VERSION "12.2.7"

NS_ :

BS_:

BU_: AMP CPD EASC HUD MHU XGW_Info PAS_Info PAS_LITE FCAM_Info

BO_ 676 SVC_EHC_EHC_2: 8 XGW_Info
  SG_ ID2 M : 0|8@1+ (1,0) [0|0] "" Vector__XXX,MHU
  SG_ ECU_ID_WUPREG m39 : 8|8@1+ (1,0) [0|127] "" Vector__XXX
  SG_ ID_FN_INQY m1 : 8|16@1+ (1,0) [0|0] "" Vector__XXX
  SG_ ID_FN_RQ_BUS m12 : 8|16@1+ (1,0) [0|0] "" Vector__XXX
  SG_ NO_CC_MESS_EXT m65 : 8|16@1+ (1,0) [0|65534] "" Vector__XXX
  SG_ NO_CC_MESS_STD m64 : 8|16@1+ (1,0) [0|65534] "" MHU,Vector__XXX
  SG_ WACA m39 : 16|8@1+ (1,0) [0|0] "" Vector__XXX
  SG_ ID_RQ_BUS m12 : 24|8@1+ (1,0) [0|0] "" Vector__XXX
  SG_ ST_CC_MESS_EXT m65 : 24|2@1+ (1,0) [0|0] "" Vector__XXX
  SG_ ST_CC_MESS_STD m64 : 24|2@1+ (1,0) [0|0] "" MHU
  SG_ TRANF_CC_MESS_EXT m65 : 26|4@1+ (1,0) [0|14] "" Vector__XXX
  SG_ TRANF_CC_MESS_STD m64 : 26|4@1+ (1,0) [0|14] "" MHU
  SG_ ST_IDC_CCLK_CC_MESS_EXT m65 : 30|2@1+ (1,0) [0|0] "" Vector__XXX
  SG_ ST_IDC_CCLK_CC_MESS_STD m64 : 30|2@1+ (1,0) [0|0] "" MHU
  SG_ NO_FRM_CC_MESS_EXT m65 : 32|4@1+ (1,0) [0|14] "" Vector__XXX
  SG_ ST_RQ_BUS m12 : 32|4@1+ (1,0) [0|0] "" Vector__XXX
  SG_ QUAN_FRM_CC_MESS_EXT m65 : 36|4@1+ (1,0) [0|14] "" Vector__XXX
  SG_ ST_LAW_RQ m12 : 36|4@1+ (1,0) [0|0] "" Vector__XXX
  SG_ DUR_FLLUPT m12 : 40|8@1+ (1,0) [0|254] "min" Vector__XXX
  SG_ UTDT_CC_MESS m65 : 40|24@1+ (1,0) [0|0] "" Vector__XXX

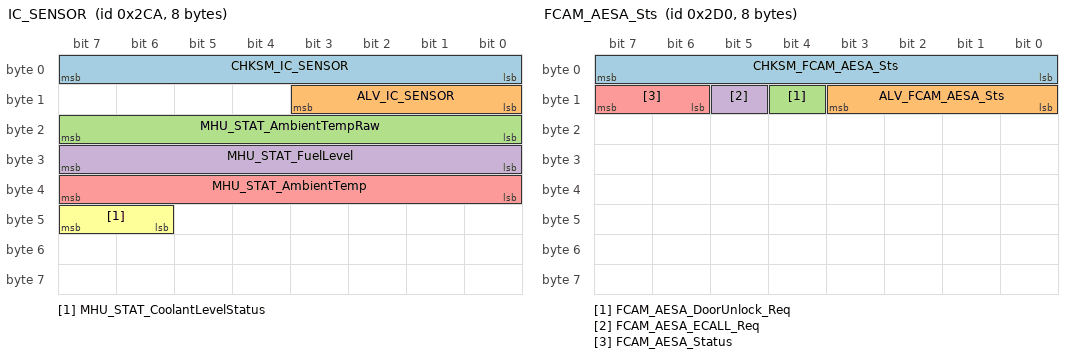
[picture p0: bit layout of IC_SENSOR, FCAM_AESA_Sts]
BO_ 714 IC_SENSOR: 8 MHU
  SG_ CHKSM_IC_SENSOR : 7|8@0+ (1,0) [0|255] "" AMP,CPD,EASC,HUD,XGW_Info,PAS_Info,FCAM_Info,PAS_LITE
  SG_ ALV_IC_SENSOR : 11|4@0+ (1,0) [0|14] "" AMP,CPD,EASC,HUD,XGW_Info,PAS_Info,FCAM_Info,PAS_LITE
  SG_ MHU_STAT_AmbientTempRaw : 23|8@0+ (0.5,-40) [-40|85] "°C" AMP,CPD,EASC,HUD,XGW_Info,PAS_Info,FCAM_Info
  SG_ MHU_STAT_FuelLevel : 31|8@0+ (1,0) [0|100] "l" AMP,CPD,EASC,HUD,XGW_Info,PAS_Info,FCAM_Info
  SG_ MHU_STAT_AmbientTemp : 39|8@0+ (0.5,-40) [-40|85] "Degree C" AMP,CPD,EASC,HUD,XGW_Info,PAS_Info,FCAM_Info,PAS_LITE
  SG_ MHU_STAT_CoolantLevelStatus : 47|2@0+ (1,0) [0|3] "-" AMP,CPD,EASC,HUD,XGW_Info,PAS_Info,FCAM_Info

BO_ 715 IC_TEMP: 8 XGW_Info
 SG_ TEMP_EX : 7|8@0+ (0.5,-40) [-40|85] "°C"  PAS_Info
 SG_ TEMP_EX_UNFILT : 15|8@0+ (0.5,-40) [-40|85] "°C"  PAS_Info

BO_ 717 MHU_ADASISv2_Message_Container: 8 MHU
 SG_ MHU_ADASISv2_Container : 7|64@0+ (1,0) [0|1.84467440737096E+019] ""  FCAM_Info

BO_ 720 FCAM_AESA_Sts: 8 FCAM_Info
 SG_ CHKSM_FCAM_AESA_Sts : 7|8@0+ (1,0) [0|255] ""  MHU,XGW_Info
 SG_ ALV_FCAM_AESA_Sts : 11|4@0+ (1,0) [0|14] ""  MHU,XGW_Info
 SG_ FCAM_AESA_DoorUnlock_Req : 12|1@0+ (1,0) [0|1] ""  XGW_Info
 SG_ FCAM_AESA_ECALL_Req : 13|1@0+ (1,0) [0|1] ""  MHU,XGW_Info
 SG_ FCAM_AESA_Status : 15|2@0+ (1,0) [0|3] ""  MHU,XGW_Info

BO_ 753 IC_STAT_AIRBAG: 1 MHU
  SG_ MHU_STAT_AirbagWarnLamp : 1|2@0+ (1,0) [0|3] "" XGW_Info

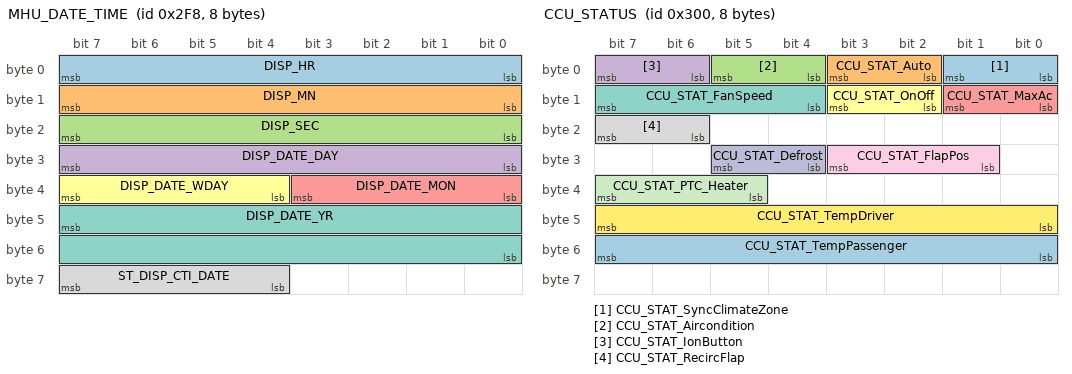
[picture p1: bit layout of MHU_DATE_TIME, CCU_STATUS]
BO_ 760 MHU_DATE_TIME: 8 MHU
  SG_ DISP_HR : 7|8@0+ (1,0) [0|23] "h" AMP,CPD,EASC,HUD,XGW_Info,PAS_Info,FCAM_Info,PAS_LITE
  SG_ DISP_MN : 15|8@0+ (1,0) [0|59] "min" AMP,CPD,EASC,HUD,XGW_Info,PAS_Info,FCAM_Info,PAS_LITE
  SG_ DISP_SEC : 23|8@0+ (1,0) [0|59] "s" AMP,CPD,EASC,HUD,XGW_Info,PAS_Info,FCAM_Info,PAS_LITE
  SG_ DISP_DATE_DAY : 31|8@0+ (1,0) [1|31] "Day" AMP,CPD,EASC,HUD,XGW_Info,PAS_Info,FCAM_Info,PAS_LITE
  SG_ DISP_DATE_MON : 35|4@0+ (1,0) [1|12] "Month" AMP,CPD,EASC,HUD,XGW_Info,PAS_Info,FCAM_Info,PAS_LITE
  SG_ DISP_DATE_WDAY : 39|4@0+ (1,0) [0|15] "" AMP,CPD,EASC,HUD,XGW_Info,PAS_Info,FCAM_Info
  SG_ DISP_DATE_YR : 47|16@0+ (1,0) [1|65534] "Year" AMP,CPD,EASC,HUD,XGW_Info,PAS_Info,FCAM_Info,PAS_LITE
  SG_ ST_DISP_CTI_DATE : 63|4@0+ (1,0) [0|15] "" AMP,CPD,FCAM_Info,EASC,HUD,PAS_Info,XGW_Info,PAS_LITE

BO_ 761 MHU_DATE_TIME_UTC: 8 MHU
  SG_ DISP_HR_UTC : 7|8@0+ (1,0) [0|23] "h" XGW_Info
  SG_ DISP_MN_UTC : 15|8@0+ (1,0) [0|59] "min" XGW_Info
  SG_ DISP_SEC_UTC : 23|8@0+ (1,0) [0|59] "s" XGW_Info
  SG_ DISP_DATE_DAY_UTC : 31|8@0+ (1,0) [1|31] "Day" XGW_Info
  SG_ DISP_DATE_MON_UTC : 35|4@0+ (1,0) [1|12] "Month" XGW_Info
  SG_ DISP_DATE_YR_UTC : 47|16@0+ (1,0) [1|65534] "Year" XGW_Info

BO_ 768 CCU_STATUS: 8 XGW_Info
  SG_ CCU_STAT_SyncClimateZone : 1|2@0+ (1,0) [0|3] "" MHU
  SG_ CCU_STAT_Auto : 3|2@0+ (1,0) [0|3] "-" MHU
  SG_ CCU_STAT_Aircondition : 5|2@0+ (1,0) [0|3] "" MHU
  SG_ CCU_STAT_IonButton : 7|2@0+ (1,0) [0|3] "" MHU
  SG_ CCU_STAT_MaxAc : 9|2@0+ (1,0) [0|3] "" MHU
  SG_ CCU_STAT_OnOff : 11|2@0+ (1,0) [0|3] "Bit" MHU
  SG_ CCU_STAT_FanSpeed : 15|4@0+ (1,0) [0|15] "" MHU
  SG_ CCU_STAT_RecircFlap : 23|2@0+ (1,0) [0|3] "" MHU
  SG_ CCU_STAT_FlapPos : 27|3@0+ (1,0) [0|7] "" MHU
  SG_ CCU_STAT_Defrost : 29|2@0+ (1,0) [0|3] "-" MHU
  SG_ CCU_STAT_PTC_Heater : 39|3@0+ (1,0) [0|7] "-" MHU
  SG_ CCU_STAT_TempDriver : 47|8@0+ (0.5,0) [16|32] "Degree C" MHU
  SG_ CCU_STAT_TempPassenger : 55|8@0+ (0.5,0) [16|32] "Degree C" MHU

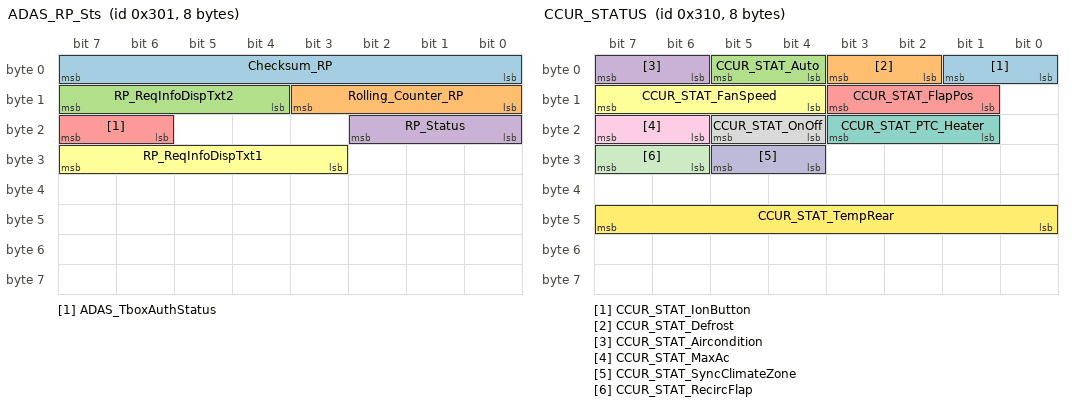
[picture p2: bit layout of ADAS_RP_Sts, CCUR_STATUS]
BO_ 769 ADAS_RP_Sts: 8 PAS_Info
  SG_ Checksum_RP : 7|8@0+ (1,0) [0|255] "" FCAM_Info,MHU
  SG_ Rolling_Counter_RP : 11|4@0+ (1,0) [0|14] "" FCAM_Info,MHU
  SG_ RP_ReqInfoDispTxt2 : 15|4@0+ (1,0) [0|15] "-" MHU
  SG_ RP_Status : 18|3@0+ (1,0) [0|7] "-" MHU,FCAM_Info,XGW_Info
  SG_ ADAS_TboxAuthStatus : 23|2@0+ (1,0) [0|3] "-" MHU
  SG_ RP_ReqInfoDispTxt1 : 31|5@0+ (1,0) [0|31] "-" MHU

BO_ 770 CCU_TEMP_PRESSURE: 6 XGW_Info
  SG_ CHKSM_CCU_TEMP_PRESSURE : 7|8@0+ (1,0) [0|255] "" Vector__XXX,AMP,CPD,EASC,HUD,MHU,PAS_Info,FCAM_Info
  SG_ ALV_CCU_TEMP_PRESSURE : 11|4@0+ (1,0) [0|14] "" Vector__XXX,AMP,CPD,EASC,HUD,MHU,PAS_Info,FCAM_Info
  SG_ CCU_Pressure_AC : 23|6@0+ (1,0) [0|62] "bar" Vector__XXX,AMP,CPD,EASC,HUD,MHU,PAS_Info,FCAM_Info
  SG_ CCU_InteriorTemp : 31|8@0+ (0.5,-40) [-40|85] "Degree C" Vector__XXX,AMP,CPD,EASC,HUD,MHU,PAS_Info,FCAM_Info
  SG_ CCU_TempEx_AC : 39|8@0+ (0.5,-40) [-40|85] "Degree C" Vector__XXX,AMP,CPD,EASC,HUD,MHU,PAS_Info,FCAM_Info
  SG_ CCU_EvaporatorTemp : 47|8@0+ (0.5,-40) [-40|85] "Degree C" Vector__XXX,AMP,CPD,EASC,HUD,MHU,PAS_Info,FCAM_Info

BO_ 773 BMS_Insulation: 8 XGW_Info
  SG_ CHSKM_BMS_Insulation : 7|8@0+ (1,0) [0|255] "" MHU
  SG_ ALV_BMS_Insulation : 11|4@0+ (1,0) [0|14] "" MHU
  SG_ BMS_VCU_Insulation_Mon_Sts : 15|1@0+ (1,0) [0|1] "" Vector__XXX
  SG_ BMS_PackInsuRes : 23|16@0+ (1,0) [0|60000] "kOhm" MHU

BO_ 775 CPD_OUTPUT: 3 CPD
  SG_ CHKSM_CPD_Output_1 : 7|8@0+ (1,0) [0|255] "" MHU,XGW_Info
  SG_ ALV_CPD_Output_1 : 11|4@0+ (1,0) [0|14] "" MHU,XGW_Info
  SG_ OUT_Alert_TO_BCM : 14|3@0+ (1,0) [0|7] "-" XGW_Info,MHU
  SG_ CPD_State_information : 20|3@0+ (1,0) [0|7] "-" MHU,XGW_Info
  SG_ OUT_Alert_TO_MHU : 23|3@0+ (1,0) [0|7] "-" MHU,XGW_Info

BO_ 776 MHU_CPD_Confirm: 8 MHU
  SG_ MHU_CPD_Setting : 4|3@0+ (1,0) [0|7] "-" CPD
  SG_ MHU_CPD_Confirmation_On_HMI : 7|3@0+ (1,0) [0|7] "-" CPD

BO_ 784 CCUR_STATUS: 8 XGW_Info
  SG_ CCUR_STAT_IonButton : 1|2@0+ (1,0) [0|3] "-" MHU
  SG_ CCUR_STAT_Defrost : 3|2@0+ (1,0) [0|3] "" MHU
  SG_ CCUR_STAT_Auto : 5|2@0+ (1,0) [0|3] "" MHU
  SG_ CCUR_STAT_Aircondition : 7|2@0+ (1,0) [0|3] "-" MHU
  SG_ CCUR_STAT_FlapPos : 11|3@0+ (1,0) [0|7] "-" MHU
  SG_ CCUR_STAT_FanSpeed : 15|4@0+ (1,0) [0|15] "-" MHU
  SG_ CCUR_STAT_PTC_Heater : 19|3@0+ (1,0) [0|7] "" MHU
  SG_ CCUR_STAT_OnOff : 21|2@0+ (1,0) [0|3] "Bit" MHU
  SG_ CCUR_STAT_MaxAc : 23|2@0+ (1,0) [0|3] "" MHU
  SG_ CCUR_STAT_SyncClimateZone : 29|2@0+ (1,0) [0|3] "-" MHU
  SG_ CCUR_STAT_RecircFlap : 31|2@0+ (1,0) [0|3] "-" MHU
  SG_ CCUR_STAT_TempRear : 47|8@0+ (0.5,0) [16|32] "Degree C" MHU

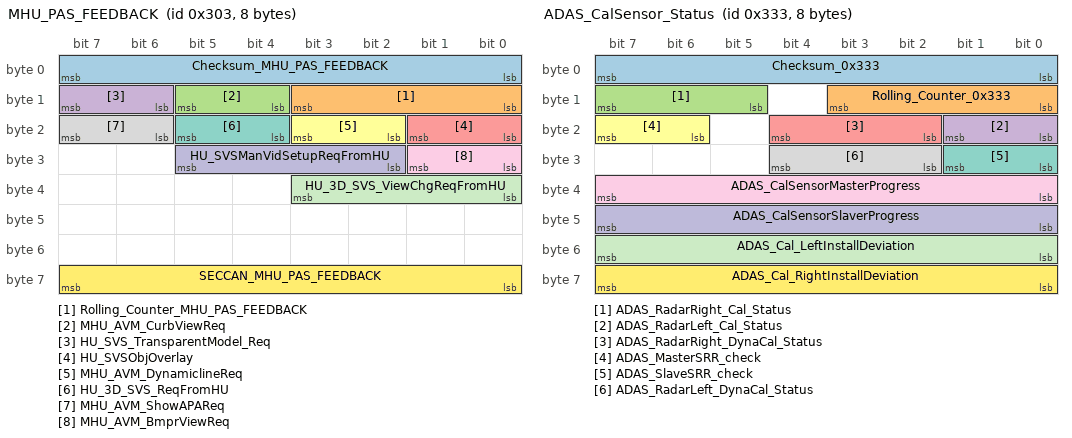
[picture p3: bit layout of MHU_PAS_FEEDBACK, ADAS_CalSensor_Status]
BO_ 771 MHU_PAS_FEEDBACK: 8 MHU
  SG_ Checksum_MHU_PAS_FEEDBACK : 7|8@0+ (1,0) [0|255] ""  PAS_Info
  SG_ Rolling_Counter_MHU_PAS_FEEDBACK : 11|4@0+ (1,0) [0|14] ""  PAS_Info
  SG_ MHU_AVM_CurbViewReq : 13|2@0+ (1,0) [0|3] ""  PAS_Info
  SG_ HU_SVS_TransparentModel_Req : 15|2@0+ (1,0) [0|3] ""  PAS_Info
  SG_ HU_SVSObjOverlay : 17|2@0+ (1,0) [0|3] ""  PAS_Info
  SG_ MHU_AVM_DynamiclineReq : 19|2@0+ (1,0) [0|3] ""  PAS_Info
  SG_ HU_3D_SVS_ReqFromHU : 21|2@0+ (1,0) [0|3] ""  PAS_Info
  SG_ MHU_AVM_ShowAPAReq : 23|2@0+ (1,0) [0|3] ""  PAS_Info
  SG_ MHU_AVM_BmprViewReq : 25|2@0+ (1,0) [0|3] ""  PAS_Info
  SG_ HU_SVSManVidSetupReqFromHU : 29|4@0+ (1,0) [0|15] ""  PAS_Info
  SG_ HU_3D_SVS_ViewChgReqFromHU : 35|4@0+ (1,0) [0|15] ""  PAS_Info
  SG_ SECCAN_MHU_PAS_FEEDBACK : 63|8@0+ (1,0) [0|255] ""  PAS_Info

BO_ 787 POD_StatusCharger1: 8 XGW_Info
  SG_ CHSKM_POD_StatusCharger1 : 7|8@0+ (1,0) [0|255] "" MHU
  SG_ ALV_POD_StatusCharger1 : 11|4@0+ (1,0) [0|14] "" MHU
  SG_ POD_statusOBC : 15|3@0+ (1,0) [0|7] "" MHU
  SG_ POD_OBC_Max_Current_Out : 23|8@0+ (1,0) [0|64] "A" MHU
  SG_ POD_iDCOut : 31|8@0+ (1,0) [0|64] "A" MHU
  SG_ POD_vDCOut : 39|16@0+ (0.0625,0) [0|512] "V" MHU

BO_ 803 POD_StatusCharger2: 8 XGW_Info
  SG_ CHSKM_POD_StatusCharger2 : 7|8@0+ (1,0) [0|255] "" MHU
  SG_ ALV_POD_StatusCharger2 : 11|4@0+ (1,0) [0|14] "" MHU
  SG_ POD_phaseACInput : 15|2@0+ (1,0) [0|3] "" MHU
  SG_ POD_iACInput : 23|16@0+ (0.0625,0) [0|60] "A" MHU
  SG_ POD_vACInput : 39|16@0+ (0.0625,0) [0|512] "V" MHU

BO_ 804 HOD_Heating: 2 MHU
  SG_ Steering_HeatingControl : 7|2@0+ (1,0) [0|3] "" XGW_Info

BO_ 805 STWH_Feedback: 2 XGW_Info
  SG_ Steering_HeatingControlFdbk : 7|2@0+ (1,0) [0|3] "-" MHU

BO_ 806 POD_StatusDCDC1: 8 XGW_Info
  SG_ CHSKM_POD_StatusDCDC1 : 7|8@0+ (1,0) [0|255] "" MHU
  SG_ ALV_POD_StatusDCDC1 : 11|4@0+ (1,0) [0|14] "" MHU
  SG_ POD_statusDCDC : 14|3@0+ (1,0) [0|7] "" MHU
  SG_ POD_DCDC_Max_Current_Out : 23|8@0+ (1,0) [0|250] "A" MHU

BO_ 807 POD_StatusFC: 8 XGW_Info
  SG_ CHKSM_POD_StatusFC : 7|8@0+ (1,0) [0|255] "" MHU
  SG_ ALV_POD_StatusFC : 11|4@0+ (1,0) [0|14] "" MHU
  SG_ POD_vFC : 23|16@0+ (0.0625,0) [0|512] "V" MHU
  SG_ POD_statusFCContactors : 47|3@0+ (1,0) [0|7] "" MHU

BO_ 808 IC_RELATIVIME: 6 MHU
  SG_ T_SEC_COU_REL : 7|32@0+ (1,0) [0|4294967294] "s" XGW_Info
  SG_ T_DAY_COU_ABSL : 39|16@0+ (1,0) [0|65534] "Day" XGW_Info

BO_ 809 BCM_ODO: 8 XGW_Info
  SG_ CRC_BCM_ODO : 7|8@0+ (1,0) [0|255] "" MHU
  SG_ ALIV_BCM_ODO : 11|4@0+ (1,0) [0|14] "" MHU
  SG_ Odometer_BCM : 23|20@0+ (1,0) [0|999999] "km" MHU
  SG_ SECCAN_BCM_ODO : 63|8@0+ (1,0) [0|255] "" MHU

BO_ 816 IC_MILEAGE: 8 XGW_Info
  SG_ MILE_KM : 7|24@0+ (1,0) [0|999999] "km" Vector__XXX,AMP,CPD,EASC,HUD,MHU,PAS_Info,FCAM_Info
  SG_ FLLV_FUTA : 31|8@0+ (1,0) [0|254] "l" Vector__XXX,AMP,CPD,EASC,HUD,MHU,PAS_Info,FCAM_Info
  SG_ RNG : 51|12@0+ (1,0) [0|4094] "km" Vector__XXX,AMP,CPD,EASC,HUD,MHU,PAS_Info,FCAM_Info
  SG_ ST_FLLV_FUTA_SPAR : 55|2@0+ (1,0) [0|3] "" Vector__XXX,AMP,CPD,EASC,HUD,MHU,PAS_Info,FCAM_Info

BO_ 818 BMS_PackInfo: 8 XGW_Info
 SG_ Checksum_0x332 : 7|8@0+ (1,0) [0|255] "" MHU
 SG_ Rolling_Counter_0x332 : 11|4@0+ (1,0) [0|14] "" MHU
 SG_ BMS_PackCNom : 23|16@0+ (0.1,0) [0|6553.5] "kWh" MHU
 SG_ BMS_PackTemp_0x332 : 39|8@0+ (1,-40) [-40|215] "Degree C" MHU

BO_ 819 ADAS_CalSensor_Status: 8 XGW_Info
 SG_ Checksum_0x333 : 7|8@0+ (1,0) [0|255] "" MHU
 SG_ Rolling_Counter_0x333 : 11|4@0+ (1,0) [0|15] "" MHU
 SG_ ADAS_RadarRight_Cal_Status : 15|3@0+ (1,0) [0|7] "" MHU
 SG_ ADAS_RadarLeft_Cal_Status : 17|2@0+ (1,0) [0|3] "" MHU
 SG_ ADAS_RadarRight_DynaCal_Status : 20|3@0+ (1,0) [0|7] "" MHU
 SG_ ADAS_MasterSRR_check : 23|2@0+ (1,0) [0|3] "" MHU
 SG_ ADAS_SlaveSRR_check : 25|2@0+ (1,0) [0|3] "" MHU
 SG_ ADAS_RadarLeft_DynaCal_Status : 28|3@0+ (1,0) [0|7] "" MHU
 SG_ ADAS_CalSensorMasterProgress : 39|8@0+ (0.4,0) [0|100] "%" MHU
 SG_ ADAS_CalSensorSlaverProgress : 47|8@0+ (0.4,0) [0|100] "%" MHU
 SG_ ADAS_Cal_LeftInstallDeviation : 55|8@0+ (0.1,-12.8) [-12.8|12.7] "deg" MHU
 SG_ ADAS_Cal_RightInstallDeviation : 63|8@0+ (0.1,-12.8) [-12.8|12.7] "deg" MHU

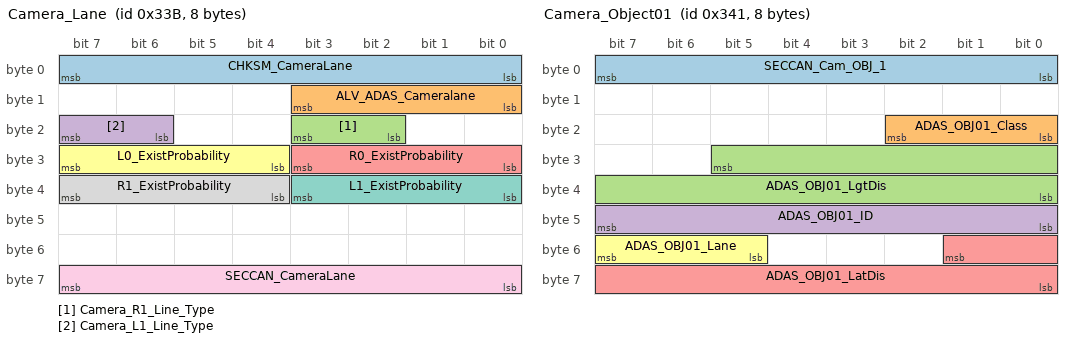
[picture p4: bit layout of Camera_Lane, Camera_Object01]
BO_ 827 Camera_Lane: 8 FCAM_Info
  SG_ CHKSM_CameraLane : 7|8@0+ (1,0) [0|255] "" MHU
  SG_ ALV_ADAS_Cameralane : 11|4@0+ (1,0) [0|14] "" MHU
  SG_ Camera_R1_Line_Type : 19|2@0+ (1,0) [0|3] "-" MHU
  SG_ Camera_L1_Line_Type : 23|2@0+ (1,0) [0|3] "-" MHU
  SG_ R0_ExistProbability : 27|4@0+ (0.1,0) [0|1] "-" MHU
  SG_ L0_ExistProbability : 31|4@0+ (0.1,0) [0|1] "-" MHU
  SG_ L1_ExistProbability : 35|4@0+ (0.1,0) [0|1] "-" MHU
  SG_ R1_ExistProbability : 39|4@0+ (0.1,0) [0|1] "-" MHU
  SG_ SECCAN_CameraLane : 63|8@0+ (1,0) [0|255] "" MHU

BO_ 833 Camera_Object01: 8 FCAM_Info
  SG_ SECCAN_Cam_OBJ_1 : 7|8@0+ (1,0) [0|255] "" MHU
  SG_ ADAS_OBJ01_Class : 18|3@0+ (1,0) [0|7] "-" MHU
  SG_ ADAS_OBJ01_LgtDis : 29|14@0+ (0.025,-10) [-10|399.575] "-" MHU
  SG_ ADAS_OBJ01_ID : 47|8@0+ (1,0) [0|255] "-" MHU
  SG_ ADAS_OBJ01_LatDis : 49|10@0+ (0.0293,-15.0146) [-15.0146|14.9593] "-" MHU
  SG_ ADAS_OBJ01_Lane : 55|3@0+ (1,0) [0|7] "-" MHU

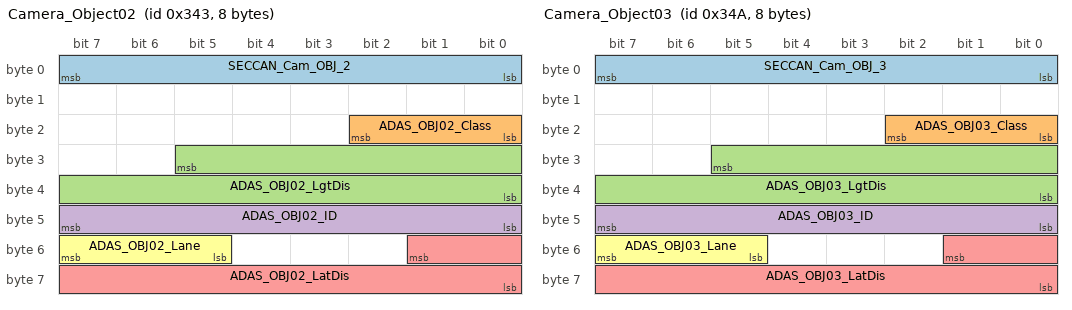
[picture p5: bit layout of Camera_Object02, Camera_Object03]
BO_ 835 Camera_Object02: 8 FCAM_Info
  SG_ SECCAN_Cam_OBJ_2 : 7|8@0+ (1,0) [0|255] "" MHU
  SG_ ADAS_OBJ02_Class : 18|3@0+ (1,0) [0|7] "-" MHU
  SG_ ADAS_OBJ02_LgtDis : 29|14@0+ (0.025,-10) [-10|399.575] "-" MHU
  SG_ ADAS_OBJ02_ID : 47|8@0+ (1,0) [0|255] "-" MHU
  SG_ ADAS_OBJ02_LatDis : 49|10@0+ (0.0293,-15.0146) [-15.0146|14.985] "-" MHU
  SG_ ADAS_OBJ02_Lane : 55|3@0+ (1,0) [0|7] "-" MHU

BO_ 838 POD_StatusDCDC2: 8 XGW_Info
  SG_ CHSKM_POD_StatusDCDC2 : 7|8@0+ (1,0) [0|255] "" MHU
  SG_ ALV_POD_StatusDCDC2 : 11|4@0+ (1,0) [0|14] "" MHU
  SG_ POD_vDCInput : 23|16@0+ (0.0625,0) [0|512] "V" MHU
  SG_ POD_iDCDCOutput : 39|16@0+ (0.0625,0) [0|300] "A" MHU
  SG_ POD_vDCDCOutput : 55|16@0+ (0.0625,0) [0|18] "V" MHU

BO_ 840 EDS_Sts_FR: 8 XGW_Info
  SG_ EDS_HVIL_STS_FWD : 25|2@0+ (1,0) [0|3] ""  MHU

BO_ 841 EDS_R_Sts_RR: 8 XGW_Info
  SG_ EDS_HVIL_STS_RWD : 25|2@0+ (1,0) [0|3] ""  MHU

BO_ 842 Camera_Object03: 8 FCAM_Info
  SG_ SECCAN_Cam_OBJ_3 : 7|8@0+ (1,0) [0|255] "" MHU
  SG_ ADAS_OBJ03_Class : 18|3@0+ (1,0) [0|7] "-" MHU
  SG_ ADAS_OBJ03_LgtDis : 29|14@0+ (0.025,-10) [-10|399.575] "-" MHU
  SG_ ADAS_OBJ03_ID : 47|8@0+ (1,0) [0|255] "-" MHU
  SG_ ADAS_OBJ03_LatDis : 49|10@0+ (0.0293,-15.0146) [-15.0146|14.985] "-" MHU
  SG_ ADAS_OBJ03_Lane : 55|3@0+ (1,0) [0|7] "-" MHU

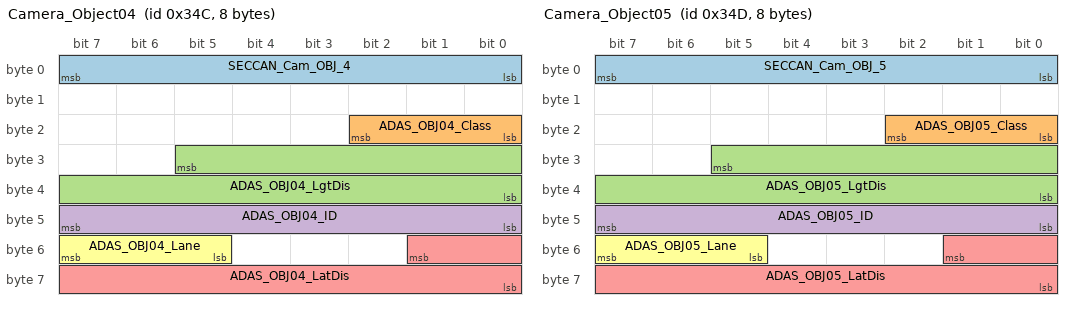
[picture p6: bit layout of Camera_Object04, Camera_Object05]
BO_ 844 Camera_Object04: 8 FCAM_Info
  SG_ SECCAN_Cam_OBJ_4 : 7|8@0+ (1,0) [0|255] "" MHU
  SG_ ADAS_OBJ04_Class : 18|3@0+ (1,0) [0|7] "-" MHU
  SG_ ADAS_OBJ04_LgtDis : 29|14@0+ (0.025,-10) [-10|399.575] "-" MHU
  SG_ ADAS_OBJ04_ID : 47|8@0+ (1,0) [0|255] "-" MHU
  SG_ ADAS_OBJ04_LatDis : 49|10@0+ (0.0293,-15.0146) [-15.0146|14.985] "-" MHU
  SG_ ADAS_OBJ04_Lane : 55|3@0+ (1,0) [0|7] "-" MHU

BO_ 845 Camera_Object05: 8 FCAM_Info
  SG_ SECCAN_Cam_OBJ_5 : 7|8@0+ (1,0) [0|255] "" MHU
  SG_ ADAS_OBJ05_Class : 18|3@0+ (1,0) [0|7] "-" MHU
  SG_ ADAS_OBJ05_LgtDis : 29|14@0+ (0.025,-10) [-10|399.575] "-" MHU
  SG_ ADAS_OBJ05_ID : 47|8@0+ (1,0) [0|255] "-" MHU
  SG_ ADAS_OBJ05_LatDis : 49|10@0+ (0.0293,-15.0146) [-15.0146|14.985] "-" MHU
  SG_ ADAS_OBJ05_Lane : 55|3@0+ (1,0) [0|7] "-" MHU

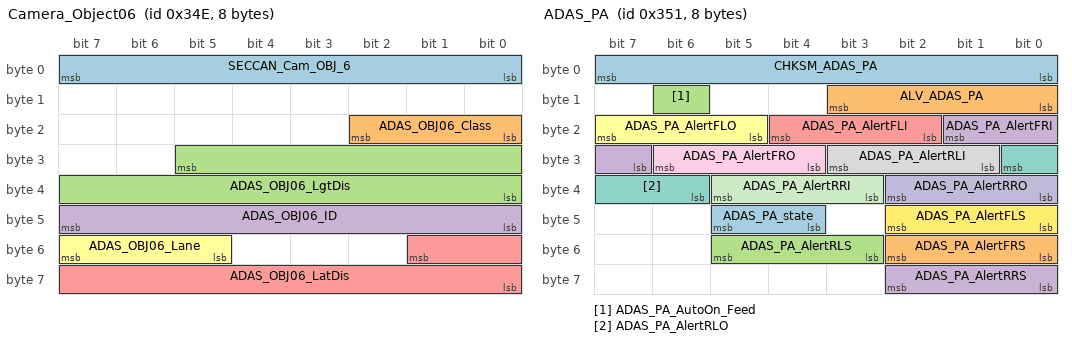
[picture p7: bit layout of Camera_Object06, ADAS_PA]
BO_ 846 Camera_Object06: 8 FCAM_Info
  SG_ SECCAN_Cam_OBJ_6 : 7|8@0+ (1,0) [0|255] "" MHU
  SG_ ADAS_OBJ06_Class : 18|3@0+ (1,0) [0|7] "-" MHU
  SG_ ADAS_OBJ06_LgtDis : 29|14@0+ (0.025,-10) [-10|399.575] "-" MHU
  SG_ ADAS_OBJ06_ID : 47|8@0+ (1,0) [0|255] "-" MHU
  SG_ ADAS_OBJ06_LatDis : 49|10@0+ (0.0293,-15.0146) [-15.0146|14.985] "-" MHU
  SG_ ADAS_OBJ06_Lane : 55|3@0+ (1,0) [0|7] "-" MHU

BO_ 849 ADAS_PA: 8 PAS_Info
  SG_ CHKSM_ADAS_PA : 7|8@0+ (1,0) [0|255] "" HUD,MHU
  SG_ ALV_ADAS_PA : 11|4@0+ (1,0) [0|14] "" HUD,MHU
  SG_ ADAS_PA_AutoOn_Feed : 14|1@0+ (1,0) [0|1] "-" HUD,MHU
  SG_ ADAS_PA_AlertFRI : 17|3@0+ (1,0) [0|7] "-" HUD,MHU
  SG_ ADAS_PA_AlertFLI : 20|3@0+ (1,0) [0|7] "-" HUD,MHU
  SG_ ADAS_PA_AlertFLO : 23|3@0+ (1,0) [0|7] "-" HUD,MHU
  SG_ ADAS_PA_AlertRLO : 24|3@0+ (1,0) [0|7] "-" HUD,MHU
  SG_ ADAS_PA_AlertRLI : 27|3@0+ (1,0) [0|7] "-" HUD,MHU
  SG_ ADAS_PA_AlertFRO : 30|3@0+ (1,0) [0|7] "-" HUD,MHU
  SG_ ADAS_PA_AlertRRO : 34|3@0+ (1,0) [0|7] "-" HUD,MHU
  SG_ ADAS_PA_AlertRRI : 37|3@0+ (1,0) [0|7] "-" HUD,MHU
  SG_ ADAS_PA_AlertFLS : 42|3@0+ (1,0) [0|7] ""  HUD,MHU
  SG_ ADAS_PA_state : 45|2@0+ (1,0) [0|3] "-" HUD,MHU
  SG_ ADAS_PA_AlertFRS : 50|3@0+ (1,0) [0|7] ""  HUD,MHU
  SG_ ADAS_PA_AlertRLS : 53|3@0+ (1,0) [0|7] ""  HUD,MHU
  SG_ ADAS_PA_AlertRRS : 58|3@0+ (1,0) [0|7] ""  HUD,MHU

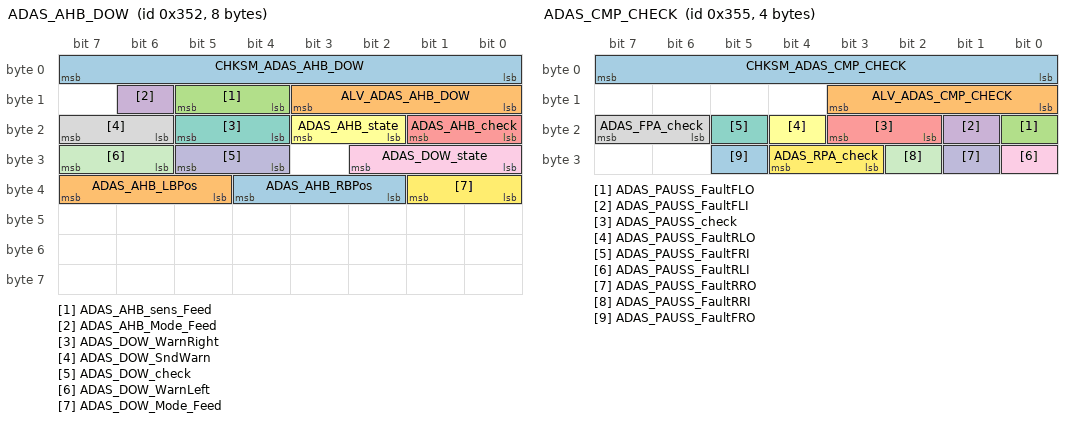
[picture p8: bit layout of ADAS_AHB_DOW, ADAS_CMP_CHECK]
BO_ 850 ADAS_AHB_DOW: 8 FCAM_Info
  SG_ CHKSM_ADAS_AHB_DOW : 7|8@0+ (1,0) [0|255] "" HUD,MHU,XGW_Info
  SG_ ALV_ADAS_AHB_DOW : 11|4@0+ (1,0) [0|14] "" HUD,MHU,XGW_Info
  SG_ ADAS_AHB_sens_Feed : 13|2@0+ (1,0) [0|3] "-" MHU
  SG_ ADAS_AHB_Mode_Feed : 14|1@0+ (1,0) [0|1] "-" MHU
  SG_ ADAS_AHB_check : 17|2@0+ (1,0) [0|3] "-" MHU,XGW_Info
  SG_ ADAS_AHB_state : 19|2@0+ (1,0) [0|3] "-" XGW_Info
  SG_ ADAS_DOW_WarnRight : 21|2@0+ (1,0) [0|3] "-" MHU,XGW_Info
  SG_ ADAS_DOW_SndWarn : 23|2@0+ (1,0) [0|3] "-" MHU
  SG_ ADAS_DOW_state : 26|3@0+ (1,0) [0|7] "-" MHU
  SG_ ADAS_DOW_check : 29|2@0+ (1,0) [0|3] "-" MHU
  SG_ ADAS_DOW_WarnLeft : 31|2@0+ (1,0) [0|3] "-" MHU,XGW_Info
  SG_ ADAS_DOW_Mode_Feed : 33|2@0+ (1,0) [0|3] "-" MHU
  SG_ ADAS_AHB_RBPos : 36|3@0+ (1,0) [0|7] "" MHU,XGW_Info
  SG_ ADAS_AHB_LBPos : 39|3@0+ (1,0) [0|7] "-" MHU,XGW_Info

BO_ 851 ADAS_CMP_ACC: 8 FCAM_Info
  SG_ CHKSM_ADAS_ACC : 7|8@0+ (1,0) [0|255] "" HUD,MHU,PAS_Info
  SG_ ALV_ADAS_ACC : 11|4@0+ (1,0) [0|14] "" HUD,MHU,PAS_Info
  SG_ ADAS_ACC_ObjDetec : 12|1@0+ (1,0) [0|1] "-" HUD,MHU
  SG_ ADAS_ISA_check : 14|2@0+ (1,0) [0|3] "-" HUD,MHU
  SG_ ADAS_ISA_Mode_SW_Feed : 15|1@0+ (1,0) [0|1] "-" HUD,MHU
  SG_ ADAS_TagSpeed_ICON_Feed : 18|3@0+ (1,0) [0|7] "-" HUD,MHU
  SG_ ADAS_ISA_PopUp_Feed : 23|4@0+ (1,0) [0|15] "-" HUD,MHU
  SG_ ADAS_ISA_Btn_Feed : 24|1@0+ (1,0) [0|1] "-" HUD,MHU
  SG_ ADAS_ACC_DistSet_upper_Feed : 25|1@0+ (1,0) [0|1] "-" HUD,MHU
  SG_ ADAS_ACC_TimeGapSet : 28|3@0+ (1,0) [0|7] "-" HUD,MHU
  SG_ ADAS_ACC_State : 31|3@0+ (1,0) [0|7] "-" HUD,MHU,PAS_Info,XGW_Info
  SG_ ADAS_ACC_TagSpeed : 39|8@0+ (1,0) [0|255] "km/h" HUD,MHU
  SG_ ADAS_ACC_PopUp_Feed : 43|4@0+ (1,0) [0|15] "-" HUD,MHU
  SG_ ADAS_ACC_check : 47|2@0+ (1,0) [0|3] "-" HUD,MHU,XGW_Info
  SG_ ADAS_ISA_ICON_Feed : 50|3@0+ (1,0) [0|7] "-" HUD,MHU
  SG_ ADAS_ACC_DistSet_lower_Feed : 51|1@0+ (1,0) [0|1] "-" HUD,MHU
  SG_ ADAS_ACC_SpdSet_upper_Feed : 52|1@0+ (1,0) [0|1] "-" HUD,MHU
  SG_ ADAS_ACC_SpdSet_lower_Feed : 53|1@0+ (1,0) [0|1] "-" HUD,MHU
  SG_ ADAS_ACC_On_Feed : 54|1@0+ (1,0) [0|1] "-" HUD,MHU
  SG_ ADAS_ACC_Set_Feed : 55|1@0+ (1,0) [0|1] "-" HUD,MHU
  SG_ ADAS_ACC_CnlBtn_Feed : 56|1@0+ (1,0) [0|1] "-" HUD,MHU
  SG_ ADAS_ACC_Res_Feed : 57|1@0+ (1,0) [0|1] "-" HUD,MHU
  SG_ ADAS_ACC_ICON_Feed : 60|3@0+ (1,0) [0|7] "-" HUD,MHU
  SG_ ADAS_ISA_Status : 63|3@0+ (1,0) [0|7] "-" HUD,MHU

BO_ 852 MHU_ADAS_req: 8 MHU
  SG_ CHKSM_MHU_ADAS_req : 7|8@0+ (1,0) [0|255] "" XGW_Info,FCAM_Info,PAS_Info,PAS_LITE
  SG_ ALV_MHU_ADAS_req : 11|4@0+ (1,0) [0|14] "" XGW_Info,FCAM_Info,PAS_Info,PAS_LITE
  SG_ MHU_RAEB_Mode : 13|2@0+ (1,0) [0|3] "-" XGW_Info,PAS_Info,FCAM_Info
  SG_ MHU_LA_AudWarning : 15|2@0+ (1,0) [0|3] "-" XGW_Info,FCAM_Info
  SG_ MHU_BSD_On : 17|2@0+ (1,0) [0|3] "-" XGW_Info,FCAM_Info
  SG_ MHU_BSD_sens : 19|2@0+ (1,0) [0|3] "" XGW_Info,FCAM_Info
  SG_ MHU_BSD_AudWarning : 21|2@0+ (1,0) [0|3] "-" XGW_Info,FCAM_Info
  SG_ MHU_RCTA_On : 23|2@0+ (1,0) [0|3] "-" XGW_Info,FCAM_Info
  SG_ MHU_RCTA_sens : 25|2@0+ (1,0) [0|3] "-" XGW_Info,FCAM_Info
  SG_ MHU_PA_On : 27|2@0+ (1,0) [0|3] "-" XGW_Info,FCAM_Info,PAS_Info,PAS_LITE
  SG_ MHU_AHB_On : 29|2@0+ (1,0) [0|3] "-" XGW_Info,FCAM_Info
  SG_ MHU_IA_Mode : 31|2@0+ (1,0) [0|3] "-" XGW_Info,FCAM_Info
  SG_ MHU_TSR_Mode : 33|2@0+ (1,0) [0|3] "-" XGW_Info,FCAM_Info
  SG_ MHU_DOW_Mode : 35|2@0+ (1,0) [0|3] "-" XGW_Info,FCAM_Info
  SG_ MHU_AHB_sens : 37|2@0+ (1,0) [0|3] "-" XGW_Info,FCAM_Info
  SG_ MHU_FCW_sens : 39|2@0+ (1,0) [0|3] "-" XGW_Info,FCAM_Info
  SG_ MHU_LA_Mode : 41|3@0+ (1,0) [0|7] "-" XGW_Info,FCAM_Info
  SG_ MHU_FCW_Mode : 43|2@0+ (1,0) [0|3] "-" XGW_Info,FCAM_Info
  SG_ MHU_SET_TSR_AudWarn : 45|2@0+ (1,0) [0|3] "-" XGW_Info,FCAM_Info
  SG_ MHU_SET_TSR_SLAert : 47|2@0+ (1,0) [0|3] "-" XGW_Info,FCAM_Info
  SG_ MHU_LA_sens : 49|2@0+ (1,0) [0|3] "-" XGW_Info,FCAM_Info
  SG_ MHU_AEB_Mode : 51|2@0+ (1,0) [0|3] "-" XGW_Info,FCAM_Info
  SG_ MHU_ESA_ON : 54|1@0+ (1,0) [0|1] ""  XGW_Info,FCAM_Info
  SG_ MHU_ELKA_ON : 56|1@0+ (1,0) [0|1] ""  XGW_Info,FCAM_Info
  SG_ MHU_ALC_ON : 58|2@0+ (1,0) [0|3] ""  FCAM_Info

BO_ 853 ADAS_CMP_CHECK: 4 PAS_Info
  SG_ CHKSM_ADAS_CMP_CHECK : 7|8@0+ (1,0) [0|255] "" MHU
  SG_ ALV_ADAS_CMP_CHECK : 11|4@0+ (1,0) [0|14] "" MHU
  SG_ ADAS_PAUSS_FaultFLO : 16|1@0+ (1,0) [0|1] "-" MHU
  SG_ ADAS_PAUSS_FaultFLI : 17|1@0+ (1,0) [0|1] "-" MHU
  SG_ ADAS_PAUSS_check : 19|2@0+ (1,0) [0|3] "-" MHU
  SG_ ADAS_PAUSS_FaultRLO : 20|1@0+ (1,0) [0|1] "-" MHU
  SG_ ADAS_PAUSS_FaultFRI : 21|1@0+ (1,0) [0|1] "-" MHU
  SG_ ADAS_FPA_check : 23|2@0+ (1,0) [0|3] "-" MHU
  SG_ ADAS_PAUSS_FaultRLI : 24|1@0+ (1,0) [0|1] "-" MHU
  SG_ ADAS_PAUSS_FaultRRO : 25|1@0+ (1,0) [0|1] "-" MHU
  SG_ ADAS_PAUSS_FaultRRI : 26|1@0+ (1,0) [0|1] "-" MHU
  SG_ ADAS_RPA_check : 28|2@0+ (1,0) [0|3] "-" MHU
  SG_ ADAS_PAUSS_FaultFRO : 29|1@0+ (1,0) [0|1] "-" MHU

BO_ 880 MHU_SBR_Status: 8 MHU
  SG_ CRC_MHU_SBR_Status : 7|8@0+ (1,0) [0|255] "" XGW_Info
  SG_ ALV_MHU_SBR_Status : 11|4@0+ (1,0) [0|14] "" XGW_Info
  SG_ SBR_STAT_Chime : 13|2@0+ (1,0) [0|3] "" XGW_Info
  SG_ SBR_STAT_Telltale : 15|2@0+ (1,0) [0|3] "" XGW_Info
  SG_ SBR_STAT_Active : 16|1@0+ (1,0) [0|1] "" XGW_Info

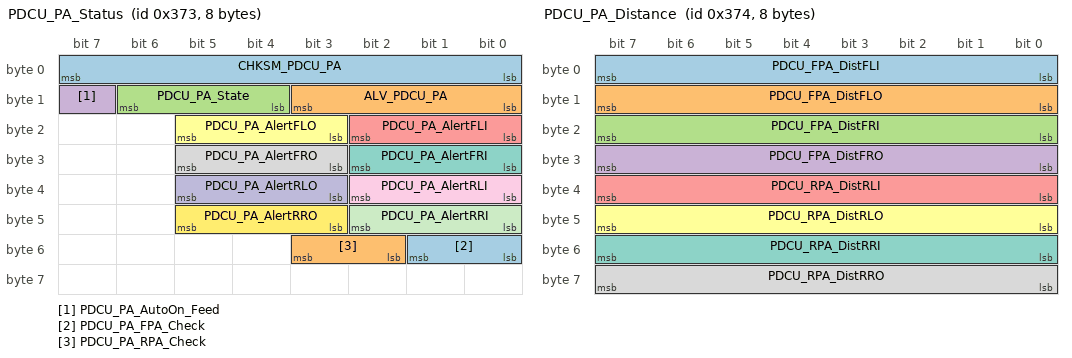
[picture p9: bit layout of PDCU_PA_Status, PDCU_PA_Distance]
BO_ 883 PDCU_PA_Status: 8 PAS_LITE
 SG_ CHKSM_PDCU_PA : 7|8@0+ (1,0) [0|255] ""  MHU
 SG_ ALV_PDCU_PA : 11|4@0+ (1,0) [0|14] ""  MHU
 SG_ PDCU_PA_State : 14|3@0+ (1,0) [0|7] ""  MHU
 SG_ PDCU_PA_AutoOn_Feed : 15|1@0+ (1,0) [0|1] ""  MHU
 SG_ PDCU_PA_AlertFLI : 18|3@0+ (1,0) [0|7] ""  MHU
 SG_ PDCU_PA_AlertFLO : 21|3@0+ (1,0) [0|7] ""  MHU
 SG_ PDCU_PA_AlertFRI : 26|3@0+ (1,0) [0|7] ""  MHU
 SG_ PDCU_PA_AlertFRO : 29|3@0+ (1,0) [0|7] ""  MHU
 SG_ PDCU_PA_AlertRLI : 34|3@0+ (1,0) [0|7] ""  MHU
 SG_ PDCU_PA_AlertRLO : 37|3@0+ (1,0) [0|7] ""  MHU
 SG_ PDCU_PA_AlertRRI : 42|3@0+ (1,0) [0|7] ""  MHU
 SG_ PDCU_PA_AlertRRO : 45|3@0+ (1,0) [0|7] ""  MHU
 SG_ PDCU_PA_FPA_Check : 49|2@0+ (1,0) [0|3] ""  MHU
 SG_ PDCU_PA_RPA_Check : 51|2@0+ (1,0) [0|3] ""  MHU

BO_ 884 PDCU_PA_Distance: 8 PAS_LITE
 SG_ PDCU_FPA_DistFLI : 7|8@0+ (1,0) [0|255] "cm"  MHU
 SG_ PDCU_FPA_DistFLO : 15|8@0+ (1,0) [0|255] "cm"  MHU
 SG_ PDCU_FPA_DistFRI : 23|8@0+ (1,0) [0|255] "cm"  MHU
 SG_ PDCU_FPA_DistFRO : 31|8@0+ (1,0) [0|255] "cm"  MHU
 SG_ PDCU_RPA_DistRLI : 39|8@0+ (1,0) [0|255] "cm"  MHU
 SG_ PDCU_RPA_DistRLO : 47|8@0+ (1,0) [0|255] "cm"  MHU
 SG_ PDCU_RPA_DistRRI : 55|8@0+ (1,0) [0|255] "cm"  MHU
 SG_ PDCU_RPA_DistRRO : 63|8@0+ (1,0) [0|255] "cm"  MHU

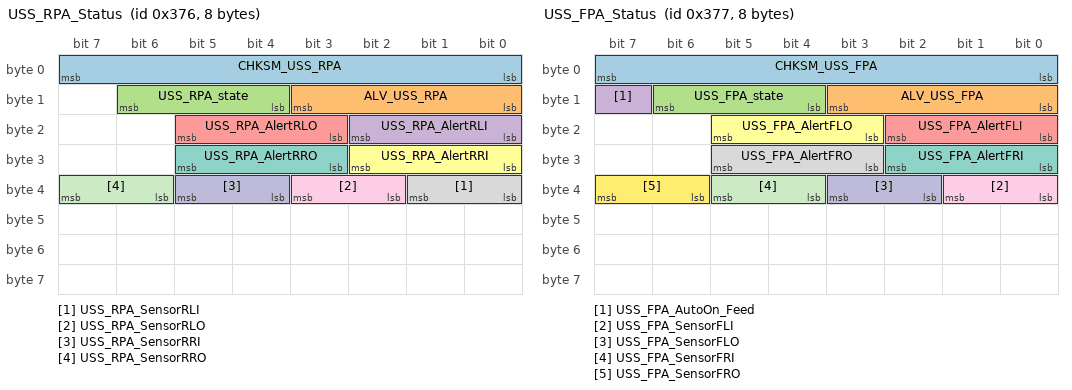
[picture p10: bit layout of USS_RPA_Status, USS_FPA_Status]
BO_ 886 USS_RPA_Status: 8 XGW_Info
 SG_ CHKSM_USS_RPA : 7|8@0+ (1,0) [0|255] ""  MHU
 SG_ ALV_USS_RPA : 11|4@0+ (1,0) [0|14] ""  MHU
 SG_ USS_RPA_state : 14|3@0+ (1,0) [1|7] ""  MHU
 SG_ USS_RPA_AlertRLI : 18|3@0+ (1,0) [0|7] ""  MHU
 SG_ USS_RPA_AlertRLO : 21|3@0+ (1,0) [0|7] ""  MHU
 SG_ USS_RPA_AlertRRI : 26|3@0+ (1,0) [0|7] ""  MHU
 SG_ USS_RPA_AlertRRO : 29|3@0+ (1,0) [0|7] ""  MHU
 SG_ USS_RPA_SensorRLI : 33|2@0+ (1,0) [0|3] ""  MHU
 SG_ USS_RPA_SensorRLO : 35|2@0+ (1,0) [0|3] ""  MHU
 SG_ USS_RPA_SensorRRI : 37|2@0+ (1,0) [0|3] ""  MHU
 SG_ USS_RPA_SensorRRO : 39|2@0+ (1,0) [0|3] ""  MHU

BO_ 887 USS_FPA_Status: 8 XGW_Info
 SG_ CHKSM_USS_FPA : 7|8@0+ (1,0) [0|255] ""  MHU
 SG_ ALV_USS_FPA : 11|4@0+ (1,0) [0|14] ""  MHU
 SG_ USS_FPA_state : 14|3@0+ (1,0) [1|7] ""  MHU
 SG_ USS_FPA_AutoOn_Feed : 15|1@0+ (1,0) [0|1] ""  MHU
 SG_ USS_FPA_AlertFLI : 18|3@0+ (1,0) [0|7] ""  MHU
 SG_ USS_FPA_AlertFLO : 21|3@0+ (1,0) [0|7] ""  MHU
 SG_ USS_FPA_AlertFRI : 26|3@0+ (1,0) [0|7] ""  MHU
 SG_ USS_FPA_AlertFRO : 29|3@0+ (1,0) [0|7] ""  MHU
 SG_ USS_FPA_SensorFLI : 33|2@0+ (1,0) [0|3] ""  MHU
 SG_ USS_FPA_SensorFLO : 35|2@0+ (1,0) [0|3] ""  MHU
 SG_ USS_FPA_SensorFRI : 37|2@0+ (1,0) [0|3] ""  MHU
 SG_ USS_FPA_SensorFRO : 39|2@0+ (1,0) [0|3] ""  MHU

BO_ 888 USS_RPA_Distance: 8 XGW_Info
 SG_ CHKSM_RawDist_RPA : 7|8@0+ (1,0) [0|255] ""  MHU
 SG_ ALV_RawDist_RPA : 11|4@0+ (1,0) [0|14] ""  MHU
 SG_ USS_RPA_DistRLI : 23|8@0+ (1,0) [0|255] "cm"  MHU
 SG_ USS_RPA_DistRLO : 31|8@0+ (1,0) [0|255] "cm"  MHU
 SG_ USS_RPA_DistRRI : 39|8@0+ (1,0) [0|255] "cm"  MHU
 SG_ USS_RPA_DistRRO : 47|8@0+ (1,0) [0|255] "cm"  MHU

BO_ 889 USS_FPA_Distance: 8 XGW_Info
 SG_ CHKSM_RawDist_FPA : 7|8@0+ (1,0) [0|255] ""  MHU
 SG_ ALV_RawDist_FPA : 11|4@0+ (1,0) [0|14] ""  MHU
 SG_ USS_FPA_DistFLI : 23|8@0+ (1,0) [0|255] "cm"  MHU
 SG_ USS_FPA_DistFLO : 31|8@0+ (1,0) [0|255] "cm"  MHU
 SG_ USS_FPA_DistFRI : 39|8@0+ (1,0) [0|255] "cm"  MHU
 SG_ USS_FPA_DistFRO : 47|8@0+ (1,0) [0|255] "cm"  MHU

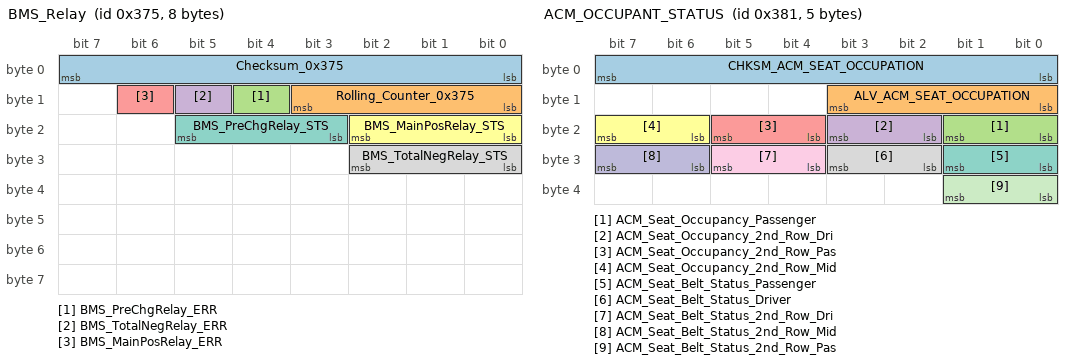
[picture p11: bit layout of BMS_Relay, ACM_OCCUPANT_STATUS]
BO_ 885 BMS_Relay: 8 XGW_Info
  SG_ Checksum_0x375 : 7|8@0+ (1,0) [0|255] "" MHU
  SG_ Rolling_Counter_0x375 : 11|4@0+ (1,0) [0|14] "" MHU
  SG_ BMS_PreChgRelay_ERR : 12|1@0+ (1,0) [0|1] "" MHU
  SG_ BMS_TotalNegRelay_ERR : 13|1@0+ (1,0) [0|1] "" MHU
  SG_ BMS_MainPosRelay_ERR : 14|1@0+ (1,0) [0|1] "" MHU
  SG_ BMS_MainPosRelay_STS : 18|3@0+ (1,0) [0|7] "" MHU
  SG_ BMS_PreChgRelay_STS : 21|3@0+ (1,0) [0|7] "" MHU
  SG_ BMS_TotalNegRelay_STS : 26|3@0+ (1,0) [0|7] "" MHU

BO_ 896 BCM_VEHICLE_IDENT_NUMBER: 8 XGW_Info
  SG_ VIN_Byte1 : 7|8@0+ (1,0) [0|255] "" Vector__XXX,AMP,CPD,EASC,HUD,MHU,PAS_Info,FCAM_Info
  SG_ VIN_Byte2 : 15|8@0+ (1,0) [0|255] "" Vector__XXX,AMP,CPD,EASC,HUD,MHU,PAS_Info,FCAM_Info
  SG_ VIN_Byte3 : 23|8@0+ (1,0) [0|255] "" Vector__XXX,AMP,CPD,EASC,HUD,MHU,PAS_Info,FCAM_Info
  SG_ VIN_Byte4 : 31|8@0+ (1,0) [0|255] "" Vector__XXX,AMP,CPD,EASC,HUD,MHU,PAS_Info,FCAM_Info
  SG_ VIN_Byte5 : 39|8@0+ (1,0) [0|255] "" Vector__XXX,AMP,CPD,EASC,HUD,MHU,PAS_Info,FCAM_Info
  SG_ VIN_Byte6 : 47|8@0+ (1,0) [0|255] "" Vector__XXX,AMP,CPD,EASC,HUD,MHU,PAS_Info,FCAM_Info
  SG_ VIN_Byte7 : 55|8@0+ (1,0) [0|255] "" Vector__XXX,AMP,CPD,EASC,HUD,MHU,PAS_Info,FCAM_Info

BO_ 897 ACM_OCCUPANT_STATUS: 5 XGW_Info
  SG_ CHKSM_ACM_SEAT_OCCUPATION : 7|8@0+ (1,0) [0|255] "" FCAM_Info,MHU,PAS_Info
  SG_ ALV_ACM_SEAT_OCCUPATION : 11|4@0+ (1,0) [0|14] "" FCAM_Info,MHU,PAS_Info
  SG_ ACM_Seat_Occupancy_Passenger : 17|2@0+ (1,0) [0|3] "" MHU
  SG_ ACM_Seat_Occupancy_2nd_Row_Dri : 19|2@0+ (1,0) [0|3] "" MHU
  SG_ ACM_Seat_Occupancy_2nd_Row_Pas : 21|2@0+ (1,0) [0|3] "-" MHU
  SG_ ACM_Seat_Occupancy_2nd_Row_Mid : 23|2@0+ (1,0) [0|3] "-" MHU
  SG_ ACM_Seat_Belt_Status_Passenger : 25|2@0+ (1,0) [0|3] "" FCAM_Info,MHU
  SG_ ACM_Seat_Belt_Status_Driver : 27|2@0+ (1,0) [0|3] "" FCAM_Info,MHU,PAS_Info
  SG_ ACM_Seat_Belt_Status_2nd_Row_Dri : 29|2@0+ (1,0) [0|3] "-" MHU
  SG_ ACM_Seat_Belt_Status_2nd_Row_Mid : 31|2@0+ (1,0) [0|3] "" MHU
  SG_ ACM_Seat_Belt_Status_2nd_Row_Pas : 33|2@0+ (1,0) [0|3] "-" MHU

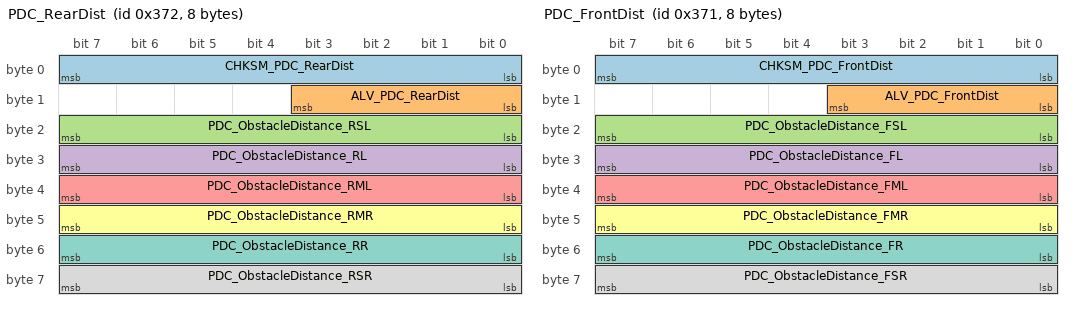
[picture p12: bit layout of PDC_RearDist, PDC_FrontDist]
BO_ 882 PDC_RearDist: 8 PAS_Info
  SG_ CHKSM_PDC_RearDist : 7|8@0+ (1,0) [0|255] ""  MHU
  SG_ ALV_PDC_RearDist : 11|4@0+ (1,0) [0|15] ""  MHU
  SG_ PDC_ObstacleDistance_RSL : 23|8@0+ (1,0) [0|255] "cm"  MHU
  SG_ PDC_ObstacleDistance_RL : 31|8@0+ (1,0) [0|255] "cm"  MHU
  SG_ PDC_ObstacleDistance_RML : 39|8@0+ (1,0) [0|255] "cm"  MHU
  SG_ PDC_ObstacleDistance_RMR : 47|8@0+ (1,0) [0|255] "cm"  MHU
  SG_ PDC_ObstacleDistance_RR : 55|8@0+ (1,0) [0|255] "cm"  MHU
  SG_ PDC_ObstacleDistance_RSR : 63|8@0+ (1,0) [0|255] "cm"  MHU

BO_ 881 PDC_FrontDist: 8 PAS_Info
  SG_ CHKSM_PDC_FrontDist : 7|8@0+ (1,0) [0|255] ""  MHU
  SG_ ALV_PDC_FrontDist : 11|4@0+ (1,0) [0|15] ""  MHU
  SG_ PDC_ObstacleDistance_FSL : 23|8@0+ (1,0) [0|255] "cm"  MHU
  SG_ PDC_ObstacleDistance_FL : 31|8@0+ (1,0) [0|255] "cm"  MHU
  SG_ PDC_ObstacleDistance_FML : 39|8@0+ (1,0) [0|255] "cm"  MHU
  SG_ PDC_ObstacleDistance_FMR : 47|8@0+ (1,0) [0|255] "cm"  MHU
  SG_ PDC_ObstacleDistance_FR : 55|8@0+ (1,0) [0|255] "cm"  MHU
  SG_ PDC_ObstacleDistance_FSR : 63|8@0+ (1,0) [0|255] "cm"  MHU

BO_ 905 VCU_Sts3: 8 XGW_Info
  SG_ VCU_IMMO_Sts : 35|2@0+ (1,0) [0|3] "" MHU
  SG_ SECCAN_VCU_IMMO_Sts : 63|8@0+ (1,0) [0|255] "" Vector__XXX

BO_ 915 MHU_HudPositionSetting: 3 MHU
  SG_ MHU_SET_HudRotateLvl : 7|4@0+ (1,0) [0|15] "-" HUD
  SG_ MHU_SET_HudHeightLvl : 15|5@0+ (1,0) [0|31] "-" HUD

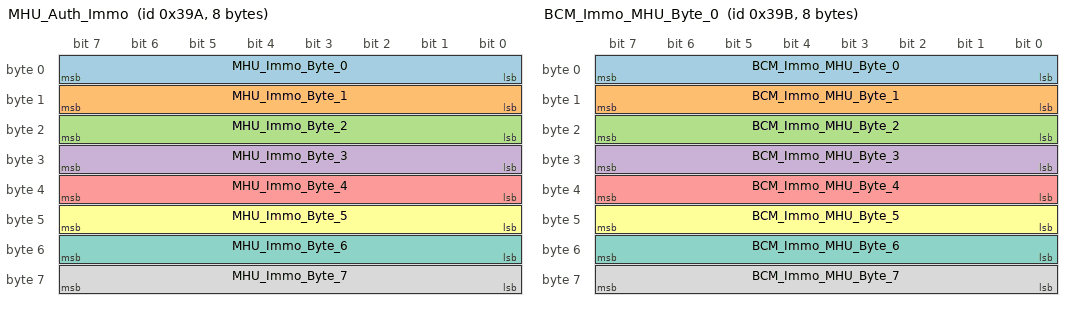
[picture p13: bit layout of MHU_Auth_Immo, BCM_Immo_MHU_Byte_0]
BO_ 922 MHU_Auth_Immo: 8 MHU
  SG_ MHU_Immo_Byte_0 : 7|8@0+ (1,0) [0|255] "-" XGW_Info
  SG_ MHU_Immo_Byte_1 : 15|8@0+ (1,0) [0|255] "-" XGW_Info
  SG_ MHU_Immo_Byte_2 : 23|8@0+ (1,0) [0|255] "" XGW_Info
  SG_ MHU_Immo_Byte_3 : 31|8@0+ (1,0) [0|255] "" XGW_Info
  SG_ MHU_Immo_Byte_4 : 39|8@0+ (1,0) [0|255] "" XGW_Info
  SG_ MHU_Immo_Byte_5 : 47|8@0+ (1,0) [0|255] "" XGW_Info
  SG_ MHU_Immo_Byte_6 : 55|8@0+ (1,0) [0|255] "" XGW_Info
  SG_ MHU_Immo_Byte_7 : 63|8@0+ (1,0) [0|255] "-" XGW_Info

BO_ 923 BCM_Immo_MHU_Byte_0: 8 XGW_Info
  SG_ BCM_Immo_MHU_Byte_0 : 7|8@0+ (1,0) [0|255] "-" MHU
  SG_ BCM_Immo_MHU_Byte_1 : 15|8@0+ (1,0) [0|255] "-" MHU
  SG_ BCM_Immo_MHU_Byte_2 : 23|8@0+ (1,0) [0|255] "-" MHU
  SG_ BCM_Immo_MHU_Byte_3 : 31|8@0+ (1,0) [0|255] "-" MHU
  SG_ BCM_Immo_MHU_Byte_4 : 39|8@0+ (1,0) [0|255] "-" MHU
  SG_ BCM_Immo_MHU_Byte_5 : 47|8@0+ (1,0) [0|255] "" MHU
  SG_ BCM_Immo_MHU_Byte_6 : 55|8@0+ (1,0) [0|255] "-" MHU
  SG_ BCM_Immo_MHU_Byte_7 : 63|8@0+ (1,0) [0|255] "-" MHU

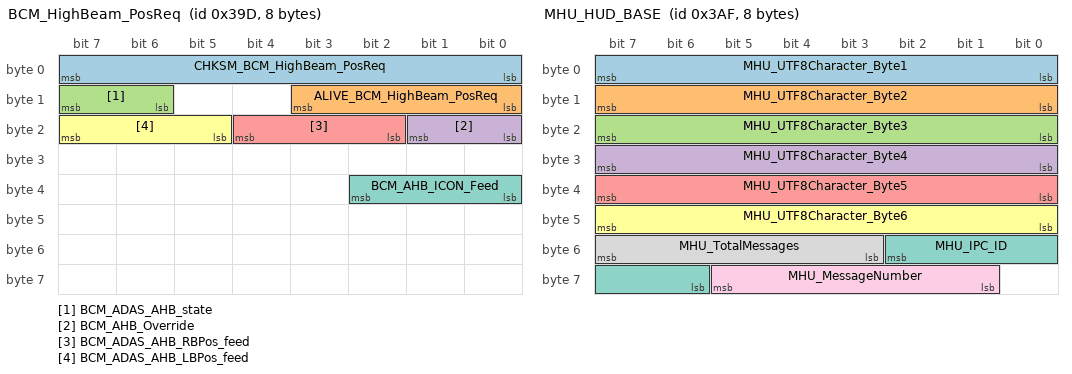
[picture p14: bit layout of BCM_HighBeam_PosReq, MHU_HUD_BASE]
BO_ 925 BCM_HighBeam_PosReq: 8 XGW_Info
 SG_ CHKSM_BCM_HighBeam_PosReq : 7|8@0+ (1,0) [0|255] ""  FCAM_Info,HUD,MHU
 SG_ ALIVE_BCM_HighBeam_PosReq : 11|4@0+ (1,0) [0|14] ""  FCAM_Info,HUD,MHU
 SG_ BCM_ADAS_AHB_state : 15|2@0+ (1,0) [0|3] ""  MHU
 SG_ BCM_AHB_Override : 17|2@0+ (1,0) [0|3] ""  MHU
 SG_ BCM_ADAS_AHB_RBPos_feed : 20|3@0+ (1,0) [0|7] ""  FCAM_Info
 SG_ BCM_ADAS_AHB_LBPos_feed : 23|3@0+ (1,0) [0|7] ""  FCAM_Info
 SG_ BCM_AHB_ICON_Feed : 34|3@0+ (1,0) [0|7] ""  HUD,MHU

BO_ 943 MHU_HUD_BASE: 8 MHU
  SG_ MHU_UTF8Character_Byte1 : 7|8@0+ (1,0) [0|255] "-" HUD
  SG_ MHU_UTF8Character_Byte2 : 15|8@0+ (1,0) [0|255] "-" HUD
  SG_ MHU_UTF8Character_Byte3 : 23|8@0+ (1,0) [0|255] "-" HUD
  SG_ MHU_UTF8Character_Byte4 : 31|8@0+ (1,0) [0|255] "-" HUD
  SG_ MHU_UTF8Character_Byte5 : 39|8@0+ (1,0) [0|255] "-" HUD
  SG_ MHU_UTF8Character_Byte6 : 47|8@0+ (1,0) [0|255] "-" HUD
  SG_ MHU_IPC_ID : 50|5@0+ (1,0) [0|15] "Bit" HUD
  SG_ MHU_TotalMessages : 55|5@0+ (1,0) [0|31] "-" HUD
  SG_ MHU_MessageNumber : 61|5@0+ (1,0) [0|31] "-" HUD

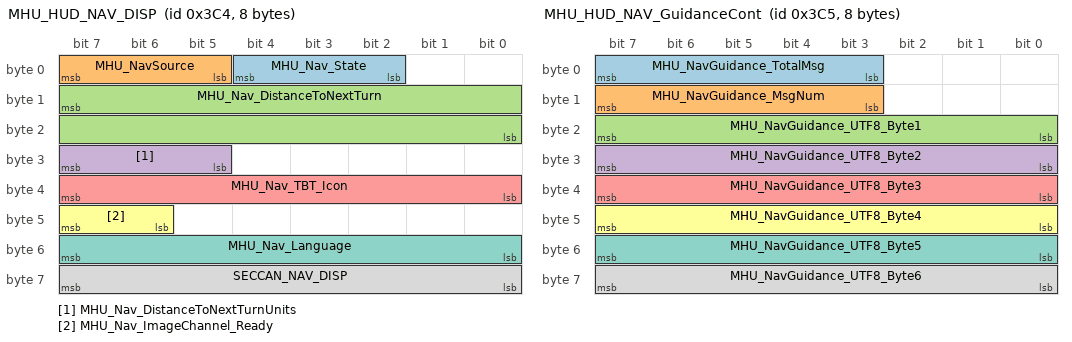
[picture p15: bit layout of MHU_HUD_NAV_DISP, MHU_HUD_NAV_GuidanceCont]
BO_ 964 MHU_HUD_NAV_DISP: 8 MHU
  SG_ MHU_Nav_State : 4|3@0+ (1,0) [0|7] "-" HUD
  SG_ MHU_NavSource : 7|3@0+ (1,0) [0|7] "-" HUD
  SG_ MHU_Nav_DistanceToNextTurn : 15|16@0+ (1,0) [0|65535] "-" HUD
  SG_ MHU_Nav_DistanceToNextTurnUnits : 31|3@0+ (1,0) [0|7] "-" HUD
  SG_ MHU_Nav_TBT_Icon : 39|8@0+ (1,0) [0|255] "-" HUD
  SG_ MHU_Nav_ImageChannel_Ready : 47|2@0+ (1,0) [0|3] "-" HUD
  SG_ MHU_Nav_Language : 55|8@0+ (1,0) [0|255] "" HUD
  SG_ SECCAN_NAV_DISP : 63|8@0+ (1,0) [0|255] "" HUD

BO_ 965 MHU_HUD_NAV_GuidanceCont: 8 MHU
  SG_ MHU_NavGuidance_TotalMsg : 7|5@0+ (1,0) [0|31] "-" HUD
  SG_ MHU_NavGuidance_MsgNum : 15|5@0+ (1,0) [0|31] "-" HUD
  SG_ MHU_NavGuidance_UTF8_Byte1 : 23|8@0+ (1,0) [0|255] "" HUD
  SG_ MHU_NavGuidance_UTF8_Byte2 : 31|8@0+ (1,0) [0|255] "" HUD
  SG_ MHU_NavGuidance_UTF8_Byte3 : 39|8@0+ (1,0) [0|255] "" HUD
  SG_ MHU_NavGuidance_UTF8_Byte4 : 47|8@0+ (1,0) [0|255] "" HUD
  SG_ MHU_NavGuidance_UTF8_Byte5 : 55|8@0+ (1,0) [0|255] "" HUD
  SG_ MHU_NavGuidance_UTF8_Byte6 : 63|8@0+ (1,0) [0|255] "" HUD

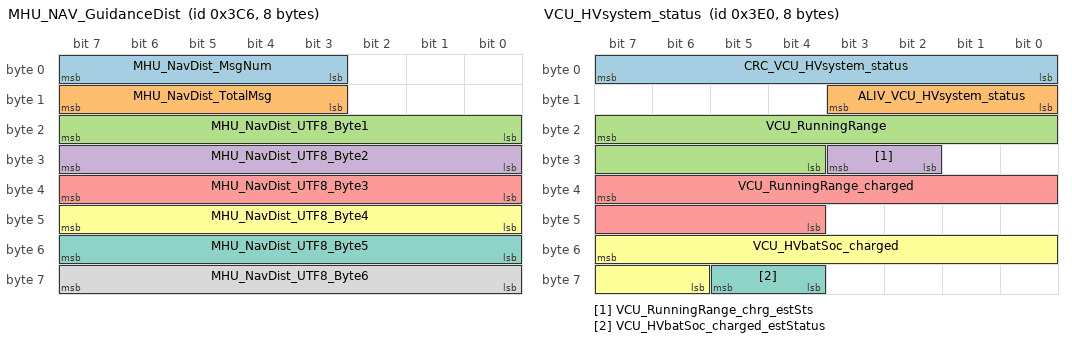
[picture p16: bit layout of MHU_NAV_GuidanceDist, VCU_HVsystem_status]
BO_ 966 MHU_NAV_GuidanceDist: 8 MHU
  SG_ MHU_NavDist_MsgNum : 7|5@0+ (1,0) [0|31] "" HUD
  SG_ MHU_NavDist_TotalMsg : 15|5@0+ (1,0) [0|31] "" HUD
  SG_ MHU_NavDist_UTF8_Byte1 : 23|8@0+ (1,0) [0|255] "" HUD
  SG_ MHU_NavDist_UTF8_Byte2 : 31|8@0+ (1,0) [0|255] "" HUD
  SG_ MHU_NavDist_UTF8_Byte3 : 39|8@0+ (1,0) [0|255] "" HUD
  SG_ MHU_NavDist_UTF8_Byte4 : 47|8@0+ (1,0) [0|255] "" HUD
  SG_ MHU_NavDist_UTF8_Byte5 : 55|8@0+ (1,0) [0|255] "" HUD
  SG_ MHU_NavDist_UTF8_Byte6 : 63|8@0+ (1,0) [0|255] "" HUD

BO_ 992 VCU_HVsystem_status: 8 XGW_Info
  SG_ CRC_VCU_HVsystem_status : 7|8@0+ (1,0) [0|255] "" HUD,MHU
  SG_ ALIV_VCU_HVsystem_status : 11|4@0+ (1,0) [0|14] "" HUD,MHU
  SG_ VCU_RunningRange : 23|12@0+ (0.5,0) [0|2047] "km" HUD,MHU
  SG_ VCU_RunningRange_chrg_estSts : 27|2@0+ (1,0) [0|3] "-" HUD,MHU
  SG_ VCU_RunningRange_charged : 39|12@0+ (0.5,0) [0|2047] "km" HUD,MHU
  SG_ VCU_HVbatSoc_charged : 55|10@0+ (0.1,0) [0|100] "%" HUD,MHU
  SG_ VCU_HVbatSoc_charged_estStatus : 61|2@0+ (1,0) [0|3] "-" HUD,MHU

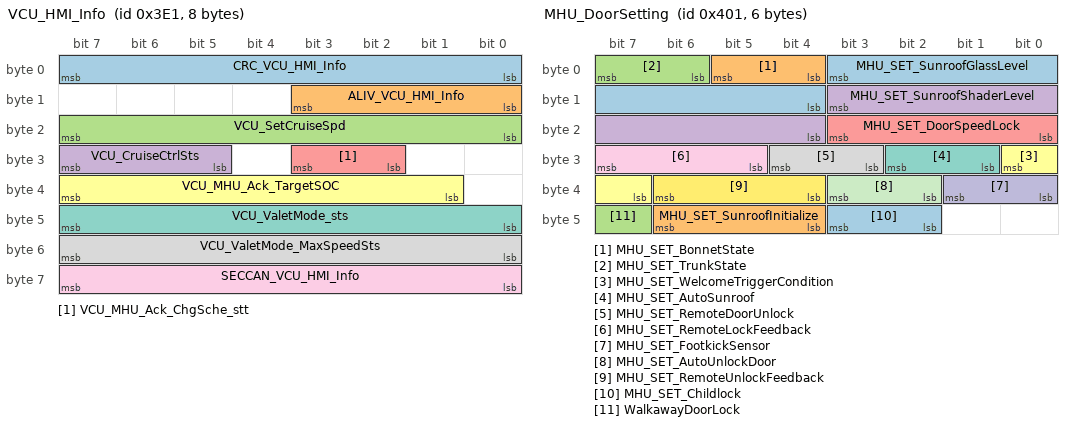
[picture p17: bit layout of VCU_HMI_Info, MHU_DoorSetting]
BO_ 993 VCU_HMI_Info: 8 XGW_Info
  SG_ CRC_VCU_HMI_Info : 7|8@0+ (1,0) [0|255] "" MHU,HUD
  SG_ ALIV_VCU_HMI_Info : 11|4@0+ (1,0) [0|14] "" MHU,HUD
  SG_ VCU_SetCruiseSpd : 23|8@0+ (1,0) [0|200] "km/h" MHU,HUD
  SG_ VCU_CruiseCtrlSts : 31|3@0+ (1,0) [0|7] ""  MHU,HUD
  SG_ VCU_MHU_Ack_ChgSche_stt : 27|2@0+ (1,0) [0|3] "" MHU
  SG_ VCU_MHU_Ack_TargetSOC : 39|7@0+ (1,0) [10|100] "%" MHU
  SG_ VCU_ValetMode_sts : 47|8@0+ (1,0) [0|255] "" MHU
  SG_ VCU_ValetMode_MaxSpeedSts : 55|8@0+ (1,0) [0|255] "km/h" MHU
  SG_ SECCAN_VCU_HMI_Info : 63|8@0+ (1,0) [0|255] "" MHU

BO_ 1015 MFS_Control_Button: 8 XGW_Info
  SG_ CHSKM_MFS_Control_Button : 7|8@0+ (1,0) [0|255] "" Vector__XXX,HUD,MHU,FCAM_Info
  SG_ ALV_MFS_Control_Button : 11|4@0+ (1,0) [0|14] "" Vector__XXX,HUD,MHU,FCAM_Info
  SG_ MFS_VoiceRecognitionOn_Off : 15|3@0+ (1,0) [0|4] "Bit" HUD,MHU
  SG_ MFS_ISAControl : 17|2@0+ (1,0) [0|3] "Bit" Vector__XXX,HUD,MHU,FCAM_Info
  SG_ MFS_CruiseSpeedIncrease : 20|3@0+ (1,0) [0|4] "Bit" Vector__XXX,HUD,MHU,FCAM_Info
  SG_ MFS_TelephoneCall_EndCall : 23|3@0+ (1,0) [0|4] "Bit" HUD,MHU
  SG_ MFS_LKAControl : 25|2@0+ (1,0) [0|3] "Bit" Vector__XXX,HUD,MHU,FCAM_Info
  SG_ MFS_CruiseGapIncrease : 28|3@0+ (1,0) [0|4] "Bit" Vector__XXX,HUD,MHU,FCAM_Info
  SG_ MFS_CruiseOn_Off : 31|3@0+ (1,0) [0|4] "Bit" Vector__XXX,HUD,MHU,FCAM_Info
  SG_ MFS_CruiseGapDecrease : 34|3@0+ (1,0) [0|4] "Bit" Vector__XXX,HUD,MHU,FCAM_Info
  SG_ MFS_CAN_RESControl : 36|2@0+ (1,0) [0|3] "-" Vector__XXX,HUD,FCAM_Info
  SG_ MFS_CruiseSpeedDecrease : 39|3@0+ (1,0) [0|4] "Bit" Vector__XXX,HUD,MHU,FCAM_Info
  SG_ MFS_M2Control : 41|2@0+ (1,0) [0|3] "Bit" Vector__XXX,HUD,FCAM_Info
  SG_ MFS_SourseControl : 44|3@0+ (1,0) [0|4] "Bit" HUD,MHU
  SG_ MFS_UpControl : 47|3@0+ (1,0) [0|4] "Bit" EASC,HUD,MHU
  SG_ MFS_DownControl : 52|3@0+ (1,0) [0|4] "Bit" EASC,HUD,MHU
  SG_ MFS_LeftControl : 55|3@0+ (1,0) [0|4] "Bit" EASC,HUD,MHU
  SG_ MFS_Failure : 57|1@0+ (1,0) [0|1] "Bit" Vector__XXX,HUD,MHU,FCAM_Info
  SG_ MFS_RightControl : 60|3@0+ (1,0) [0|4] "Bit" EASC,HUD,MHU
  SG_ MFS_OK_Control : 63|3@0+ (1,0) [0|4] "Bit" HUD,MHU

BO_ 1020 XGW_FOTA_StsConfirm: 4 XGW_Info
  SG_ CRC_XGW_FOTA_StsConfirm : 7|8@0+ (1,0) [0|255] "" MHU
  SG_ ALIV_XGW_FOTA_StsConfirm : 11|4@0+ (1,0) [0|14] "" MHU
  SG_ XGW_FOTA_StateConfirm : 15|4@0+ (1,0) [0|14] "-" MHU
  SG_ XGW_FOTA_Error_Code : 23|8@0+ (1,0) [0|255] "-" MHU

BO_ 1025 MHU_DoorSetting: 6 MHU
  SG_ MHU_SET_SunroofGlassLevel : 3|8@0+ (1,0) [0|255] "%" XGW_Info
  SG_ MHU_SET_BonnetState : 5|2@0+ (1,0) [0|3] "-" XGW_Info
  SG_ MHU_SET_TrunkState : 7|2@0+ (1,0) [0|3] "-" XGW_Info
  SG_ MHU_SET_SunroofShaderLevel : 11|8@0+ (1,0) [0|255] "%" XGW_Info
  SG_ MHU_SET_DoorSpeedLock : 19|4@0+ (1,0) [0|7] "" XGW_Info
  SG_ MHU_SET_WelcomeTriggerCondition : 24|2@0+ (1,0) [0|3] "" XGW_Info
  SG_ MHU_SET_AutoSunroof : 26|2@0+ (1,0) [0|3] "" XGW_Info
  SG_ MHU_SET_RemoteDoorUnlock : 28|2@0+ (1,0) [0|3] "-" XGW_Info
  SG_ MHU_SET_RemoteLockFeedback : 31|3@0+ (1,0) [0|7] "-" XGW_Info
  SG_ MHU_SET_FootkickSensor : 33|2@0+ (1,0) [0|3] "-" XGW_Info
  SG_ MHU_SET_AutoUnlockDoor : 35|2@0+ (1,0) [0|3] "" XGW_Info
  SG_ MHU_SET_RemoteUnlockFeedback : 38|3@0+ (1,0) [0|7] "" XGW_Info
  SG_ MHU_SET_Childlock : 43|2@0+ (1,0) [0|3] "" XGW_Info
  SG_ MHU_SET_SunroofInitialize : 46|3@0+ (1,0) [0|7] "" XGW_Info
  SG_ WalkawayDoorLock : 47|1@0+ (1,0) [0|1] "" XGW_Info

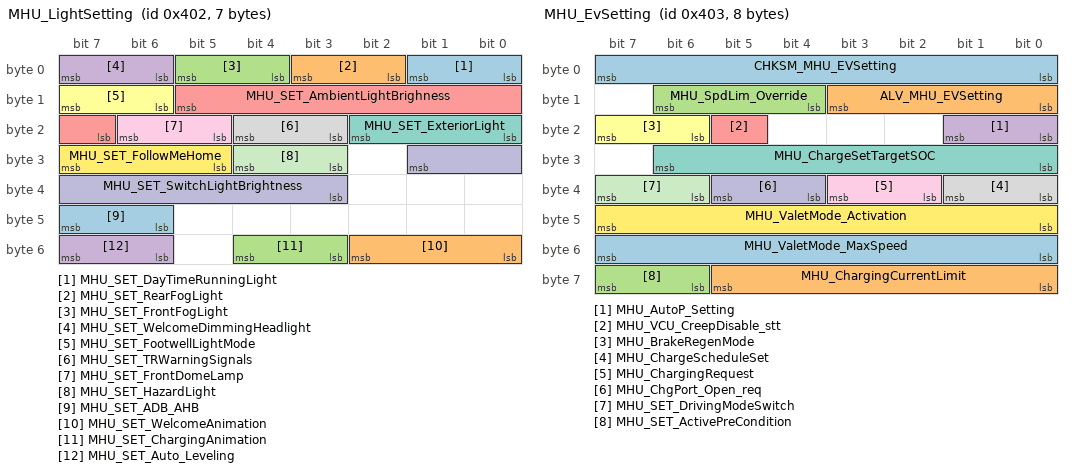
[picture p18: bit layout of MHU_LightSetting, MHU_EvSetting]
BO_ 1026 MHU_LightSetting: 7 MHU
  SG_ MHU_SET_DayTimeRunningLight : 1|2@0+ (1,0) [0|3] "-" XGW_Info
  SG_ MHU_SET_RearFogLight : 3|2@0+ (1,0) [0|3] "" XGW_Info
  SG_ MHU_SET_FrontFogLight : 5|2@0+ (1,0) [0|3] "" XGW_Info
  SG_ MHU_SET_WelcomeDimmingHeadlight : 7|2@0+ (1,0) [0|3] "" XGW_Info
  SG_ MHU_SET_AmbientLightBrighness : 13|7@0+ (1,0) [0|100] "%" XGW_Info
  SG_ MHU_SET_FootwellLightMode : 15|2@0+ (1,0) [0|3] "-" XGW_Info
  SG_ MHU_SET_ExteriorLight : 18|3@0+ (1,0) [0|7] "" XGW_Info
  SG_ MHU_SET_TRWarningSignals : 20|2@0+ (1,0) [0|3] "" XGW_Info
  SG_ MHU_SET_FrontDomeLamp : 22|2@0+ (1,0) [0|3] "" XGW_Info
  SG_ MHU_SET_SwitchLightBrightness : 25|7@0+ (1,0) [0|100] "%" XGW_Info
  SG_ MHU_SET_HazardLight : 28|2@0+ (1,0) [0|3] ""  XGW_Info
  SG_ MHU_SET_FollowMeHome : 31|3@0+ (1,0) [0|7] "" XGW_Info
  SG_ MHU_SET_ADB_AHB : 47|2@0+ (1,0) [0|3] "" XGW_Info
  SG_ MHU_SET_WelcomeAnimation : 50|3@0+ (1,0) [0|5] "" XGW_Info
  SG_ MHU_SET_ChargingAnimation : 52|2@0+ (1,0) [0|3] "" XGW_Info
  SG_ MHU_SET_Auto_Leveling : 55|2@0+ (1,0) [0|3] "-" XGW_Info

BO_ 1027 MHU_EvSetting: 8 MHU
  SG_ CHKSM_MHU_EVSetting : 7|8@0+ (1,0) [0|255] "" FCAM_Info,XGW_Info
  SG_ ALV_MHU_EVSetting : 11|4@0+ (1,0) [0|14] "" FCAM_Info,XGW_Info
  SG_ MHU_SpdLim_Override : 14|3@0+ (10,0) [0|30] "km/h"  XGW_Info
  SG_ MHU_AutoP_Setting : 17|2@0+ (1,0) [0|3] ""  XGW_Info
  SG_ MHU_VCU_CreepDisable_stt : 21|1@0+ (1,0) [0|1] "" XGW_Info
  SG_ MHU_BrakeRegenMode : 23|2@0+ (1,0) [0|3] "" XGW_Info
  SG_ MHU_ChargeSetTargetSOC : 30|7@0+ (1,0) [10|100] "%" XGW_Info
  SG_ MHU_ChargeScheduleSet : 33|2@0+ (1,0) [0|3] "" XGW_Info
  SG_ MHU_ChargingRequest : 35|2@0+ (1,0) [0|3] "-" XGW_Info
  SG_ MHU_ChgPort_Open_req : 37|2@0+ (1,0) [0|3] "-" XGW_Info
  SG_ MHU_SET_DrivingModeSwitch : 39|2@0+ (1,0) [0|3] "-" XGW_Info
  SG_ MHU_ValetMode_Activation : 47|8@0+ (1,0) [0|255] "" XGW_Info,FCAM_Info,PAS_Info
  SG_ MHU_ValetMode_MaxSpeed : 55|8@0+ (1,0) [0|255] "km/h" XGW_Info
  SG_ MHU_ChargingCurrentLimit : 61|6@0+ (1,0) [0|62] "A" XGW_Info
  SG_ MHU_SET_ActivePreCondition : 63|2@0+ (1,0) [0|3] "" XGW_Info

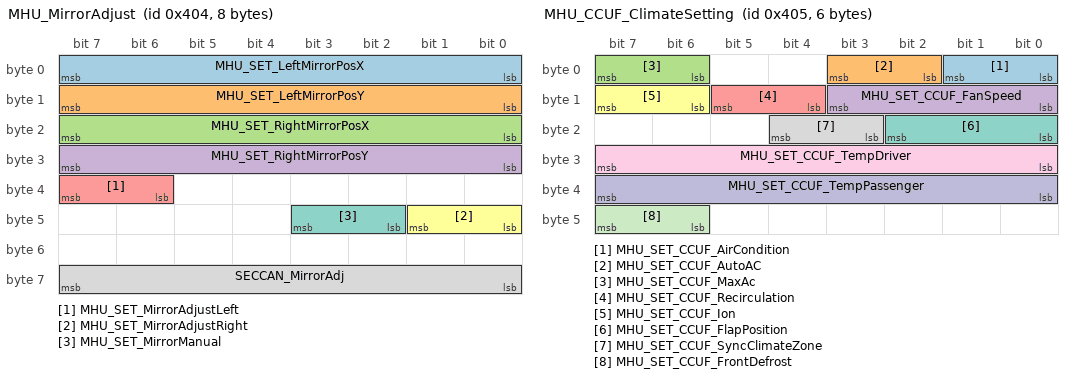
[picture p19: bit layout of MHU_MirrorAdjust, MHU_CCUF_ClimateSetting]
BO_ 1028 MHU_MirrorAdjust: 8 MHU
  SG_ MHU_SET_LeftMirrorPosX : 7|8@0+ (1,-15) [-15|15] "deg" XGW_Info
  SG_ MHU_SET_LeftMirrorPosY : 15|8@0+ (1,-15) [-15|15] "deg" XGW_Info
  SG_ MHU_SET_RightMirrorPosX : 23|8@0+ (1,-15) [-15|15] "deg" XGW_Info
  SG_ MHU_SET_RightMirrorPosY : 31|8@0+ (1,-15) [-15|15] "deg" XGW_Info
  SG_ MHU_SET_MirrorAdjustLeft : 39|2@0+ (1,0) [0|3] "-" XGW_Info
  SG_ MHU_SET_MirrorAdjustRight : 41|2@0+ (1,0) [0|3] "-" XGW_Info
  SG_ MHU_SET_MirrorManual : 43|2@0+ (1,0) [0|3] "" XGW_Info
  SG_ SECCAN_MirrorAdj : 63|8@0+ (1,0) [0|255] "" XGW_Info

BO_ 1029 MHU_CCUF_ClimateSetting: 6 MHU
  SG_ MHU_SET_CCUF_AirCondition : 1|2@0+ (1,0) [0|3] "" XGW_Info
  SG_ MHU_SET_CCUF_AutoAC : 3|2@0+ (1,0) [0|3] "" XGW_Info
  SG_ MHU_SET_CCUF_MaxAc : 7|2@0+ (1,0) [0|3] "" XGW_Info
  SG_ MHU_SET_CCUF_FanSpeed : 11|4@0+ (1,0) [0|7] "-" XGW_Info
  SG_ MHU_SET_CCUF_Recirculation : 13|2@0+ (1,0) [0|3] "" XGW_Info
  SG_ MHU_SET_CCUF_Ion : 15|2@0+ (1,0) [0|3] "-" XGW_Info
  SG_ MHU_SET_CCUF_FlapPosition : 18|3@0+ (1,0) [0|7] "-" XGW_Info
  SG_ MHU_SET_CCUF_SyncClimateZone : 20|2@0+ (1,0) [0|3] "-" XGW_Info
  SG_ MHU_SET_CCUF_TempDriver : 31|8@0+ (0.5,0) [16|32] "Degree C" XGW_Info
  SG_ MHU_SET_CCUF_TempPassenger : 39|8@0+ (0.5,0) [16|32] "Degree C" XGW_Info
  SG_ MHU_SET_CCUF_FrontDefrost : 47|2@0+ (1,0) [0|3] "" XGW_Info

CM_ BO_ 676 "SVC_EHC_1";
CM_ BO_ 714 "Tester control BMS";
CM_ BO_ 715 "IC_TEMP";
CM_ SG_ 720 FCAM_AESA_Status "The signal will be used to indicate the MRM status";
CM_ BO_ 753 "IC STAT AIRBAG";
CM_ BO_ 760 "MHU Date Time";
CM_ BO_ 761 "MHU Date time UTC.";
CM_ BO_ 768 "CCU Status";
CM_ BO_ 769 "ADAS_RP_Status";
CM_ BO_ 770 "CCU temprature and pressure";
CM_ BO_ 773 "BMS Insulation";
CM_ BO_ 775 "CPD Output";
CM_ BO_ 776 "MHU CPD Confirmation";
CM_ BO_ 784 "CCU_R_Status";
CM_ BO_ 787 "POD StatusCharger1";
CM_ BO_ 803 "POD StatusCharger2";
CM_ BO_ 804 "HOD Heating Control";
CM_ BO_ 805 "Heating Control- Feedback";
CM_ BO_ 806 "POD StatusDCDC1";
CM_ BO_ 807 "POD Fast Charge status";
CM_ BO_ 808 "IC RELATIVIME";
CM_ BO_ 809 "BCM_ODO";
CM_ BO_ 816 "IC_MILEAGE";
CM_ BO_ 818  "BMS Pack information ";
CM_ SG_ 818 Checksum_0x332 "Checksum";
CM_ SG_ 818 Rolling_Counter_0x332 "Rolling Counter";
CM_ SG_ 818 BMS_PackCNom "Nominal capacity of the battery pack";
CM_ SG_ 818 BMS_PackTemp_0x332 "Pack Temperature ";
CM_ BO_ 819  "SRR Calibration Status";
CM_ BO_ 827 "Camera Left/right lane type signals";
CM_ BO_ 833 "Camera Object 1 signals";
CM_ BO_ 835 "Camera Object 2 signals";
CM_ BO_ 838 "POD Status2";
CM_ BO_ 840 "MCU Front status";
CM_ BO_ 841 "MCU Rear status";
CM_ BO_ 842 "Camera Object 3 signals";
CM_ BO_ 844 "Camera Object 4 signals";
CM_ BO_ 845 "Camera Object 5 signals";
CM_ BO_ 846 "Camera Object 6 signals";
CM_ BO_ 849 "ADAS Parking Assist";
CM_ BO_ 850 "ADAS Auto headlight high beam control and Door Open Warning";
CM_ BO_ 851 "ADAS Adaptive Cruise Control";
CM_ BO_ 852 "MHU ADAS request";
CM_ BO_ 853 "ADAS component check";
CM_ BO_ 885 "BMS Relay";
CM_ BO_ 883 "PDCU Parking Assist Status";
CM_ BO_ 884 "PDCU Parking Assist Distance";
CM_ BO_ 896 "BCM vehicle identifier number";
CM_ BO_ 897 "ACM seatbelt and buckle status for seatbelt reminder";
CM_ BO_ 905 "VCU_status";
CM_ BO_ 915 "MHU_HudPositionSetting";
CM_ BO_ 922 "MHU_Authentication information";
CM_ BO_ 923 "GW_BCM_Immo_MHU_Byte";
CM_ BO_ 925 "BCM hight beam position request";
CM_ BO_ 943 "MHU_HUD_BASE";
CM_ BO_ 964 "MHU HUD NAV DISP";
CM_ BO_ 965 "MHU_HUD_NAV_GuidanceCont";
CM_ BO_ 966 "MHU NAV GuidanceDist";
CM_ BO_ 992 "VCU High Voltage System Status";
CM_ BO_ 993 "VCU_HMI_Info.";
CM_ BO_ 1015 "MFS Control Button";
CM_ BO_ 1020 "XGW FOTA confirm status";
CM_ BO_ 1025 "MHU Door Setting";
CM_ BO_ 1026 "MHU Light Setting";
CM_ BO_ 1027 "MHU Driving Mode Setting";
CM_ BO_ 1028 "MHU Mirror Adjust";
CM_ BO_ 1029 "MHU Climate Setting";
CM_ SG_ 676 ECU_ID_WUPREG "n.a.";
CM_ SG_ 676 ID_FN_INQY "n.a.";
CM_ SG_ 676 ID_FN_RQ_BUS "n.a.";
CM_ SG_ 676 NO_CC_MESS_STD "n.a.";
CM_ SG_ 676 WACA "n.a.";
CM_ SG_ 714 CHKSM_IC_SENSOR "Checksum";
CM_ SG_ 714 ALV_IC_SENSOR "Alive Counter";
CM_ SG_ 714 MHU_STAT_AmbientTempRaw "Ambient Temperature Raw";
CM_ SG_ 714 MHU_STAT_FuelLevel "Fuel Level 3 to 63 l  (only for ICE)";
CM_ SG_ 714 MHU_STAT_AmbientTemp "Ambient Temperature filtered";
CM_ SG_ 714 MHU_STAT_CoolantLevelStatus "Low level coolant indicator";
CM_ SG_ 715 TEMP_EX "n.a.";
CM_ SG_ 715 TEMP_EX_UNFILT "Outsude temp raw";
CM_ SG_ 717 MHU_ADASISv2_Container "ADASIS v2 container from (eHorizon inside MHU) to Reconstructor (FCAM) ADAS system";
CM_ SG_ 720 CHKSM_FCAM_AESA_Sts "Checksum";
CM_ SG_ 720 ALV_FCAM_AESA_Sts "Alive Counter";
CM_ SG_ 720 FCAM_AESA_DoorUnlock_Req "The signal will be used to unlock the doors once the AESA control is done and the vehicle is brough to stop";
CM_ SG_ 720 FCAM_AESA_ECALL_Req "The signal will be used to triggered the ECALL functionality once the AESA control is done and the vehicle is brough to stop";
CM_ SG_ 720 FCAM_AESA_Status "The signal will be used to indicate the MRM status";
CM_ SG_ 753 MHU_STAT_AirbagWarnLamp "Status of Airbag telltale warning";
CM_ SG_ 760 DISP_HR "The signal / parameter indicates the current hour.";
CM_ SG_ 760 DISP_MN "The signal / parameter indicates the current minute.";
CM_ SG_ 760 DISP_SEC "The signal / parameter indicates the current second.";
CM_ SG_ 760 DISP_DATE_DAY "The signal / parameter indicates the current day.";
CM_ SG_ 760 DISP_DATE_MON "The signal / parameter indicates the current month.";
CM_ SG_ 760 DISP_DATE_WDAY "The signal   parameter indicates the current day of the week.";
CM_ SG_ 760 DISP_DATE_YR "The signal / parameter indicates the current year.";
CM_ SG_ 760 ST_DISP_CTI_DATE "The signal / parameter indicates the state of the switch summer winter time.";
CM_ SG_ 761 DISP_HR_UTC "The signal/parameter indcates the current hour";
CM_ SG_ 761 DISP_MN_UTC "The signal/parameter indicates the current minute";
CM_ SG_ 761 DISP_SEC_UTC "The signal / parameter indicates the current second.";
CM_ SG_ 761 DISP_DATE_DAY_UTC "The signal / parameter indicates the current day.";
CM_ SG_ 761 DISP_DATE_MON_UTC "The signal/parameter indicates the current month";
CM_ SG_ 761 DISP_DATE_YR_UTC "The signal / parameter indicates the current year.";
CM_ SG_ 768 CCU_STAT_SyncClimateZone "Status dual clima automatic";
CM_ SG_ 768 CCU_STAT_Auto "Status activation of auto mode";
CM_ SG_ 768 CCU_STAT_Aircondition "Aircondition status";
CM_ SG_ 768 CCU_STAT_IonButton "Status if the ionisator is active";
CM_ SG_ 768 CCU_STAT_MaxAc "Status activation of MAX AC mode";
CM_ SG_ 768 CCU_STAT_OnOff "Status On  Off button for clima";
CM_ SG_ 768 CCU_STAT_FanSpeed "Blower settings/Fan Speed for climate system";
CM_ SG_ 768 CCU_STAT_RecircFlap "Recirculation flap status, 100% fresh air, 0% recirculation mode";
CM_ SG_ 768 CCU_STAT_FlapPos "Request for flap position";
CM_ SG_ 768 CCU_STAT_Defrost "Status activation of Defrost mode";
CM_ SG_ 768 CCU_STAT_PTC_Heater "CCU status for PTC heater";
CM_ SG_ 768 CCU_STAT_TempDriver "CCU status for temperature regulationr driver (Display Temperature)";
CM_ SG_ 768 CCU_STAT_TempPassenger "CCU status for temperature regulation  passenger(Display Temperature)";
CM_ SG_ 769 Checksum_RP "Checksum";
CM_ SG_ 769 Rolling_Counter_RP "Roling counter";
CM_ SG_ 769 RP_ReqInfoDispTxt2 "self check remind user";
CM_ SG_ 769 RP_Status "RP_Status";
CM_ SG_ 769 ADAS_TboxAuthStatus "MHU TBOX authentication statusUsing this as handshak";
CM_ SG_ 769 RP_ReqInfoDispTxt1 "ADAS RP Req Info Txt1";
CM_ SG_ 770 CHKSM_CCU_TEMP_PRESSURE "Checksum";
CM_ SG_ 770 ALV_CCU_TEMP_PRESSURE "Alive Counter";
CM_ SG_ 770 CCU_Pressure_AC "The compressor line pressure.";
CM_ SG_ 770 CCU_InteriorTemp "CCU interiour  temperature. Invalid = 251-255";
CM_ SG_ 770 CCU_TempEx_AC "Outside temperature calculated by CCU";
CM_ SG_ 770 CCU_EvaporatorTemp "Actual evaporator temperature of the HVAC unit. Invalid = 251-255";
CM_ SG_ 773 CHSKM_BMS_Insulation "Checksum";
CM_ SG_ 773 ALV_BMS_Insulation "Rolling Counter";
CM_ SG_ 773 BMS_VCU_Insulation_Mon_Sts "Feedback for the Insulation Monitoring signal ";
CM_ SG_ 773 BMS_PackInsuRes "Minimum value of BCU_PosInsuRes and BCU_NegInsuRes";
CM_ SG_ 775 CHKSM_CPD_Output_1 "This signal is used for E2E protection. ";
CM_ SG_ 775 ALV_CPD_Output_1 "Alive counter required by AUTOSAR E2E protection.";
CM_ SG_ 775 OUT_Alert_TO_BCM "This signal is used to trigger warning on BCM";
CM_ SG_ 775 CPD_State_information "This signal is used to send state of CPD (enable/disable) to MHU";
CM_ SG_ 775 OUT_Alert_TO_MHU "This signal is used to trigger warning on MHU";
CM_ SG_ 776 MHU_CPD_Setting "Setting for CPD";
CM_ SG_ 776 MHU_CPD_Confirmation_On_HMI "Input signal for user confirmation or timeout from HMI.";
CM_ SG_ 784 CCUR_STAT_IonButton "Status if the ionisator is active";
CM_ SG_ 784 CCUR_STAT_Defrost "Status activation of Defrost mode";
CM_ SG_ 784 CCUR_STAT_Auto "Status activation of auto mode";
CM_ SG_ 784 CCUR_STAT_Aircondition "Aircondition status";
CM_ SG_ 784 CCUR_STAT_FlapPos "Request for flap position";
CM_ SG_ 784 CCUR_STAT_FanSpeed "Blower settings Fan Speed for climate system";
CM_ SG_ 784 CCUR_STAT_PTC_Heater "CCU status for PTC heater";
CM_ SG_ 784 CCUR_STAT_OnOff "Status On  Off button for clima";
CM_ SG_ 784 CCUR_STAT_MaxAc "Status activation of MAX AC mode";
CM_ SG_ 784 CCUR_STAT_SyncClimateZone "Status dual clima automatic";
CM_ SG_ 784 CCUR_STAT_RecircFlap "Recirculation flap status, 100% fresh air, 0% recirculation mode";
CM_ SG_ 784 CCUR_STAT_TempRear "
CCU status for temperature regulationr driver (Display Temperature)";
CM_ SG_ 771 Checksum_MHU_PAS_FEEDBACK "Checksum.";
CM_ SG_ 771 Rolling_Counter_MHU_PAS_FEEDBACK "Rolling counter";
CM_ SG_ 771 MHU_AVM_CurbViewReq "Auto Display SVM when turn left or right with limit speed 15kph setting request ";
CM_ SG_ 771 HU_SVS_TransparentModel_Req "Transparent mode button status";
CM_ SG_ 771 HU_SVSObjOverlay "Object Warning overlya request";
CM_ SG_ 771 MHU_AVM_DynamiclineReq "Guideline status setting";
CM_ SG_ 771 HU_3D_SVS_ReqFromHU "2D_3D_switching_SVS Button status";
CM_ SG_ 771 MHU_AVM_ShowAPAReq "Request to turn on APA functionality";
CM_ SG_ 771 MHU_AVM_BmprViewReq "Bumper view request";
CM_ SG_ 771 HU_SVSManVidSetupReqFromHU "Request for view change from user via LVDS";
CM_ SG_ 771 HU_3D_SVS_ViewChgReqFromHU "3D View Change Req";
CM_ SG_ 771 SECCAN_MHU_PAS_FEEDBACK "Seed generated from Secure CAN algorithm";
CM_ SG_ 787 CHSKM_POD_StatusCharger1 "Check sum";
CM_ SG_ 787 ALV_POD_StatusCharger1 "Alive counter";
CM_ SG_ 787 POD_statusOBC "OBC status";
CM_ SG_ 787 POD_OBC_Max_Current_Out "Max DC current OBC able to output";
CM_ SG_ 787 POD_iDCOut "POD measured output current on OBC output";
CM_ SG_ 787 POD_vDCOut "POD measured bus voltage at OBC output";
CM_ SG_ 803 CHSKM_POD_StatusCharger2 "Check sum";
CM_ SG_ 803 ALV_POD_StatusCharger2 "Alive counter";
CM_ SG_ 803 POD_iACInput "POD measured current on AC input";
CM_ SG_ 803 POD_vACInput "POD measured voltage on AC input";
CM_ SG_ 804 Steering_HeatingControl "Steering Heating Control";
CM_ SG_ 805 Steering_HeatingControlFdbk "Steering Heating Control Feedback";
CM_ SG_ 806 CHSKM_POD_StatusDCDC1 "Check sum";
CM_ SG_ 806 ALV_POD_StatusDCDC1 "Alive counter";
CM_ SG_ 806 POD_statusDCDC "DCDC status";
CM_ SG_ 806 POD_DCDC_Max_Current_Out "Max LV current DCDC able to output";
CM_ SG_ 807 CHKSM_POD_StatusFC "Check sum POD_StatusFC";
CM_ SG_ 807 ALV_POD_StatusFC "Alive counter POD_StatusFC";
CM_ SG_ 807 POD_vFC "POD measured voltage on charge port side of fast charge contactors";
CM_ SG_ 807 POD_statusFCContactors "DC charge contactor";
CM_ SG_ 808 T_SEC_COU_REL "This counter counts the seconds synchronously to the system clock.";
CM_ SG_ 808 T_DAY_COU_ABSL "Relative time
";
CM_ SG_ 809 CRC_BCM_ODO "Checksum";
CM_ SG_ 809 ALIV_BCM_ODO "Alive counter";
CM_ SG_ 809 Odometer_BCM "Odometer infomation for IPC.";
CM_ SG_ 809 SECCAN_BCM_ODO "Seed generated from Secure CAN algorithm";
CM_ SG_ 816 MILE_KM "Mileage information
";
CM_ SG_ 816 FLLV_FUTA "The fuel level of  tank. 255 value invalid";
CM_ SG_ 816 RNG "Calculated range of IPC";
CM_ SG_ 816 ST_FLLV_FUTA_SPAR "State of the tank reserve indicator 

";
CM_ SG_ 819 Checksum_0x333 "Checksum";
CM_ SG_ 819 Rolling_Counter_0x333 "Rolling_Counter";
CM_ SG_ 819 ADAS_RadarRight_Cal_Status "BSD right calibration Status";
CM_ SG_ 819 ADAS_RadarLeft_Cal_Status "BSD left calibration Status";
CM_ SG_ 819 ADAS_RadarRight_DynaCal_Status "BSD right dynamic calibration status";
CM_ SG_ 819 ADAS_MasterSRR_check "Master Corner radar Check";
CM_ SG_ 819 ADAS_SlaveSRR_check "Slave Corner radar Check";
CM_ SG_ 819 ADAS_RadarLeft_DynaCal_Status "BSD left dynamic calibration status";
CM_ SG_ 819 ADAS_CalSensorMasterProgress "Master(Left) radar calibration progress when get in";
CM_ SG_ 819 ADAS_CalSensorSlaverProgress "Slaver(Right) radar calibration progress when get in";
CM_ SG_ 819 ADAS_Cal_LeftInstallDeviation "left radar install angle deviation  from auto calibration";
CM_ SG_ 819 ADAS_Cal_RightInstallDeviation "right radar install angle deviation  from auto calibration";
CM_ SG_ 827 CHKSM_CameraLane "Checksum";
CM_ SG_ 827 ALV_ADAS_Cameralane "Alive Counter";
CM_ SG_ 827 Camera_R1_Line_Type "L1 right line type";
CM_ SG_ 827 Camera_L1_Line_Type "ICON Feedback Request for LKA/ELK function";
CM_ SG_ 827 R0_ExistProbability "Host Lane right line exist probability ";
CM_ SG_ 827 L0_ExistProbability "Host Lane left line exist probability";
CM_ SG_ 827 L1_ExistProbability "far right line exist probability";
CM_ SG_ 827 R1_ExistProbability "far right line exist probability ";
CM_ SG_ 827 SECCAN_CameraLane "Secret portion from Secure CAN algorithm";
CM_ SG_ 833 SECCAN_Cam_OBJ_1 "Secret portion from Secure CAN algorithm";
CM_ SG_ 833 ADAS_OBJ01_Class "The class of object 01";
CM_ SG_ 833 ADAS_OBJ01_LgtDis "Longitudinal distance of object 01";
CM_ SG_ 833 ADAS_OBJ01_ID "The ID of object 01";
CM_ SG_ 833 ADAS_OBJ01_LatDis "Lateral distance of object 01(left minus right positive)";
CM_ SG_ 833 ADAS_OBJ01_Lane "Road information of Object 01";
CM_ SG_ 835 SECCAN_Cam_OBJ_2 "Secret portion from Secure CAN algorithm";
CM_ SG_ 835 ADAS_OBJ02_Class "The class of object 02";
CM_ SG_ 835 ADAS_OBJ02_LgtDis "Longitudinal distance of object 02";
CM_ SG_ 835 ADAS_OBJ02_ID "The ID of object 02";
CM_ SG_ 835 ADAS_OBJ02_LatDis "Lateral distance of object 02(left minus right positive)";
CM_ SG_ 835 ADAS_OBJ02_Lane "Road information of Object 02";
CM_ SG_ 838 CHSKM_POD_StatusDCDC2 "Check sum";
CM_ SG_ 838 ALV_POD_StatusDCDC2 "Alive counter";
CM_ SG_ 838 POD_vDCInput "POD measured DC bus voltage at DCDC input";
CM_ SG_ 838 POD_iDCDCOutput "POD reported 12V current";
CM_ SG_ 838 POD_vDCDCOutput "POD reported 12V voltage";
CM_ SG_ 840 EDS_HVIL_STS_FWD "FWD EDS HighVoltage state";
CM_ SG_ 841 EDS_HVIL_STS_RWD "RWD EDS HighVoltage state";
CM_ SG_ 842 SECCAN_Cam_OBJ_3 "Secret portion from Secure CAN algorithm";
CM_ SG_ 842 ADAS_OBJ03_Class "The class of object 03";
CM_ SG_ 842 ADAS_OBJ03_LgtDis "Longitudinal distance of object 03";
CM_ SG_ 842 ADAS_OBJ03_ID "The ID of object 03";
CM_ SG_ 842 ADAS_OBJ03_LatDis "Lateral distance of object 03(left minus right positive)";
CM_ SG_ 842 ADAS_OBJ03_Lane "Road information of Object 03";
CM_ SG_ 844 SECCAN_Cam_OBJ_4 "Secret portion from Secure CAN algorithm";
CM_ SG_ 844 ADAS_OBJ04_Class "The class of object 04";
CM_ SG_ 844 ADAS_OBJ04_LgtDis "Longitudinal distance of object 04";
CM_ SG_ 844 ADAS_OBJ04_ID "The ID of object 04";
CM_ SG_ 844 ADAS_OBJ04_LatDis "Lateral distance of object 04(left minus right positive)";
CM_ SG_ 844 ADAS_OBJ04_Lane "Road information of Object 04";
CM_ SG_ 845 SECCAN_Cam_OBJ_5 "Secret portion from Secure CAN algorithm";
CM_ SG_ 845 ADAS_OBJ05_Class "The class of object 05";
CM_ SG_ 845 ADAS_OBJ05_LgtDis "Longitudinal distance of object 05";
CM_ SG_ 845 ADAS_OBJ05_ID "The ID of object 05";
CM_ SG_ 845 ADAS_OBJ05_LatDis "Lateral distance of object 05(left minus right positive)";
CM_ SG_ 845 ADAS_OBJ05_Lane "Road information of Object 05";
CM_ SG_ 846 SECCAN_Cam_OBJ_6 "Secret portion from Secure CAN algorithm";
CM_ SG_ 846 ADAS_OBJ06_Class "The class of object 06";
CM_ SG_ 846 ADAS_OBJ06_LgtDis "Longitudinal distance of object 06";
CM_ SG_ 846 ADAS_OBJ06_ID "The ID of object 06";
CM_ SG_ 846 ADAS_OBJ06_LatDis "Lateral distance of object 06(left minus right positive)";
CM_ SG_ 846 ADAS_OBJ06_Lane "Road information of Object 06";
CM_ SG_ 849 CHKSM_ADAS_PA "Checksum";
CM_ SG_ 849 ALV_ADAS_PA "Alive Counter";
CM_ SG_ 849 ADAS_PA_AutoOn_Feed "Parking assist On Off Feedback";
CM_ SG_ 849 ADAS_PA_AlertFRI "Front-Right-Inner Parking Sensors Warnning Display";
CM_ SG_ 849 ADAS_PA_AlertFLI "Front-Left-Inner Parking Sensors Warnning Display";
CM_ SG_ 849 ADAS_PA_AlertFLO "Front-Left-Outer Parking Sensors Warnning Display";
CM_ SG_ 849 ADAS_PA_AlertRLO "Rear-Left-Outer Parking Sensors Warnning Display";
CM_ SG_ 849 ADAS_PA_AlertRLI "Rear-Left-Inner Parking Sensors Warnning Display";
CM_ SG_ 849 ADAS_PA_AlertFRO "Front-Right-Outer Parking Sensors Warnning Display";
CM_ SG_ 849 ADAS_PA_AlertRRO "Rear-Right-Outer Parking Sensors Warnning Display";
CM_ SG_ 849 ADAS_PA_AlertRRI "Rear-Right-Inner Parking Sensors Warnning Display";
CM_ SG_ 849 ADAS_PA_state "ADAS Parking assist State (Include. On Off Feedback signal)";
CM_ SG_ 849 ADAS_PA_AlertFLS "ADAS_PA_AlertFLS";
CM_ SG_ 849 ADAS_PA_AlertRLS "ADAS_PA_AlertRLS";
CM_ SG_ 849 ADAS_PA_AlertFRS "ADAS_PA_AlertFRS";
CM_ SG_ 849 ADAS_PA_AlertRRS "ADAS_PA_AlertRRS";
CM_ SG_ 850 CHKSM_ADAS_AHB_DOW "Checksum";
CM_ SG_ 850 ALV_ADAS_AHB_DOW "Alive Counter";
CM_ SG_ 850 ADAS_AHB_sens_Feed "Auto headlight high beam sensitivity Feedback";
CM_ SG_ 850 ADAS_AHB_Mode_Feed "Auto headlight high beam On off Feedback";
CM_ SG_ 850 ADAS_AHB_check "Auto headlight high beam control Check";
CM_ SG_ 850 ADAS_AHB_state "Auto headlight high beam control State";
CM_ SG_ 850 ADAS_DOW_WarnRight "Right Door Open Warning";
CM_ SG_ 850 ADAS_DOW_SndWarn "Door Open Sound Warning en disable";
CM_ SG_ 850 ADAS_DOW_state "Door Open Warning State";
CM_ SG_ 850 ADAS_DOW_check "Door Opening Warning Check";
CM_ SG_ 850 ADAS_DOW_WarnLeft "Left Door Open Warning";
CM_ SG_ 850 ADAS_DOW_Mode_Feed "Door Open Warning Mode select Feedback";
CM_ SG_ 850 ADAS_AHB_RBPos "Right High Beam Position Request Signal";
CM_ SG_ 850 ADAS_AHB_LBPos "Left High Beam Position Request Signal";
CM_ SG_ 851 CHKSM_ADAS_ACC "Checksum";
CM_ SG_ 851 ALV_ADAS_ACC "Alive Counter";
CM_ SG_ 851 ADAS_ACC_ObjDetec "Lead Object Detected or not";
CM_ SG_ 851 ADAS_ISA_check "Inteligent Speed adaptation Check";
CM_ SG_ 851 ADAS_ISA_Mode_SW_Feed "Feedback of ISA On off(From Steering wheel button)";
CM_ SG_ 851 ADAS_TagSpeed_ICON_Feed "ICON Feedback Request for Target Speed Feedback Display";
CM_ SG_ 851 ADAS_ISA_PopUp_Feed "PopUP Messaging for ISA function";
CM_ SG_ 851 ADAS_ISA_Btn_Feed "Feedback of ISA On Off Button";
CM_ SG_ 851 ADAS_ACC_DistSet_upper_Feed "Feedback of Object Vehicle Gap Distance Adjustment (Increase Button)";
CM_ SG_ 851 ADAS_ACC_TimeGapSet "Adaptive Cruise Control time gap setting";
CM_ SG_ 851 ADAS_ACC_State "The signal indicates the status of the Adaptive Cruise Control function";
CM_ SG_ 851 ADAS_ACC_TagSpeed "Adaptive Cruise Control speed setting";
CM_ SG_ 851 ADAS_ACC_PopUp_Feed "PopUP Messaging for ACC function";
CM_ SG_ 851 ADAS_ACC_check "Adaptive Cruise Control Check";
CM_ SG_ 851 ADAS_ISA_ICON_Feed "ICON Feedback Request for ISA function";
CM_ SG_ 851 ADAS_ACC_DistSet_lower_Feed "Feedback of Object Vehicle Gap Distance Adjustment ( Reduction Button)";
CM_ SG_ 851 ADAS_ACC_SpdSet_upper_Feed "Feedback of Subject Vehicle Speed Setting (Increase Button)";
CM_ SG_ 851 ADAS_ACC_SpdSet_lower_Feed "Feedback of Subject Vehicle Speed Setting ( Reduction Button)";
CM_ SG_ 851 ADAS_ACC_On_Feed "Feedback of ACC On Off Button";
CM_ SG_ 851 ADAS_ACC_Set_Feed "Feedback of ACC Set Button";
CM_ SG_ 851 ADAS_ACC_CnlBtn_Feed "Feedback of ACC Cancel Button";
CM_ SG_ 851 ADAS_ACC_Res_Feed "Feedback of ACC Resume Button";
CM_ SG_ 851 ADAS_ACC_ICON_Feed "ICON Feedback Request for ACC function";
CM_ SG_ 851 ADAS_ISA_Status "The signal indicates the status of the ISA function";
CM_ SG_ 852 CHKSM_MHU_ADAS_req "Checksum";
CM_ SG_ 852 ALV_MHU_ADAS_req "Alive Counter";
CM_ SG_ 852 MHU_FCW_Mode "FCW ABE mode select";
CM_ SG_ 852 MHU_FCW_sens "FCW Sensitivity";
CM_ SG_ 852 MHU_AEB_Mode "AEB Confirmation";
CM_ SG_ 852 MHU_RAEB_Mode "RAEB mode select";
CM_ SG_ 852 MHU_LA_sens "LA Sensitivity (Early   Normal   Late)";
CM_ SG_ 852 MHU_LA_AudWarning "Setting Audible warning for LA On off";
CM_ SG_ 852 MHU_BSD_On "BSD On off";
CM_ SG_ 852 MHU_BSD_AudWarning "Setting Audible warning for BSD On off";
CM_ SG_ 852 MHU_RCTA_On "RCTA On off";
CM_ SG_ 852 MHU_RCTA_sens "RCTA Sensitivity (Early   Normal   Late)";
CM_ SG_ 852 MHU_PA_On "PA On off";
CM_ SG_ 852 MHU_AHB_On "AHB On off";
CM_ SG_ 852 MHU_IA_Mode "IA mode select";
CM_ SG_ 852 MHU_TSR_Mode "TSR Mode selection";
CM_ SG_ 852 MHU_DOW_Mode "Door Open Warning Mode select";
CM_ SG_ 852 MHU_AHB_sens "AHB Sensitivity (Early   Normal   Late)";
CM_ SG_ 852 MHU_LA_Mode "Lane Assistance Mode select";
CM_ SG_ 852 MHU_SET_TSR_AudWarn "TSR Audible Warning On Off";
CM_ SG_ 852 MHU_SET_TSR_SLAert "TSR Speed Limit Alert select";
CM_ SG_ 852 MHU_ESA_ON "ESA function on/off";
CM_ SG_ 852 MHU_ELKA_ON "ELKA function ON/OFF";
CM_ SG_ 852 MHU_ALC_ON "Turn ALCA on/off";
CM_ SG_ 853 CHKSM_ADAS_CMP_CHECK "Checksum";
CM_ SG_ 853 ALV_ADAS_CMP_CHECK "Alive Counter";
CM_ SG_ 853 ADAS_PAUSS_FaultFLO "This signal shows the position of Fault Ultrasonic sensor for Parking Assist";
CM_ SG_ 853 ADAS_PAUSS_FaultFLI "This signal shows the position of Fault Ultrasonic sensor for Parking Assist";
CM_ SG_ 853 ADAS_PAUSS_check "Ultrasonic sensor for Parking Assist check";
CM_ SG_ 853 ADAS_PAUSS_FaultRLO "This signal shows the position of Fault Ultrasonic sensor for Parking Assist";
CM_ SG_ 853 ADAS_PAUSS_FaultFRI "This signal shows the position of Fault Ultrasonic sensor for Parking Assist";
CM_ SG_ 853 ADAS_FPA_check "Front Parking Assist Check";
CM_ SG_ 853 ADAS_PAUSS_FaultRLI "This signal shows the position of Fault Ultrasonic sensor for Parking Assist";
CM_ SG_ 853 ADAS_PAUSS_FaultRRO "This signal shows the position of Fault Ultrasonic sensor for Parking Assist";
CM_ SG_ 853 ADAS_PAUSS_FaultRRI "This signal shows the position of Fault Ultrasonic sensor for Parking Assist";
CM_ SG_ 853 ADAS_RPA_check "Rear Parking Assist Check";
CM_ SG_ 853 ADAS_PAUSS_FaultFRO "This signal shows the position of Fault Ultrasonic sensor for Parking Assist";
CM_ SG_ 880 CRC_MHU_SBR_Status "Checksum";
CM_ SG_ 880 ALV_MHU_SBR_Status "Alive Counter";
CM_ SG_ 880 SBR_STAT_Chime "Status of SBR Chime";
CM_ SG_ 880 SBR_STAT_Telltale "Status of SBR telltale";
CM_ SG_ 880 SBR_STAT_Active "Status of Seatbelt reminder";
CM_ SG_ 883 CHKSM_PDCU_PA "Checksum";
CM_ SG_ 883 ALV_PDCU_PA "Alive Counter";
CM_ SG_ 883 PDCU_PA_State "This signal indicates the status of Front Parking System state";
CM_ SG_ 883 PDCU_PA_AutoOn_Feed "This signal indicates the status of Auto Front Parking Assist";
CM_ SG_ 883 PDCU_PA_AlertFLI "This signal indicates the warning level of Front Left Inner USS";
CM_ SG_ 883 PDCU_PA_AlertFLO "This signal indicates the warning level of Front Left Outer USS";
CM_ SG_ 883 PDCU_PA_AlertFRI "This signal indicates the warning level of Front Right Inner USS";
CM_ SG_ 883 PDCU_PA_AlertFRO "This signal indicates the warning level of Front Right Outer USS";
CM_ SG_ 883 PDCU_PA_AlertRLI "This signal indicates the warning level of Rear Left Inner USS";
CM_ SG_ 883 PDCU_PA_AlertRLO "This signal indicates the warning level of Rear Left Outer USS";
CM_ SG_ 883 PDCU_PA_AlertRRI "This signal indicates the warning level of Rear Right Inner USS";
CM_ SG_ 883 PDCU_PA_AlertRRO "This signal indicates the warning level of Rear Right Outer USS";
CM_ SG_ 883 PDCU_PA_FPA_Check "FPA function status";
CM_ SG_ 883 PDCU_PA_RPA_Check "FPA function status";
CM_ SG_ 884 PDCU_FPA_DistFLI "This signal indicates the distance of obstacle";
CM_ SG_ 884 PDCU_FPA_DistFLO "This signal indicates the distance of obstacle";
CM_ SG_ 884 PDCU_FPA_DistFRI "This signal indicates the distance of obstacle";
CM_ SG_ 884 PDCU_FPA_DistFRO "This signal indicates the distance of obstacle";
CM_ SG_ 884 PDCU_RPA_DistRLI "This signal indicates the distance of obstacle";
CM_ SG_ 884 PDCU_RPA_DistRLO "This signal indicates the distance of obstacle";
CM_ SG_ 884 PDCU_RPA_DistRRI "This signal indicates the distance of obstacle";
CM_ SG_ 884 PDCU_RPA_DistRRO "This signal indicates the distance of obstacle";
CM_ SG_ 885 Checksum_0x375 "Checksum";
CM_ SG_ 885 Rolling_Counter_0x375 "Rolling Counter";
CM_ SG_ 885 BMS_PreChgRelay_ERR "Precahrge relay is not working properly ";
CM_ SG_ 885 BMS_TotalNegRelay_ERR "Main Negative Relay Error ";
CM_ SG_ 885 BMS_MainPosRelay_ERR "Main Position Relay Error ";
CM_ SG_ 885 BMS_MainPosRelay_STS "Main Positive Relay Status ";
CM_ SG_ 885 BMS_PreChgRelay_STS "PreCharge Relay Status ";
CM_ SG_ 885 BMS_TotalNegRelay_STS "Main Negative Relay Status ";
CM_ BO_ 886 "USS RPA warning and sensor status";
CM_ SG_ 886 CHKSM_USS_RPA "Checksum";
CM_ SG_ 886 ALV_USS_RPA "Alive Counter";
CM_ SG_ 886 USS_RPA_state "This signal indicates the status of Rear Parking System state";
CM_ SG_ 886 USS_RPA_AlertRLI "This signal indicates the warning level of Rear Left Inner USS";
CM_ SG_ 886 USS_RPA_AlertRLO "This signal indicates the warning level of Rear Left Outer USS";
CM_ SG_ 886 USS_RPA_AlertRRI "This signal indicates the warning level of Rear Right Inner USS";
CM_ SG_ 886 USS_RPA_AlertRRO "This signal indicates the warning level of Rear Right Outer USS";
CM_ SG_ 886 USS_RPA_SensorRLI "This signal indicates the status of Rear Left Inner USS sensor";
CM_ SG_ 886 USS_RPA_SensorRLO "This signal indicates the status of Rear Left Outer USS sensor";
CM_ SG_ 886 USS_RPA_SensorRRI "This signal indicates the status of Rear Right Inner USS sensor";
CM_ SG_ 886 USS_RPA_SensorRRO "This signal indicates the status of Rear Right Outer USS sensor";
CM_ BO_ 887 "USS FPA warning and sensor status";
CM_ SG_ 887 CHKSM_USS_FPA "Checksum";
CM_ SG_ 887 ALV_USS_FPA "Alive Counter";
CM_ SG_ 887 USS_FPA_state "This signal indicates the status of Front Parking System state";
CM_ SG_ 887 USS_FPA_AutoOn_Feed "This signal indicates the status of Auto Front Parking Assist";
CM_ SG_ 887 USS_FPA_AlertFLI "This signal indicates the warning level of Front Left Inner USS";
CM_ SG_ 887 USS_FPA_AlertFLO "This signal indicates the warning level of Front Left Outer USS";
CM_ SG_ 887 USS_FPA_AlertFRI "This signal indicates the warning level of Front Right Inner USS";
CM_ SG_ 887 USS_FPA_AlertFRO "This signal indicates the warning level of Front Right Outer USS";
CM_ SG_ 887 USS_FPA_SensorFLI "This signal indicates the status of Front Left Inner USS sensor";
CM_ SG_ 887 USS_FPA_SensorFLO "This signal indicates the status of Front Left Outer USS sensor";
CM_ SG_ 887 USS_FPA_SensorFRI "This signal indicates the status of Front Right Inner USS sensor";
CM_ SG_ 887 USS_FPA_SensorFRO "This signal indicates the status of Front Right Outer USS sensor";
CM_ BO_ 888 "USS RPA distance of obstacle";
CM_ SG_ 888 CHKSM_RawDist_RPA "Checksum";
CM_ SG_ 888 ALV_RawDist_RPA "Alive counter";
CM_ SG_ 888 USS_RPA_DistRLI "This signal indicates the distance of obstacle";
CM_ SG_ 888 USS_RPA_DistRLO "This signal indicates the distance of obstacle";
CM_ SG_ 888 USS_RPA_DistRRI "This signal indicates the distance of obstacle";
CM_ SG_ 888 USS_RPA_DistRRO "This signal indicates the distance of obstacle";
CM_ BO_ 889 "USS FPA distance of obstacle";
CM_ SG_ 889 CHKSM_RawDist_FPA "Checksum";
CM_ SG_ 889 ALV_RawDist_FPA "Alive counter";
CM_ SG_ 889 USS_FPA_DistFLI "This signal indicates the distance of obstacle";
CM_ SG_ 889 USS_FPA_DistFLO "This signal indicates the distance of obstacle";
CM_ SG_ 889 USS_FPA_DistFRI "This signal indicates the distance of obstacle";
CM_ SG_ 889 USS_FPA_DistFRO "This signal indicates the distance of obstacle";
CM_ SG_ 896 VIN_Byte1 "This signal contains the seventh last digit of the chassis number. (The individual digits are encoded in ASCII characters.)
Bit 0: LSB, Bit 7: MSB";
CM_ SG_ 896 VIN_Byte2 "This signal contains the sixth last digit of the chassis number. (The individual digits are encoded in ASCII characters.)
Bit 0: LSB, Bit 7: MSB";
CM_ SG_ 896 VIN_Byte3 "This signal contains the fifth last digit of the chassis number. (The individual digits are encoded in ASCII characters.)
Bit 0: LSB, Bit 7: MSB";
CM_ SG_ 896 VIN_Byte4 "This signal contains the fourth last digit of the chassis number. (The individual digits are encoded in ASCII characters.)
Bit 0: LSB, Bit 7: MSB";
CM_ SG_ 896 VIN_Byte5 "This signal contains the third last digit of the chassis number. (The individual digits are encoded in ASCII characters.)
Bit 0: LSB, Bit 7: MSB";
CM_ SG_ 896 VIN_Byte6 "This signal contains the penultimate digit of the chassis number. (The individual digits are encoded in ASCII characters.)
Bit 0: LSB, Bit 7: MSB";
CM_ SG_ 896 VIN_Byte7 "This signal contains the last digit of the chassis number. (The individual digits are encoded in ASCII characters.)
Bit 0: LSB, Bit 7: MSB";
CM_ SG_ 897 CHKSM_ACM_SEAT_OCCUPATION "Checksum";
CM_ SG_ 897 ALV_ACM_SEAT_OCCUPATION "Alive Counter";
CM_ SG_ 897 ACM_Seat_Occupancy_Passenger "Signal to indicate status of occupancy";
CM_ SG_ 897 ACM_Seat_Occupancy_2nd_Row_Dri "Signal to indicate status of occupancy";
CM_ SG_ 897 ACM_Seat_Occupancy_2nd_Row_Pas "Signal to indicate status of occupancy";
CM_ SG_ 897 ACM_Seat_Occupancy_2nd_Row_Mid "Signal to indicate status of occupancy";
CM_ SG_ 897 ACM_Seat_Belt_Status_Passenger "Seatbelt status for seatbelt reminder function";
CM_ SG_ 897 ACM_Seat_Belt_Status_Driver "Seatbelt status for seatbelt reminder function";
CM_ SG_ 897 ACM_Seat_Belt_Status_2nd_Row_Dri "Seatbelt status for seatbelt reminder function";
CM_ SG_ 897 ACM_Seat_Belt_Status_2nd_Row_Mid "Seatbelt status for seatbelt reminder function";
CM_ SG_ 897 ACM_Seat_Belt_Status_2nd_Row_Pas "Seatbelt status for seatbelt reminder function";
CM_ BO_ 882 "Obstacle distance at Rear";
CM_ SG_ 882 CHKSM_PDC_RearDist "Checksum";
CM_ SG_ 882 ALV_PDC_RearDist "Alive Counter";
CM_ SG_ 882 PDC_ObstacleDistance_RSL "Obstacle distance at Rear Side Left zone";
CM_ SG_ 882 PDC_ObstacleDistance_RL "Obstacle distance at  Rear Left zone";
CM_ SG_ 882 PDC_ObstacleDistance_RML "Obstacle distance at  Rear  Middle Left zone";
CM_ SG_ 882 PDC_ObstacleDistance_RMR "Obstacle distance at  Rear Middle Right zone";
CM_ SG_ 882 PDC_ObstacleDistance_RR "Obstacle distance at  Rear Right zone";
CM_ SG_ 882 PDC_ObstacleDistance_RSR "Obstacle distance at  Rear Side Right zone";
CM_ BO_ 881 "Obstacle distance at Front";
CM_ SG_ 881 CHKSM_PDC_FrontDist "Checksum";
CM_ SG_ 881 ALV_PDC_FrontDist "Alive Counter";
CM_ SG_ 881 PDC_ObstacleDistance_FSL "Obstacle distance at Front Side Left zone";
CM_ SG_ 881 PDC_ObstacleDistance_FL "Obstacle distance at  Front Left zone";
CM_ SG_ 881 PDC_ObstacleDistance_FML "Obstacle distance at  Front  Middle Left zone";
CM_ SG_ 881 PDC_ObstacleDistance_FMR "Obstacle distance at  Front Middle Right zone";
CM_ SG_ 881 PDC_ObstacleDistance_FR "Obstacle distance at  Front Right zone";
CM_ SG_ 881 PDC_ObstacleDistance_FSR "Obstacle distance at  Front Side Right zone";
CM_ SG_ 905 VCU_IMMO_Sts "IMMO status";
CM_ SG_ 905 SECCAN_VCU_IMMO_Sts "Seed generated from Secure CAN algorithm";
CM_ SG_ 915 MHU_SET_HudRotateLvl "Set Rotate angle";
CM_ SG_ 915 MHU_SET_HudHeightLvl "Set height position of HUD Image in Windshield";
CM_ SG_ 922 MHU_Immo_Byte_0 "MHU Authentication signal byte 0";
CM_ SG_ 922 MHU_Immo_Byte_1 "MHU Authentication signal byte 1";
CM_ SG_ 922 MHU_Immo_Byte_2 "MHU Authentication signal byte 2";
CM_ SG_ 922 MHU_Immo_Byte_3 "MHU Authentication signal byte 3";
CM_ SG_ 922 MHU_Immo_Byte_4 "MHU Authentication signal byte 4";
CM_ SG_ 922 MHU_Immo_Byte_5 "MHU Authentication signal byte 5";
CM_ SG_ 922 MHU_Immo_Byte_6 "MHU Authentication signal byte 6";
CM_ SG_ 922 MHU_Immo_Byte_7 "MHU Authentication signal byte 7";
CM_ SG_ 923 BCM_Immo_MHU_Byte_0 "BCM Authentication signal byte 0 with MHU";
CM_ SG_ 923 BCM_Immo_MHU_Byte_1 "BCM Authentication signal byte 1 with MHU";
CM_ SG_ 923 BCM_Immo_MHU_Byte_2 "BCM Authentication signal byte 2 with MHU";
CM_ SG_ 923 BCM_Immo_MHU_Byte_3 "BCM Authentication signal byte 3 with MHU";
CM_ SG_ 923 BCM_Immo_MHU_Byte_4 "BCM Authentication signal byte 4 with MHU";
CM_ SG_ 923 BCM_Immo_MHU_Byte_5 "BCM Authentication signal byte 5 with MHU";
CM_ SG_ 923 BCM_Immo_MHU_Byte_6 "BCM Authentication signal byte 6 with MHU";
CM_ SG_ 923 BCM_Immo_MHU_Byte_7 "BCM Authentication signal byte 7 with MHU";
CM_ SG_ 925 CHKSM_BCM_HighBeam_PosReq "Checksum";
CM_ SG_ 925 ALIVE_BCM_HighBeam_PosReq "Alive counter";
CM_ SG_ 925 BCM_ADAS_AHB_state "AHB state";
CM_ SG_ 925 BCM_AHB_Override "Automatic High Beam Override by Driver using Stalk lever";
CM_ SG_ 925 BCM_ADAS_AHB_RBPos_feed "High Beam Position Request Signal(Right Ramp)";
CM_ SG_ 925 BCM_ADAS_AHB_LBPos_feed "High Beam Position Request Signal(Left Ramp)";
CM_ SG_ 925 BCM_AHB_ICON_Feed "AHB ICON Feedback";
CM_ SG_ 943 MHU_UTF8Character_Byte1 "UTF8 Character byte 1";
CM_ SG_ 943 MHU_UTF8Character_Byte2 "UTF8 Character byte 2";
CM_ SG_ 943 MHU_UTF8Character_Byte3 "UTF8 Character byte 3";
CM_ SG_ 943 MHU_UTF8Character_Byte4 "UTF8 Character byte 4";
CM_ SG_ 943 MHU_UTF8Character_Byte5 "UTF8 Character byte 5";
CM_ SG_ 943 MHU_UTF8Character_Byte6 "UTF8 Character byte 6";
CM_ SG_ 943 MHU_IPC_ID "dIDBribe which message will be send; 0x4 0x5 in Unicode logical value; If value 4 is used there shall be songname Album and artist send from MHU divide value 1 3 with: 0x03(hex)";
CM_ SG_ 943 MHU_TotalMessages "Total number of messages.";
CM_ SG_ 943 MHU_MessageNumber "Current number of Messages; start with 1";
CM_ SG_ 964 MHU_Nav_State "Navigation state";
CM_ SG_ 964 MHU_NavSource "the actived Source provide Navigation for vehicle";
CM_ SG_ 964 MHU_Nav_DistanceToNextTurn "Value of Distance to next Turn";
CM_ SG_ 964 MHU_Nav_DistanceToNextTurnUnits "Units for Distance to next Turn";
CM_ SG_ 964 MHU_Nav_TBT_Icon "Turn by Turn Icon";
CM_ SG_ 964 MHU_Nav_ImageChannel_Ready "Image channel is ready to start streaming Nav image from MHU side";
CM_ SG_ 964 MHU_Nav_Language "The navigation engine langue";
CM_ SG_ 964 SECCAN_NAV_DISP "Seed generated from Secure CAN algorithm";
CM_ SG_ 965 MHU_NavGuidance_TotalMsg "Total message package, set value as 0 if want to clear Navigation text";
CM_ SG_ 965 MHU_NavGuidance_MsgNum "Message order, start from 1";
CM_ SG_ 965 MHU_NavGuidance_UTF8_Byte1 "Navigation content by UTF-8 byte 1";
CM_ SG_ 965 MHU_NavGuidance_UTF8_Byte2 "Navigation content by UTF-8 byte 2";
CM_ SG_ 965 MHU_NavGuidance_UTF8_Byte3 "Navigation content by UTF-8 byte 3";
CM_ SG_ 965 MHU_NavGuidance_UTF8_Byte4 "Navigation content by UTF-8 byte 4";
CM_ SG_ 965 MHU_NavGuidance_UTF8_Byte5 "Navigation content by UTF-8 byte 5";
CM_ SG_ 965 MHU_NavGuidance_UTF8_Byte6 "Navigation content by UTF-8 byte 6";
CM_ SG_ 966 MHU_NavDist_MsgNum "Message order, start from 1";
CM_ SG_ 966 MHU_NavDist_TotalMsg "Total message package, set value as 0 if want to clear Navigation text";
CM_ SG_ 966 MHU_NavDist_UTF8_Byte1 "Navigation content by UTF-8 byte 1";
CM_ SG_ 966 MHU_NavDist_UTF8_Byte2 "Navigation content by UTF-8 byte 2";
CM_ SG_ 966 MHU_NavDist_UTF8_Byte3 "Navigation content by UTF-8 byte 3";
CM_ SG_ 966 MHU_NavDist_UTF8_Byte4 "Navigation content by UTF-8 byte 4";
CM_ SG_ 966 MHU_NavDist_UTF8_Byte5 "Navigation content by UTF-8 byte 5";
CM_ SG_ 966 MHU_NavDist_UTF8_Byte6 "Navigation content by UTF-8 byte 6";
CM_ SG_ 992 CRC_VCU_HVsystem_status "Checksum";
CM_ SG_ 992 ALIV_VCU_HVsystem_status "Alive counter";
CM_ SG_ 992 VCU_RunningRange "Estimated running range ( at present )";
CM_ SG_ 992 VCU_RunningRange_chrg_estSts "Status of estimation running range after charged by current charging condition ( max chg.current, chg.time, ?)";
CM_ SG_ 992 VCU_RunningRange_charged "Estimated running range after charged by current charging condition ( max chg.current, chg.time, ?)";
CM_ SG_ 992 VCU_HVbatSoc_charged "Estimated HVBattery SOC by current charging condition ( max chg.current, chg.time, ?)";
CM_ SG_ 992 VCU_HVbatSoc_charged_estStatus "Status of SOC Estimation by current charging condition ( max chg.current, chg.time, ?)";
CM_ SG_ 993 CRC_VCU_HMI_Info "Checksum";
CM_ SG_ 993 ALIV_VCU_HMI_Info "Alive counter";
CM_ SG_ 993 VCU_SetCruiseSpd "Set Cruise Speed";
CM_ SG_ 993 VCU_CruiseCtrlSts "Cruise state";
CM_ SG_ 993 VCU_MHU_Ack_ChgSche_stt "Status Enabled/ Disabled of Schedule Charging acknowledged by VCU base on request from MHU 0x403 MHU_ChargeScheduleSet.";
CM_ SG_ 993 VCU_MHU_Ack_TargetSOC "Target SOC acknowledged by VCU base on request from MHU";
CM_ SG_ 993 VCU_ValetMode_sts "Status indicate valet mode is effected to VCU";
CM_ SG_ 993 VCU_ValetMode_MaxSpeedSts "Max speed setting of Valet mode";
CM_ SG_ 993 SECCAN_VCU_HMI_Info "Seed generated from Secure CAN algorithm";
CM_ SG_ 1015 CHSKM_MFS_Control_Button "Checksum";
CM_ SG_ 1015 ALV_MFS_Control_Button "Alive Counter";
CM_ SG_ 1015 MFS_VoiceRecognitionOn_Off "VoiceRecognition control";
CM_ SG_ 1015 MFS_ISAControl "ISA Control";
CM_ SG_ 1015 MFS_CruiseSpeedIncrease "Cruise Speed Increase";
CM_ SG_ 1015 MFS_TelephoneCall_EndCall "Telephone Call functionality control  ";
CM_ SG_ 1015 MFS_LKAControl "Line Keep Assistance/Line Departure warning Control";
CM_ SG_ 1015 MFS_CruiseGapIncrease "Cruise Gap Increase";
CM_ SG_ 1015 MFS_CruiseOn_Off "Cruise control On/Off";
CM_ SG_ 1015 MFS_CruiseGapDecrease "Cruise Gap Decrease";
CM_ SG_ 1015 MFS_CAN_RESControl "From standy, M1 and M2 to be cancelled
From being cancelled, M1 or M2 to be resume to it previous state
";
CM_ SG_ 1015 MFS_CruiseSpeedDecrease "Cruise Speed Decrease";
CM_ SG_ 1015 MFS_M2Control "Auto Steering and Speed Activation";
CM_ SG_ 1015 MFS_SourseControl "Resourse Control";
CM_ SG_ 1015 MFS_UpControl "Up Control";
CM_ SG_ 1015 MFS_DownControl "Down Control";
CM_ SG_ 1015 MFS_LeftControl "Left Control";
CM_ SG_ 1015 MFS_Failure "Multi-Funtion Switch Failure";
CM_ SG_ 1015 MFS_RightControl "Right Control";
CM_ SG_ 1015 MFS_OK_Control "OK Control";
CM_ SG_ 1020 CRC_XGW_FOTA_StsConfirm "FOTA global status message checksum";
CM_ SG_ 1020 ALIV_XGW_FOTA_StsConfirm "FOTA global status message alive counter";
CM_ SG_ 1020 XGW_FOTA_StateConfirm "XGW FOTA global status confirmation";
CM_ SG_ 1020 XGW_FOTA_Error_Code " FOTA Error Code
Bit 5 : IgnState error = 1
Bit 4 : OBD port in active = 1
Bit 3 : Request state error = 1
Bit 2 : 0
Bit 1 : SysVoltage error = 1
Bit 0 : VehSpd error = 1
";
CM_ SG_ 1025 MHU_SET_SunroofGlassLevel "Adjust opening level of sunroof glass";
CM_ SG_ 1025 MHU_SET_BonnetState "Open Bonet latch";
CM_ SG_ 1025 MHU_SET_TrunkState "Open and close trunk tailgate";
CM_ SG_ 1025 MHU_SET_SunroofShaderLevel "Adjust opening level of sunroof shader";
CM_ SG_ 1025 MHU_SET_DoorSpeedLock "Setting Door speed lock mode";
CM_ SG_ 1025 MHU_SET_WelcomeTriggerCondition "Setting Welcome trigger condition";
CM_ SG_ 1025 MHU_SET_AutoSunroof "Setting Auto sunroof mode ON OFF follow Rain sensor";
CM_ SG_ 1025 MHU_SET_RemoteDoorUnlock "Setting which door will be unlocked when car unlock";
CM_ SG_ 1025 MHU_SET_RemoteLockFeedback "Setting remote car lock feedback mechanism";
CM_ SG_ 1025 MHU_SET_FootkickSensor "On Off Footkick sensor to open Trunk latch";
CM_ SG_ 1025 MHU_SET_AutoUnlockDoor "Setting auto unlock door mode Park Engine off Manual";
CM_ SG_ 1025 MHU_SET_RemoteUnlockFeedback "Setting remote car unlock feedback mechanism";
CM_ SG_ 1025 MHU_SET_Childlock "Softbutton for ON/OFF of childlock";
CM_ SG_ 1025 MHU_SET_SunroofInitialize "Initialise command to sunroof to manual open close when face antipinch";
CM_ SG_ 1025 WalkawayDoorLock "MHU set walk away door lock On/Off";
CM_ SG_ 1026 MHU_SET_DayTimeRunningLight "On Off Day Time Running Light";
CM_ SG_ 1026 MHU_SET_RearFogLight "On/Off Rear Fog Light";
CM_ SG_ 1026 MHU_SET_FrontFogLight "On/Off Front Fog Light";
CM_ SG_ 1026 MHU_SET_WelcomeDimmingHeadlight "On/Off Welcome headlight dimming";
CM_ SG_ 1026 MHU_SET_AmbientLightBrighness "Change Ambient light brighness percent";
CM_ SG_ 1026 MHU_SET_FootwellLightMode "Change Footwell Light mode";
CM_ SG_ 1026 MHU_SET_ExteriorLight "Change Exterior light mode";
CM_ SG_ 1026 MHU_SET_TRWarningSignals "Turn on/off BCM Thermal runaway warning signals";
CM_ SG_ 1026 MHU_SET_FrontDomeLamp "Setting On/Off/Auto Front Dome Lamp";
CM_ SG_ 1026 MHU_SET_SwitchLightBrightness "Change Brighness level of Switch illumination";
CM_ SG_ 1026 MHU_SET_HazardLight "On/Off HazardLight function";
CM_ SG_ 1026 MHU_SET_FollowMeHome "Change follow me home headlamp mode and delay";
CM_ SG_ 1026 MHU_SET_ADB_AHB "On/off ADB/AHB function, ADB in ECE version, AHB in SAE version
";
CM_ SG_ 1026 MHU_SET_WelcomeAnimation "selection of different welcome/goodbye animations";
CM_ SG_ 1026 MHU_SET_ChargingAnimation "De-/Activation of charging animation";
CM_ SG_ 1026 MHU_SET_Auto_Leveling "On/Off Auto-Leveling function";
CM_ SG_ 1027 CHKSM_MHU_EVSetting "Checksum for EV setting";
CM_ SG_ 1027 ALV_MHU_EVSetting "Alive Counter for EV Setting";
CM_ SG_ 1027 MHU_AutoP_Setting "Request for VCU to ON/OFF Auto P setting";
CM_ SG_ 1027 MHU_VCU_CreepDisable_stt "Request for VCU to disable creep function";
CM_ SG_ 1027 MHU_BrakeRegenMode "Brake Regen Style";
CM_ SG_ 1027 MHU_ChargeSetTargetSOC "Request for VCU to set target HV SOC";
CM_ SG_ 1027 MHU_ChargeScheduleSet "Request for VCU to enable/disable Charging Scheduling";
CM_ SG_ 1027 MHU_ChargingRequest "Request for VCU to ON/OFF Charging when schedule is reached";
CM_ SG_ 1027 MHU_ChgPort_Open_req "Request to open charging port(release latch)";
CM_ SG_ 1027 MHU_SET_DrivingModeSwitch "Change vehicle driving mode";
CM_ SG_ 1027 MHU_ValetMode_Activation "Activate Valet mode from MHU";
CM_ SG_ 1027 MHU_ValetMode_MaxSpeed "Setting of maximum allowable in valet mode";
CM_ SG_ 1027 MHU_ChargingCurrentLimit "Request VCU the max charging current at the rush hour - Apply for AC charging only at home";
CM_ SG_ 1027 MHU_SET_ActivePreCondition "Request active PreCondition State (schedule heating battery)";
CM_ SG_ 1027 MHU_SpdLim_Override "Extra Override Speed in Speed Limiter";
CM_ SG_ 1028 MHU_SET_LeftMirrorPosX "Set left mirror left right position";
CM_ SG_ 1028 MHU_SET_LeftMirrorPosY "Set left mirror up down position";
CM_ SG_ 1028 MHU_SET_RightMirrorPosX "Set right mirror left/right position";
CM_ SG_ 1028 MHU_SET_RightMirrorPosY "Set right mirror up/down position";
CM_ SG_ 1028 MHU_SET_MirrorAdjustLeft "Enter setting Mirror position mode";
CM_ SG_ 1028 MHU_SET_MirrorAdjustRight "Enter setting Mirror position mode";
CM_ SG_ 1028 MHU_SET_MirrorManual "Manual Fold/Unfold";
CM_ SG_ 1028 SECCAN_MirrorAdj "Seed generated from Secure CAN algorithm";
CM_ SG_ 1029 MHU_SET_CCUF_AirCondition "On Off Air Condition";
CM_ SG_ 1029 MHU_SET_CCUF_AutoAC "On Off Auto Air Condition";
CM_ SG_ 1029 MHU_SET_CCUF_MaxAc "On Off Max Air Condition for 2 zone";
CM_ SG_ 1029 MHU_SET_CCUF_FanSpeed "Adjust Fan speed with 6 level";
CM_ SG_ 1029 MHU_SET_CCUF_Recirculation "Change recirculation mode inside, ouside, auto";
CM_ SG_ 1029 MHU_SET_CCUF_Ion "On Off Air ionizer";
CM_ SG_ 1029 MHU_SET_CCUF_FlapPosition "Change Flap position Face, Feet, Front defrost";
CM_ SG_ 1029 MHU_SET_CCUF_SyncClimateZone "On Off sync temperature between zone";
CM_ SG_ 1029 MHU_SET_CCUF_TempDriver "Change Driver zone temperature";
CM_ SG_ 1029 MHU_SET_CCUF_TempPassenger "Change Passenger zone temperature";
CM_ SG_ 1029 MHU_SET_CCUF_FrontDefrost "Change Flap poition to Front Defrost";

BA_DEF_ BO_  "GenMsgSendType" ENUM "Cyclic","NotUsed","NotUsed","NotUsed","NotUsed","NotUsed","NotUsed","IfActive","NoMsgSendType","NotUsed";
BA_DEF_ BO_  "GenMsgILSupport" ENUM "No","Yes";
BA_DEF_ BO_  "DiagResponse" ENUM "No","Yes";
BA_DEF_ BO_  "DiagRequest" ENUM "No","Yes";
BA_DEF_ BO_  "NmAsrMessage" ENUM "No","Yes";
BA_DEF_ BO_  "DiagState" ENUM "No","Yes";
BA_DEF_ BO_  "DiagUudtResponse" ENUM "False","True";
BA_DEF_ BO_  "GenMsgStartDelayTime" INT 0 65535;
BA_DEF_ BO_  "GenMsgDelayTime" INT 0 0;
BA_DEF_ BO_  "GenMsgNrOfRepetition" INT 0 0;
BA_DEF_ BO_  "GenMsgCycleTimeFast" INT 0 0;
BA_DEF_ BO_  "GenMsgCycleTime" INT 0 0;
BA_DEF_ SG_  "GenSigSendType" ENUM "Cyclic","OnWrite","OnWriteWithRepetition","OnChange","OnChangeWithRepetition","IfActive","IfActiveWithRepetition","NoSigSendType","NotUsed","NotUsed","NotUsed","NotUsed","NotUsed";
BA_DEF_ SG_  "InvalidValue" STRING;
BA_DEF_ SG_  "GenSigStartValue" INT 0 0;
BA_DEF_ SG_  "GenSigTimeoutTime_ALL" INT 0 65535;
BA_DEF_DEF_  "DiagRequest" "No";
BA_DEF_DEF_  "DiagResponse" "No";
BA_DEF_DEF_  "DiagState" "No";
BA_DEF_DEF_  "DiagUudtResponse" "False";
BA_DEF_DEF_  "GenMsgCycleTime" 0;
BA_DEF_DEF_  "GenMsgCycleTimeFast" 0;
BA_DEF_DEF_  "GenMsgDelayTime" 0;
BA_DEF_DEF_  "GenMsgILSupport" "Yes";
BA_DEF_DEF_  "GenMsgNrOfRepetition" 0;
BA_DEF_DEF_  "GenMsgSendType" "NoMsgSendType";
BA_DEF_DEF_  "GenMsgStartDelayTime" 0;
BA_DEF_DEF_  "GenSigSendType" "Cyclic";
BA_DEF_DEF_  "GenSigStartValue" 0;
BA_DEF_DEF_  "GenSigTimeoutTime_ALL" 0;
BA_DEF_DEF_  "NmAsrMessage" "No";
BA_ "GenMsgCycleTime" BO_ 676 1000;
BA_ "GenMsgCycleTime" BO_ 714 100;
BA_ "GenMsgSendType" BO_ 714 0;
BA_ "GenMsgSendType" BO_ 715 0;
BA_ "GenMsgCycleTime" BO_ 715 100;
BA_ "GenMsgDelayTime" BO_ 717 50;
BA_ "GenMsgCycleTime" BO_ 720 100;
BA_ "GenMsgSendType" BO_ 720 0;
BA_ "GenMsgCycleTime" BO_ 753 100;
BA_ "GenMsgSendType" BO_ 753 0;
BA_ "GenMsgCycleTime" BO_ 760 1000;
BA_ "GenMsgSendType" BO_ 760 0;
BA_ "GenMsgCycleTime" BO_ 761 1000;
BA_ "GenMsgSendType" BO_ 761 0;
BA_ "GenMsgSendType" BO_ 768 0;
BA_ "GenMsgCycleTime" BO_ 768 1000;
BA_ "GenMsgCycleTimeFast" BO_ 768 20;
BA_ "GenMsgNrOfRepetition" BO_ 768 2;
BA_ "GenMsgCycleTime" BO_ 769 50;
BA_ "GenMsgSendType" BO_ 769 0;
BA_ "GenMsgCycleTime" BO_ 770 1000;
BA_ "GenMsgSendType" BO_ 770 0;
BA_ "GenMsgCycleTime" BO_ 773 10000;
BA_ "GenMsgILSupport" BO_ 773 0;
BA_ "GenMsgSendType" BO_ 773 0;
BA_ "GenMsgCycleTime" BO_ 775 1000;
BA_ "GenMsgSendType" BO_ 775 0;
BA_ "GenMsgCycleTimeFast" BO_ 776 100;
BA_ "GenMsgNrOfRepetition" BO_ 776 3;
BA_ "GenMsgSendType" BO_ 784 0;
BA_ "GenMsgCycleTime" BO_ 784 1000;
BA_ "GenMsgCycleTimeFast" BO_ 784 20;
BA_ "GenMsgNrOfRepetition" BO_ 784 2;
BA_ "GenMsgSendType" BO_ 771 0;
BA_ "GenMsgCycleTime" BO_ 771 100;
BA_ "GenMsgCycleTime" BO_ 787 100;
BA_ "GenMsgSendType" BO_ 787 0;
BA_ "GenMsgCycleTime" BO_ 803 100;
BA_ "GenMsgSendType" BO_ 803 0;
BA_ "GenMsgCycleTime" BO_ 804 100;
BA_ "GenMsgSendType" BO_ 804 0;
BA_ "GenMsgCycleTime" BO_ 805 100;
BA_ "GenMsgSendType" BO_ 805 0;
BA_ "GenMsgCycleTime" BO_ 806 100;
BA_ "GenMsgSendType" BO_ 806 0;
BA_ "GenMsgCycleTime" BO_ 807 1000;
BA_ "GenMsgSendType" BO_ 807 0;
BA_ "GenMsgCycleTime" BO_ 808 1000;
BA_ "GenMsgSendType" BO_ 808 0;
BA_ "GenMsgCycleTime" BO_ 809 1000;
BA_ "GenMsgSendType" BO_ 809 0;
BA_ "GenMsgCycleTime" BO_ 816 100;
BA_ "GenMsgSendType" BO_ 816 0;
BA_ "GenMsgSendType" BO_ 818 0;
BA_ "GenMsgCycleTime" BO_ 818 100;
BA_ "GenMsgSendType" BO_ 819 0;
BA_ "GenMsgCycleTime" BO_ 819 50;
BA_ "GenMsgCycleTime" BO_ 827 100;
BA_ "GenMsgSendType" BO_ 827 0;
BA_ "GenMsgCycleTime" BO_ 833 100;
BA_ "GenMsgSendType" BO_ 833 0;
BA_ "GenMsgCycleTime" BO_ 835 100;
BA_ "GenMsgSendType" BO_ 835 0;
BA_ "GenMsgCycleTime" BO_ 838 100;
BA_ "GenMsgSendType" BO_ 838 0;
BA_ "GenMsgCycleTime" BO_ 840 1000;
BA_ "GenMsgSendType" BO_ 840 0;
BA_ "GenMsgCycleTime" BO_ 841 1000;
BA_ "GenMsgSendType" BO_ 841 0;
BA_ "GenMsgCycleTime" BO_ 842 100;
BA_ "GenMsgSendType" BO_ 842 0;
BA_ "GenMsgCycleTime" BO_ 844 100;
BA_ "GenMsgSendType" BO_ 844 0;
BA_ "GenMsgCycleTime" BO_ 845 100;
BA_ "GenMsgSendType" BO_ 845 0;
BA_ "GenMsgCycleTime" BO_ 846 100;
BA_ "GenMsgSendType" BO_ 846 0;
BA_ "GenMsgCycleTime" BO_ 849 50;
BA_ "GenMsgSendType" BO_ 849 0;
BA_ "GenMsgCycleTime" BO_ 850 50;
BA_ "GenMsgSendType" BO_ 850 0;
BA_ "GenMsgCycleTime" BO_ 851 50;
BA_ "GenMsgSendType" BO_ 851 0;
BA_ "GenMsgCycleTime" BO_ 852 50;
BA_ "GenMsgSendType" BO_ 852 0;
BA_ "GenMsgSendType" BO_ 852 0;
BA_ "GenMsgCycleTime" BO_ 853 50;
BA_ "GenMsgSendType" BO_ 853 0;
BA_ "GenMsgCycleTime" BO_ 880 300;
BA_ "GenMsgSendType" BO_ 880 0;
BA_ "GenMsgSendType" BO_ 883 0;
BA_ "GenMsgCycleTime" BO_ 883 200;
BA_ "GenMsgSendType" BO_ 884 0;
BA_ "GenMsgCycleTime" BO_ 884 200;
BA_ "GenMsgCycleTime" BO_ 885 50;
BA_ "GenMsgILSupport" BO_ 885 0;
BA_ "GenMsgSendType" BO_ 885 0;
BA_ "GenMsgSendType" BO_ 886 0;
BA_ "GenMsgCycleTime" BO_ 886 200;
BA_ "GenMsgSendType" BO_ 887 0;
BA_ "GenMsgCycleTime" BO_ 887 200;
BA_ "GenMsgSendType" BO_ 888 0;
BA_ "GenMsgCycleTime" BO_ 888 200;
BA_ "GenMsgSendType" BO_ 889 0;
BA_ "GenMsgCycleTime" BO_ 889 200;
BA_ "GenMsgCycleTime" BO_ 896 1000;
BA_ "GenMsgSendType" BO_ 896 0;
BA_ "GenMsgCycleTime" BO_ 897 200;
BA_ "GenMsgSendType" BO_ 897 0;
BA_ "GenMsgDelayTime" BO_ 905 10;
BA_ "GenMsgCycleTime" BO_ 882 200;
BA_ "GenMsgSendType" BO_ 882 0;
BA_ "GenMsgCycleTime" BO_ 881 200;
BA_ "GenMsgSendType" BO_ 881 0;
BA_ "GenMsgCycleTimeFast" BO_ 915 50;
BA_ "GenMsgNrOfRepetition" BO_ 915 2;
BA_ "GenMsgCycleTimeFast" BO_ 922 100;
BA_ "GenMsgNrOfRepetition" BO_ 922 3;
BA_ "GenMsgCycleTimeFast" BO_ 923 100;
BA_ "GenMsgNrOfRepetition" BO_ 923 3;
BA_ "GenMsgCycleTime" BO_ 925 50;
BA_ "GenMsgSendType" BO_ 925 0;
BA_ "GenMsgCycleTime" BO_ 992 150;
BA_ "GenMsgSendType" BO_ 992 0;
BA_ "GenMsgCycleTime" BO_ 993 100;
BA_ "GenMsgSendType" BO_ 993 0;
BA_ "GenMsgCycleTime" BO_ 1015 1000;
BA_ "GenMsgCycleTimeFast" BO_ 1015 50;
BA_ "GenMsgNrOfRepetition" BO_ 1015 3;
BA_ "GenMsgSendType" BO_ 1015 0;
BA_ "GenMsgCycleTime" BO_ 1020 500;
BA_ "GenMsgSendType" BO_ 1020 0;
BA_ "GenMsgCycleTimeFast" BO_ 1025 100;
BA_ "GenMsgNrOfRepetition" BO_ 1025 3;
BA_ "GenMsgCycleTime" BO_ 1026 100;
BA_ "GenMsgCycleTimeFast" BO_ 1026 100;
BA_ "GenMsgNrOfRepetition" BO_ 1026 3;
BA_ "GenMsgSendType" BO_ 1026 0;
BA_ "GenMsgCycleTime" BO_ 1027 100;
BA_ "GenMsgSendType" BO_ 1027 0;
BA_ "GenMsgCycleTimeFast" BO_ 1028 100;
BA_ "GenMsgNrOfRepetition" BO_ 1028 3;
BA_ "GenMsgCycleTimeFast" BO_ 1029 50;
BA_ "GenMsgNrOfRepetition" BO_ 1029 3;
BA_ "GenSigTimeoutTime_ALL" SG_ 676 ID2 5000;
BA_ "GenSigTimeoutTime_ALL" SG_ 676 ECU_ID_WUPREG 5000;
BA_ "InvalidValue" SG_ 676 ECU_ID_WUPREG "null";
BA_ "GenSigTimeoutTime_ALL" SG_ 676 ID_FN_INQY 5000;
BA_ "InvalidValue" SG_ 676 ID_FN_INQY "null";
BA_ "GenSigTimeoutTime_ALL" SG_ 676 ID_FN_RQ_BUS 5000;
BA_ "InvalidValue" SG_ 676 ID_FN_RQ_BUS "null";
BA_ "GenSigTimeoutTime_ALL" SG_ 676 NO_CC_MESS_EXT 5000;
BA_ "GenSigTimeoutTime_ALL" SG_ 676 NO_CC_MESS_STD 5000;
BA_ "InvalidValue" SG_ 676 NO_CC_MESS_STD "null";
BA_ "GenSigTimeoutTime_ALL" SG_ 676 WACA 5000;
BA_ "InvalidValue" SG_ 676 WACA "null";
BA_ "GenSigTimeoutTime_ALL" SG_ 676 ID_RQ_BUS 5000;
BA_ "GenSigTimeoutTime_ALL" SG_ 676 ST_CC_MESS_EXT 5000;
BA_ "GenSigTimeoutTime_ALL" SG_ 676 ST_CC_MESS_STD 5000;
BA_ "GenSigTimeoutTime_ALL" SG_ 676 TRANF_CC_MESS_EXT 5000;
BA_ "GenSigTimeoutTime_ALL" SG_ 676 TRANF_CC_MESS_STD 5000;
BA_ "GenSigTimeoutTime_ALL" SG_ 676 ST_IDC_CCLK_CC_MESS_EXT 5000;
BA_ "GenSigTimeoutTime_ALL" SG_ 676 ST_IDC_CCLK_CC_MESS_STD 5000;
BA_ "GenSigTimeoutTime_ALL" SG_ 676 NO_FRM_CC_MESS_EXT 5000;
BA_ "GenSigTimeoutTime_ALL" SG_ 676 ST_RQ_BUS 5000;
BA_ "GenSigTimeoutTime_ALL" SG_ 676 QUAN_FRM_CC_MESS_EXT 5000;
BA_ "GenSigTimeoutTime_ALL" SG_ 676 ST_LAW_RQ 5000;
BA_ "GenSigTimeoutTime_ALL" SG_ 676 DUR_FLLUPT 5000;
BA_ "GenSigTimeoutTime_ALL" SG_ 676 UTDT_CC_MESS 5000;
BA_ "GenSigTimeoutTime_ALL" SG_ 714 CHKSM_IC_SENSOR 500;
BA_ "InvalidValue" SG_ 714 CHKSM_IC_SENSOR "null";
BA_ "GenSigTimeoutTime_ALL" SG_ 714 ALV_IC_SENSOR 500;
BA_ "InvalidValue" SG_ 714 ALV_IC_SENSOR "Fh";
BA_ "GenSigStartValue" SG_ 714 MHU_STAT_AmbientTempRaw 80;
BA_ "GenSigTimeoutTime_ALL" SG_ 714 MHU_STAT_AmbientTempRaw 500;
BA_ "InvalidValue" SG_ 714 MHU_STAT_AmbientTempRaw "FFh";
BA_ "GenSigTimeoutTime_ALL" SG_ 714 MHU_STAT_FuelLevel 500;
BA_ "InvalidValue" SG_ 714 MHU_STAT_FuelLevel "FFh";
BA_ "GenSigStartValue" SG_ 714 MHU_STAT_AmbientTemp 80;
BA_ "GenSigTimeoutTime_ALL" SG_ 714 MHU_STAT_AmbientTemp 500;
BA_ "InvalidValue" SG_ 714 MHU_STAT_AmbientTemp "FFh";
BA_ "GenSigTimeoutTime_ALL" SG_ 714 MHU_STAT_CoolantLevelStatus 500;
BA_ "InvalidValue" SG_ 714 MHU_STAT_CoolantLevelStatus "3h";
BA_ "InvalidValue" SG_ 715 TEMP_EX "FFh";
BA_ "GenSigTimeoutTime_ALL" SG_ 715 TEMP_EX 500;
BA_ "InvalidValue" SG_ 715 TEMP_EX_UNFILT "FFh";
BA_ "GenSigTimeoutTime_ALL" SG_ 715 TEMP_EX_UNFILT 500;
BA_ "GenSigSendType" SG_ 717 MHU_ADASISv2_Container 1;
BA_ "GenSigTimeoutTime_ALL" SG_ 720 CHKSM_FCAM_AESA_Sts 500;
BA_ "InvalidValue" SG_ 720 ALV_FCAM_AESA_Sts "Fh";
BA_ "GenSigTimeoutTime_ALL" SG_ 720 ALV_FCAM_AESA_Sts 500;
BA_ "GenSigTimeoutTime_ALL" SG_ 720 FCAM_AESA_DoorUnlock_Req 500;
BA_ "GenSigTimeoutTime_ALL" SG_ 720 FCAM_AESA_ECALL_Req 500;
BA_ "GenSigTimeoutTime_ALL" SG_ 720 FCAM_AESA_Status 500;
BA_ "GenSigTimeoutTime_ALL" SG_ 753 MHU_STAT_AirbagWarnLamp 500;
BA_ "InvalidValue" SG_ 753 MHU_STAT_AirbagWarnLamp "3h";
BA_ "GenSigTimeoutTime_ALL" SG_ 760 DISP_HR 5000;
BA_ "InvalidValue" SG_ 760 DISP_HR "FFh";
BA_ "GenSigTimeoutTime_ALL" SG_ 760 DISP_MN 5000;
BA_ "InvalidValue" SG_ 760 DISP_MN "FFh";
BA_ "GenSigTimeoutTime_ALL" SG_ 760 DISP_SEC 5000;
BA_ "InvalidValue" SG_ 760 DISP_SEC "FFh";
BA_ "GenSigStartValue" SG_ 760 DISP_DATE_DAY 1;
BA_ "GenSigTimeoutTime_ALL" SG_ 760 DISP_DATE_DAY 5000;
BA_ "InvalidValue" SG_ 760 DISP_DATE_DAY "FFh";
BA_ "GenSigStartValue" SG_ 760 DISP_DATE_MON 1;
BA_ "GenSigTimeoutTime_ALL" SG_ 760 DISP_DATE_MON 5000;
BA_ "InvalidValue" SG_ 760 DISP_DATE_MON "Fh";
BA_ "GenSigTimeoutTime_ALL" SG_ 760 DISP_DATE_WDAY 5000;
BA_ "InvalidValue" SG_ 760 DISP_DATE_WDAY "Fh";
BA_ "GenSigStartValue" SG_ 760 DISP_DATE_YR 1;
BA_ "GenSigTimeoutTime_ALL" SG_ 760 DISP_DATE_YR 5000;
BA_ "InvalidValue" SG_ 760 DISP_DATE_YR "FFFFh";
BA_ "GenSigTimeoutTime_ALL" SG_ 760 ST_DISP_CTI_DATE 5000;
BA_ "InvalidValue" SG_ 760 ST_DISP_CTI_DATE "Fh";
BA_ "GenSigTimeoutTime_ALL" SG_ 761 DISP_HR_UTC 5000;
BA_ "InvalidValue" SG_ 761 DISP_HR_UTC "FFh";
BA_ "GenSigTimeoutTime_ALL" SG_ 761 DISP_MN_UTC 5000;
BA_ "InvalidValue" SG_ 761 DISP_MN_UTC "FFh";
BA_ "GenSigTimeoutTime_ALL" SG_ 761 DISP_SEC_UTC 5000;
BA_ "InvalidValue" SG_ 761 DISP_SEC_UTC "FFh";
BA_ "GenSigStartValue" SG_ 761 DISP_DATE_DAY_UTC 1;
BA_ "GenSigTimeoutTime_ALL" SG_ 761 DISP_DATE_DAY_UTC 5000;
BA_ "InvalidValue" SG_ 761 DISP_DATE_DAY_UTC "FFh";
BA_ "GenSigStartValue" SG_ 761 DISP_DATE_MON_UTC 1;
BA_ "GenSigTimeoutTime_ALL" SG_ 761 DISP_DATE_MON_UTC 5000;
BA_ "InvalidValue" SG_ 761 DISP_DATE_MON_UTC "Fh";
BA_ "GenSigStartValue" SG_ 761 DISP_DATE_YR_UTC 1;
BA_ "GenSigTimeoutTime_ALL" SG_ 761 DISP_DATE_YR_UTC 5000;
BA_ "InvalidValue" SG_ 761 DISP_DATE_YR_UTC "FFFFh";
BA_ "GenSigSendType" SG_ 768 CCU_STAT_SyncClimateZone 4;
BA_ "InvalidValue" SG_ 768 CCU_STAT_SyncClimateZone "3h";
BA_ "GenSigSendType" SG_ 768 CCU_STAT_Auto 4;
BA_ "InvalidValue" SG_ 768 CCU_STAT_Auto "3h";
BA_ "GenSigSendType" SG_ 768 CCU_STAT_Aircondition 4;
BA_ "InvalidValue" SG_ 768 CCU_STAT_Aircondition "3h";
BA_ "GenSigSendType" SG_ 768 CCU_STAT_IonButton 4;
BA_ "InvalidValue" SG_ 768 CCU_STAT_IonButton "3h";
BA_ "GenSigSendType" SG_ 768 CCU_STAT_MaxAc 4;
BA_ "InvalidValue" SG_ 768 CCU_STAT_MaxAc "3h";
BA_ "GenSigSendType" SG_ 768 CCU_STAT_OnOff 4;
BA_ "GenSigStartValue" SG_ 768 CCU_STAT_OnOff 3;
BA_ "InvalidValue" SG_ 768 CCU_STAT_OnOff "3h";
BA_ "GenSigSendType" SG_ 768 CCU_STAT_FanSpeed 4;
BA_ "InvalidValue" SG_ 768 CCU_STAT_FanSpeed "Fh";
BA_ "GenSigSendType" SG_ 768 CCU_STAT_RecircFlap 4;
BA_ "GenSigStartValue" SG_ 768 CCU_STAT_RecircFlap 1;
BA_ "InvalidValue" SG_ 768 CCU_STAT_RecircFlap "3h";
BA_ "GenSigSendType" SG_ 768 CCU_STAT_FlapPos 4;
BA_ "InvalidValue" SG_ 768 CCU_STAT_FlapPos "7h";
BA_ "GenSigSendType" SG_ 768 CCU_STAT_Defrost 4;
BA_ "InvalidValue" SG_ 768 CCU_STAT_Defrost "3h";
BA_ "GenSigSendType" SG_ 768 CCU_STAT_PTC_Heater 4;
BA_ "InvalidValue" SG_ 768 CCU_STAT_PTC_Heater "7h";
BA_ "GenSigSendType" SG_ 768 CCU_STAT_TempDriver 4;
BA_ "GenSigStartValue" SG_ 768 CCU_STAT_TempDriver 40;
BA_ "InvalidValue" SG_ 768 CCU_STAT_TempDriver "FFh";
BA_ "GenSigSendType" SG_ 768 CCU_STAT_TempPassenger 4;
BA_ "GenSigStartValue" SG_ 768 CCU_STAT_TempPassenger 40;
BA_ "InvalidValue" SG_ 768 CCU_STAT_TempPassenger "FFh";
BA_ "GenSigTimeoutTime_ALL" SG_ 769 Checksum_RP 500;
BA_ "GenSigTimeoutTime_ALL" SG_ 769 Rolling_Counter_RP 500;
BA_ "InvalidValue" SG_ 769 Rolling_Counter_RP "Fh";
BA_ "GenSigTimeoutTime_ALL" SG_ 769 RP_ReqInfoDispTxt2 500;
BA_ "GenSigTimeoutTime_ALL" SG_ 769 RP_Status 500;
BA_ "GenSigTimeoutTime_ALL" SG_ 769 ADAS_TboxAuthStatus 500;
BA_ "InvalidValue" SG_ 769 ADAS_TboxAuthStatus "3h";
BA_ "GenSigTimeoutTime_ALL" SG_ 769 RP_ReqInfoDispTxt1 500;
BA_ "GenSigTimeoutTime_ALL" SG_ 770 CHKSM_CCU_TEMP_PRESSURE 5000;
BA_ "InvalidValue" SG_ 770 CHKSM_CCU_TEMP_PRESSURE "null";
BA_ "GenSigTimeoutTime_ALL" SG_ 770 ALV_CCU_TEMP_PRESSURE 5000;
BA_ "InvalidValue" SG_ 770 ALV_CCU_TEMP_PRESSURE "Fh";
BA_ "GenSigTimeoutTime_ALL" SG_ 770 CCU_Pressure_AC 5000;
BA_ "InvalidValue" SG_ 770 CCU_Pressure_AC "3Fh";
BA_ "GenSigStartValue" SG_ 770 CCU_InteriorTemp 80;
BA_ "GenSigTimeoutTime_ALL" SG_ 770 CCU_InteriorTemp 5000;
BA_ "InvalidValue" SG_ 770 CCU_InteriorTemp "FFh";
BA_ "GenSigStartValue" SG_ 770 CCU_TempEx_AC 80;
BA_ "GenSigTimeoutTime_ALL" SG_ 770 CCU_TempEx_AC 5000;
BA_ "InvalidValue" SG_ 770 CCU_TempEx_AC "FFh";
BA_ "GenSigStartValue" SG_ 770 CCU_EvaporatorTemp 80;
BA_ "GenSigTimeoutTime_ALL" SG_ 770 CCU_EvaporatorTemp 5000;
BA_ "InvalidValue" SG_ 770 CCU_EvaporatorTemp "FFh";
BA_ "GenSigTimeoutTime_ALL" SG_ 773 CHSKM_BMS_Insulation 50000;
BA_ "InvalidValue" SG_ 773 CHSKM_BMS_Insulation "null";
BA_ "GenSigTimeoutTime_ALL" SG_ 773 ALV_BMS_Insulation 50000;
BA_ "InvalidValue" SG_ 773 ALV_BMS_Insulation "Fh";
BA_ "GenSigTimeoutTime_ALL" SG_ 773 BMS_VCU_Insulation_Mon_Sts 50000;
BA_ "InvalidValue" SG_ 773 BMS_VCU_Insulation_Mon_Sts "null";
BA_ "GenSigStartValue" SG_ 773 BMS_PackInsuRes 5535;
BA_ "GenSigTimeoutTime_ALL" SG_ 773 BMS_PackInsuRes 50000;
BA_ "InvalidValue" SG_ 773 BMS_PackInsuRes "null";
BA_ "GenSigTimeoutTime_ALL" SG_ 775 CHKSM_CPD_Output_1 5000;
BA_ "InvalidValue" SG_ 775 CHKSM_CPD_Output_1 "null";
BA_ "GenSigTimeoutTime_ALL" SG_ 775 ALV_CPD_Output_1 5000;
BA_ "InvalidValue" SG_ 775 ALV_CPD_Output_1 "Fh";
BA_ "GenSigTimeoutTime_ALL" SG_ 775 OUT_Alert_TO_BCM 5000;
BA_ "InvalidValue" SG_ 775 OUT_Alert_TO_BCM "7h";
BA_ "GenSigTimeoutTime_ALL" SG_ 775 CPD_State_information 5000;
BA_ "InvalidValue" SG_ 775 CPD_State_information "null";
BA_ "GenSigTimeoutTime_ALL" SG_ 775 OUT_Alert_TO_MHU 5000;
BA_ "GenSigSendType" SG_ 776 MHU_CPD_Setting 2;
BA_ "GenSigSendType" SG_ 776 MHU_CPD_Confirmation_On_HMI 2;
BA_ "GenSigSendType" SG_ 784 CCUR_STAT_IonButton 4;
BA_ "InvalidValue" SG_ 784 CCUR_STAT_IonButton "3h";
BA_ "GenSigSendType" SG_ 784 CCUR_STAT_Defrost 4;
BA_ "InvalidValue" SG_ 784 CCUR_STAT_Defrost "3h";
BA_ "GenSigSendType" SG_ 784 CCUR_STAT_Auto 4;
BA_ "InvalidValue" SG_ 784 CCUR_STAT_Auto "3h";
BA_ "GenSigSendType" SG_ 784 CCUR_STAT_Aircondition 4;
BA_ "InvalidValue" SG_ 784 CCUR_STAT_Aircondition "3h";
BA_ "GenSigSendType" SG_ 784 CCUR_STAT_FlapPos 4;
BA_ "InvalidValue" SG_ 784 CCUR_STAT_FlapPos "7h";
BA_ "GenSigSendType" SG_ 784 CCUR_STAT_FanSpeed 4;
BA_ "InvalidValue" SG_ 784 CCUR_STAT_FanSpeed "Fh";
BA_ "GenSigSendType" SG_ 784 CCUR_STAT_PTC_Heater 4;
BA_ "InvalidValue" SG_ 784 CCUR_STAT_PTC_Heater "7h";
BA_ "GenSigSendType" SG_ 784 CCUR_STAT_OnOff 4;
BA_ "GenSigStartValue" SG_ 784 CCUR_STAT_OnOff 3;
BA_ "InvalidValue" SG_ 784 CCUR_STAT_OnOff "3h";
BA_ "GenSigSendType" SG_ 784 CCUR_STAT_MaxAc 4;
BA_ "InvalidValue" SG_ 784 CCUR_STAT_MaxAc "3h";
BA_ "GenSigSendType" SG_ 784 CCUR_STAT_SyncClimateZone 4;
BA_ "InvalidValue" SG_ 784 CCUR_STAT_SyncClimateZone "3h";
BA_ "GenSigSendType" SG_ 784 CCUR_STAT_RecircFlap 4;
BA_ "GenSigStartValue" SG_ 784 CCUR_STAT_RecircFlap 1;
BA_ "InvalidValue" SG_ 784 CCUR_STAT_RecircFlap "3h";
BA_ "GenSigSendType" SG_ 784 CCUR_STAT_TempRear 4;
BA_ "GenSigStartValue" SG_ 784 CCUR_STAT_TempRear 40;
BA_ "InvalidValue" SG_ 784 CCUR_STAT_TempRear "null";
BA_ "GenSigTimeoutTime_ALL" SG_ 771 Checksum_MHU_PAS_FEEDBACK 500;
BA_ "GenSigTimeoutTime_ALL" SG_ 771 Rolling_Counter_MHU_PAS_FEEDBACK 500;
BA_ "InvalidValue" SG_ 771 Rolling_Counter_MHU_PAS_FEEDBACK "Fh";
BA_ "GenSigTimeoutTime_ALL" SG_ 771 MHU_AVM_CurbViewReq 500;
BA_ "InvalidValue" SG_ 771 MHU_AVM_CurbViewReq "3h";
BA_ "GenSigTimeoutTime_ALL" SG_ 771 HU_SVS_TransparentModel_Req 500;
BA_ "InvalidValue" SG_ 771 HU_SVS_TransparentModel_Req "3h";
BA_ "GenSigTimeoutTime_ALL" SG_ 771 HU_SVSObjOverlay 500;
BA_ "InvalidValue" SG_ 771 HU_SVSObjOverlay "3h";
BA_ "GenSigTimeoutTime_ALL" SG_ 771 MHU_AVM_DynamiclineReq 500;
BA_ "InvalidValue" SG_ 771 MHU_AVM_DynamiclineReq "3h";
BA_ "GenSigTimeoutTime_ALL" SG_ 771 HU_3D_SVS_ReqFromHU 500;
BA_ "InvalidValue" SG_ 771 HU_3D_SVS_ReqFromHU "3h";
BA_ "GenSigTimeoutTime_ALL" SG_ 771 MHU_AVM_ShowAPAReq 500;
BA_ "GenSigTimeoutTime_ALL" SG_ 771 MHU_AVM_BmprViewReq 500;
BA_ "InvalidValue" SG_ 771 MHU_AVM_BmprViewReq "3h";
BA_ "GenSigTimeoutTime_ALL" SG_ 771 HU_SVSManVidSetupReqFromHU 500;
BA_ "GenSigTimeoutTime_ALL" SG_ 771 HU_3D_SVS_ViewChgReqFromHU 500;
BA_ "InvalidValue" SG_ 771 HU_3D_SVS_ViewChgReqFromHU "Fh";
BA_ "GenSigTimeoutTime_ALL" SG_ 771 SECCAN_MHU_PAS_FEEDBACK 500;
BA_ "GenSigTimeoutTime_ALL" SG_ 787 CHSKM_POD_StatusCharger1 500;
BA_ "InvalidValue" SG_ 787 CHSKM_POD_StatusCharger1 "null";
BA_ "GenSigTimeoutTime_ALL" SG_ 787 ALV_POD_StatusCharger1 500;
BA_ "InvalidValue" SG_ 787 ALV_POD_StatusCharger1 "Fh";
BA_ "GenSigTimeoutTime_ALL" SG_ 787 POD_statusOBC 500;
BA_ "InvalidValue" SG_ 787 POD_statusOBC "null";
BA_ "GenSigTimeoutTime_ALL" SG_ 787 POD_OBC_Max_Current_Out 500;
BA_ "InvalidValue" SG_ 787 POD_OBC_Max_Current_Out "null";
BA_ "GenSigTimeoutTime_ALL" SG_ 787 POD_iDCOut 500;
BA_ "InvalidValue" SG_ 787 POD_iDCOut "FFh";
BA_ "GenSigTimeoutTime_ALL" SG_ 787 POD_vDCOut 500;
BA_ "InvalidValue" SG_ 787 POD_vDCOut "FFFFh";
BA_ "GenSigTimeoutTime_ALL" SG_ 803 CHSKM_POD_StatusCharger2 500;
BA_ "InvalidValue" SG_ 803 CHSKM_POD_StatusCharger2 "null";
BA_ "GenSigTimeoutTime_ALL" SG_ 803 ALV_POD_StatusCharger2 500;
BA_ "InvalidValue" SG_ 803 ALV_POD_StatusCharger2 "Fh";
BA_ "GenSigStartValue" SG_ 803 POD_phaseACInput 1;
BA_ "GenSigTimeoutTime_ALL" SG_ 803 POD_phaseACInput 500;
BA_ "InvalidValue" SG_ 803 POD_phaseACInput "0";
BA_ "GenSigTimeoutTime_ALL" SG_ 803 POD_iACInput 500;
BA_ "InvalidValue" SG_ 803 POD_iACInput "null";
BA_ "GenSigTimeoutTime_ALL" SG_ 803 POD_vACInput 500;
BA_ "InvalidValue" SG_ 803 POD_vACInput "null";
BA_ "GenSigTimeoutTime_ALL" SG_ 804 Steering_HeatingControl 500;
BA_ "InvalidValue" SG_ 804 Steering_HeatingControl "3h";
BA_ "GenSigTimeoutTime_ALL" SG_ 805 Steering_HeatingControlFdbk 500;
BA_ "InvalidValue" SG_ 805 Steering_HeatingControlFdbk "3h";
BA_ "GenSigTimeoutTime_ALL" SG_ 806 CHSKM_POD_StatusDCDC1 500;
BA_ "InvalidValue" SG_ 806 CHSKM_POD_StatusDCDC1 "null";
BA_ "GenSigSendType" SG_ 806 ALV_POD_StatusDCDC1 3;
BA_ "GenSigTimeoutTime_ALL" SG_ 806 ALV_POD_StatusDCDC1 500;
BA_ "InvalidValue" SG_ 806 ALV_POD_StatusDCDC1 "Fh";
BA_ "GenSigTimeoutTime_ALL" SG_ 806 POD_statusDCDC 500;
BA_ "InvalidValue" SG_ 806 POD_statusDCDC "7h";
BA_ "GenSigTimeoutTime_ALL" SG_ 806 POD_DCDC_Max_Current_Out 500;
BA_ "InvalidValue" SG_ 806 POD_DCDC_Max_Current_Out "FFh";
BA_ "GenSigTimeoutTime_ALL" SG_ 807 CHKSM_POD_StatusFC 500;
BA_ "InvalidValue" SG_ 807 CHKSM_POD_StatusFC "";
BA_ "GenSigTimeoutTime_ALL" SG_ 807 ALV_POD_StatusFC 500;
BA_ "InvalidValue" SG_ 807 ALV_POD_StatusFC "Fh";
BA_ "GenSigTimeoutTime_ALL" SG_ 807 POD_vFC 500;
BA_ "InvalidValue" SG_ 807 POD_vFC "FFFFh";
BA_ "GenSigTimeoutTime_ALL" SG_ 807 POD_statusFCContactors 500;
BA_ "InvalidValue" SG_ 807 POD_statusFCContactors "7h";
BA_ "GenSigTimeoutTime_ALL" SG_ 808 T_SEC_COU_REL 5000;
BA_ "InvalidValue" SG_ 808 T_SEC_COU_REL "FFFFFFFFh";
BA_ "GenSigTimeoutTime_ALL" SG_ 808 T_DAY_COU_ABSL 5000;
BA_ "InvalidValue" SG_ 808 T_DAY_COU_ABSL "FFFFh";
BA_ "GenSigTimeoutTime_ALL" SG_ 809 CRC_BCM_ODO 5000;
BA_ "InvalidValue" SG_ 809 CRC_BCM_ODO "null";
BA_ "GenSigTimeoutTime_ALL" SG_ 809 ALIV_BCM_ODO 5000;
BA_ "InvalidValue" SG_ 809 ALIV_BCM_ODO "Fh";
BA_ "GenSigTimeoutTime_ALL" SG_ 809 Odometer_BCM 5000;
BA_ "InvalidValue" SG_ 809 Odometer_BCM "FFFFFh";
BA_ "GenSigTimeoutTime_ALL" SG_ 809 SECCAN_BCM_ODO 5000;
BA_ "GenSigTimeoutTime_ALL" SG_ 809 SECCAN_BCM_ODO 5000;
BA_ "InvalidValue" SG_ 809 SECCAN_BCM_ODO "null";
BA_ "GenSigTimeoutTime_ALL" SG_ 816 MILE_KM 500;
BA_ "InvalidValue" SG_ 816 MILE_KM "FFFFFFh";
BA_ "GenSigTimeoutTime_ALL" SG_ 816 FLLV_FUTA 500;
BA_ "InvalidValue" SG_ 816 FLLV_FUTA "FFh";
BA_ "GenSigTimeoutTime_ALL" SG_ 816 RNG 500;
BA_ "InvalidValue" SG_ 816 RNG "FFFh";
BA_ "GenSigTimeoutTime_ALL" SG_ 816 ST_FLLV_FUTA_SPAR 500;
BA_ "InvalidValue" SG_ 816 ST_FLLV_FUTA_SPAR "3h";
BA_ "GenSigTimeoutTime_ALL" SG_ 818 Checksum_0x332 500;
BA_ "InvalidValue" SG_ 818 Checksum_0x332 "null";
BA_ "GenSigTimeoutTime_ALL" SG_ 818 Rolling_Counter_0x332 500;
BA_ "InvalidValue" SG_ 818 Rolling_Counter_0x332 "Fh";
BA_ "GenSigTimeoutTime_ALL" SG_ 818 BMS_PackCNom 500;
BA_ "InvalidValue" SG_ 818 BMS_PackCNom "FFFFh";
BA_ "GenSigStartValue" SG_ 818 BMS_PackTemp_0x332 80;
BA_ "GenSigTimeoutTime_ALL" SG_ 818 BMS_PackTemp_0x332 500;
BA_ "InvalidValue" SG_ 818 BMS_PackTemp_0x332 "FFh";
BA_ "InvalidValue" SG_ 819 Checksum_0x333 "0";
BA_ "InvalidValue" SG_ 819 Rolling_Counter_0x333 "Fh";
BA_ "InvalidValue" SG_ 819 ADAS_RadarRight_Cal_Status "0";
BA_ "InvalidValue" SG_ 819 ADAS_RadarLeft_Cal_Status "0";
BA_ "InvalidValue" SG_ 819 ADAS_RadarRight_DynaCal_Status "0";
BA_ "InvalidValue" SG_ 819 ADAS_MasterSRR_check "0";
BA_ "InvalidValue" SG_ 819 ADAS_SlaveSRR_check "0";
BA_ "InvalidValue" SG_ 819 ADAS_RadarLeft_DynaCal_Status "0";
BA_ "InvalidValue" SG_ 819 ADAS_CalSensorMasterProgress "FFh";
BA_ "InvalidValue" SG_ 819 ADAS_CalSensorSlaverProgress "FFh";
BA_ "InvalidValue" SG_ 819 ADAS_Cal_LeftInstallDeviation "0";
BA_ "InvalidValue" SG_ 819 ADAS_Cal_RightInstallDeviation "0";
BA_ "GenSigTimeoutTime_ALL" SG_ 827 CHKSM_CameraLane 500;
BA_ "GenSigTimeoutTime_ALL" SG_ 827 ALV_ADAS_Cameralane 500;
BA_ "InvalidValue" SG_ 827 ALV_ADAS_Cameralane "Fh";
BA_ "GenSigTimeoutTime_ALL" SG_ 827 Camera_R1_Line_Type 500;
BA_ "GenSigTimeoutTime_ALL" SG_ 827 Camera_L1_Line_Type 500;
BA_ "GenSigTimeoutTime_ALL" SG_ 827 R0_ExistProbability 500;
BA_ "InvalidValue" SG_ 827 R0_ExistProbability "Fh";
BA_ "GenSigTimeoutTime_ALL" SG_ 827 L0_ExistProbability 500;
BA_ "InvalidValue" SG_ 827 L0_ExistProbability "Fh";
BA_ "GenSigTimeoutTime_ALL" SG_ 827 L1_ExistProbability 500;
BA_ "InvalidValue" SG_ 827 L1_ExistProbability "Fh";
BA_ "GenSigTimeoutTime_ALL" SG_ 827 R1_ExistProbability 500;
BA_ "InvalidValue" SG_ 827 R1_ExistProbability "Fh";
BA_ "GenSigTimeoutTime_ALL" SG_ 827 SECCAN_CameraLane 500;
BA_ "GenSigTimeoutTime_ALL" SG_ 833 SECCAN_Cam_OBJ_1 500;
BA_ "GenSigTimeoutTime_ALL" SG_ 833 ADAS_OBJ01_Class 500;
BA_ "InvalidValue" SG_ 833 ADAS_OBJ01_Class "7";
BA_ "GenSigStartValue" SG_ 833 ADAS_OBJ01_LgtDis 400;
BA_ "GenSigTimeoutTime_ALL" SG_ 833 ADAS_OBJ01_LgtDis 500;
BA_ "InvalidValue" SG_ 833 ADAS_OBJ01_LgtDis "3FFF";
BA_ "GenSigTimeoutTime_ALL" SG_ 833 ADAS_OBJ01_ID 500;
BA_ "InvalidValue" SG_ 833 ADAS_OBJ01_ID "FF";
BA_ "GenSigTimeoutTime_ALL" SG_ 833 ADAS_OBJ01_LatDis 500;
BA_ "GenSigTimeoutTime_ALL" SG_ 833 ADAS_OBJ01_Lane 500;
BA_ "InvalidValue" SG_ 833 ADAS_OBJ01_Lane "7";
BA_ "GenSigTimeoutTime_ALL" SG_ 835 SECCAN_Cam_OBJ_2 500;
BA_ "GenSigTimeoutTime_ALL" SG_ 835 ADAS_OBJ02_Class 500;
BA_ "InvalidValue" SG_ 835 ADAS_OBJ02_Class "7";
BA_ "GenSigStartValue" SG_ 835 ADAS_OBJ02_LgtDis 400;
BA_ "GenSigTimeoutTime_ALL" SG_ 835 ADAS_OBJ02_LgtDis 500;
BA_ "InvalidValue" SG_ 835 ADAS_OBJ02_LgtDis "3FF";
BA_ "GenSigTimeoutTime_ALL" SG_ 835 ADAS_OBJ02_ID 500;
BA_ "InvalidValue" SG_ 835 ADAS_OBJ02_ID "FF";
BA_ "GenSigTimeoutTime_ALL" SG_ 835 ADAS_OBJ02_LatDis 500;
BA_ "InvalidValue" SG_ 835 ADAS_OBJ02_LatDis "3FF";
BA_ "GenSigTimeoutTime_ALL" SG_ 835 ADAS_OBJ02_Lane 500;
BA_ "InvalidValue" SG_ 835 ADAS_OBJ02_Lane "7";
BA_ "GenSigTimeoutTime_ALL" SG_ 838 CHSKM_POD_StatusDCDC2 500;
BA_ "InvalidValue" SG_ 838 CHSKM_POD_StatusDCDC2 "null";
BA_ "GenSigTimeoutTime_ALL" SG_ 838 ALV_POD_StatusDCDC2 500;
BA_ "InvalidValue" SG_ 838 ALV_POD_StatusDCDC2 "Fh";
BA_ "GenSigTimeoutTime_ALL" SG_ 838 POD_vDCInput 500;
BA_ "InvalidValue" SG_ 838 POD_vDCInput "FFFFh";
BA_ "GenSigTimeoutTime_ALL" SG_ 838 POD_iDCDCOutput 500;
BA_ "InvalidValue" SG_ 838 POD_iDCDCOutput "FFFFh";
BA_ "GenSigTimeoutTime_ALL" SG_ 838 POD_vDCDCOutput 500;
BA_ "InvalidValue" SG_ 838 POD_vDCDCOutput "FFFFh";
BA_ "GenSigTimeoutTime_ALL" SG_ 840 EDS_HVIL_STS_FWD 5000;
BA_ "InvalidValue" SG_ 840 EDS_HVIL_STS_FWD "";
BA_ "GenSigTimeoutTime_ALL" SG_ 841 EDS_HVIL_STS_RWD 5000;
BA_ "InvalidValue" SG_ 841 EDS_HVIL_STS_RWD "";
BA_ "GenSigTimeoutTime_ALL" SG_ 842 SECCAN_Cam_OBJ_3 500;
BA_ "GenSigTimeoutTime_ALL" SG_ 842 ADAS_OBJ03_Class 500;
BA_ "InvalidValue" SG_ 842 ADAS_OBJ03_Class "7";
BA_ "GenSigStartValue" SG_ 842 ADAS_OBJ03_LgtDis 400;
BA_ "GenSigTimeoutTime_ALL" SG_ 842 ADAS_OBJ03_LgtDis 500;
BA_ "InvalidValue" SG_ 842 ADAS_OBJ03_LgtDis "3FF";
BA_ "GenSigTimeoutTime_ALL" SG_ 842 ADAS_OBJ03_ID 500;
BA_ "InvalidValue" SG_ 842 ADAS_OBJ03_ID "FF";
BA_ "GenSigTimeoutTime_ALL" SG_ 842 ADAS_OBJ03_LatDis 500;
BA_ "InvalidValue" SG_ 842 ADAS_OBJ03_LatDis "3FF";
BA_ "GenSigTimeoutTime_ALL" SG_ 842 ADAS_OBJ03_Lane 500;
BA_ "InvalidValue" SG_ 842 ADAS_OBJ03_Lane "7";
BA_ "GenSigTimeoutTime_ALL" SG_ 844 SECCAN_Cam_OBJ_4 500;
BA_ "GenSigTimeoutTime_ALL" SG_ 844 ADAS_OBJ04_Class 500;
BA_ "InvalidValue" SG_ 844 ADAS_OBJ04_Class "7";
BA_ "GenSigStartValue" SG_ 844 ADAS_OBJ04_LgtDis 400;
BA_ "GenSigTimeoutTime_ALL" SG_ 844 ADAS_OBJ04_LgtDis 500;
BA_ "InvalidValue" SG_ 844 ADAS_OBJ04_LgtDis "3FFF";
BA_ "GenSigTimeoutTime_ALL" SG_ 844 ADAS_OBJ04_ID 500;
BA_ "InvalidValue" SG_ 844 ADAS_OBJ04_ID "FF";
BA_ "GenSigTimeoutTime_ALL" SG_ 844 ADAS_OBJ04_LatDis 500;
BA_ "GenSigTimeoutTime_ALL" SG_ 844 ADAS_OBJ04_Lane 500;
BA_ "InvalidValue" SG_ 844 ADAS_OBJ04_Lane "7";
BA_ "GenSigTimeoutTime_ALL" SG_ 845 SECCAN_Cam_OBJ_5 500;
BA_ "GenSigTimeoutTime_ALL" SG_ 845 ADAS_OBJ05_Class 500;
BA_ "InvalidValue" SG_ 845 ADAS_OBJ05_Class "7";
BA_ "GenSigStartValue" SG_ 845 ADAS_OBJ05_LgtDis 400;
BA_ "GenSigTimeoutTime_ALL" SG_ 845 ADAS_OBJ05_LgtDis 500;
BA_ "InvalidValue" SG_ 845 ADAS_OBJ05_LgtDis "3FFF";
BA_ "GenSigTimeoutTime_ALL" SG_ 845 ADAS_OBJ05_ID 500;
BA_ "InvalidValue" SG_ 845 ADAS_OBJ05_ID "FF";
BA_ "GenSigTimeoutTime_ALL" SG_ 845 ADAS_OBJ05_LatDis 500;
BA_ "GenSigTimeoutTime_ALL" SG_ 845 ADAS_OBJ05_Lane 500;
BA_ "InvalidValue" SG_ 845 ADAS_OBJ05_Lane "7";
BA_ "GenSigTimeoutTime_ALL" SG_ 846 SECCAN_Cam_OBJ_6 500;
BA_ "GenSigTimeoutTime_ALL" SG_ 846 ADAS_OBJ06_Class 500;
BA_ "InvalidValue" SG_ 846 ADAS_OBJ06_Class "7";
BA_ "GenSigStartValue" SG_ 846 ADAS_OBJ06_LgtDis 400;
BA_ "GenSigTimeoutTime_ALL" SG_ 846 ADAS_OBJ06_LgtDis 500;
BA_ "InvalidValue" SG_ 846 ADAS_OBJ06_LgtDis "3FFF";
BA_ "GenSigTimeoutTime_ALL" SG_ 846 ADAS_OBJ06_ID 500;
BA_ "InvalidValue" SG_ 846 ADAS_OBJ06_ID "FF";
BA_ "GenSigTimeoutTime_ALL" SG_ 846 ADAS_OBJ06_LatDis 500;
BA_ "GenSigTimeoutTime_ALL" SG_ 846 ADAS_OBJ06_Lane 500;
BA_ "InvalidValue" SG_ 846 ADAS_OBJ06_Lane "7";
BA_ "GenSigTimeoutTime_ALL" SG_ 849 CHKSM_ADAS_PA 500;
BA_ "GenSigTimeoutTime_ALL" SG_ 849 ALV_ADAS_PA 500;
BA_ "InvalidValue" SG_ 849 ALV_ADAS_PA "Fh";
BA_ "GenSigStartValue" SG_ 849 ADAS_PA_AutoOn_Feed 1;
BA_ "GenSigTimeoutTime_ALL" SG_ 849 ADAS_PA_AutoOn_Feed 500;
BA_ "GenSigTimeoutTime_ALL" SG_ 849 ADAS_PA_AlertFRI 500;
BA_ "GenSigTimeoutTime_ALL" SG_ 849 ADAS_PA_AlertFLI 500;
BA_ "GenSigTimeoutTime_ALL" SG_ 849 ADAS_PA_AlertFLO 500;
BA_ "GenSigTimeoutTime_ALL" SG_ 849 ADAS_PA_AlertRLO 500;
BA_ "GenSigTimeoutTime_ALL" SG_ 849 ADAS_PA_AlertRLI 500;
BA_ "GenSigTimeoutTime_ALL" SG_ 849 ADAS_PA_AlertFRO 500;
BA_ "GenSigTimeoutTime_ALL" SG_ 849 ADAS_PA_AlertRRO 500;
BA_ "GenSigTimeoutTime_ALL" SG_ 849 ADAS_PA_AlertRRI 500;
BA_ "GenSigTimeoutTime_ALL" SG_ 849 ADAS_PA_state 500;
BA_ "GenSigTimeoutTime_ALL" SG_ 849 ADAS_PA_AlertFLS 500;
BA_ "GenSigTimeoutTime_ALL" SG_ 849 ADAS_PA_AlertFRS 500;
BA_ "GenSigTimeoutTime_ALL" SG_ 849 ADAS_PA_AlertRLS 500;
BA_ "GenSigTimeoutTime_ALL" SG_ 849 ADAS_PA_AlertRRS 500;
BA_ "GenSigTimeoutTime_ALL" SG_ 850 CHKSM_ADAS_AHB_DOW 500;
BA_ "GenSigTimeoutTime_ALL" SG_ 850 ALV_ADAS_AHB_DOW 500;
BA_ "InvalidValue" SG_ 850 ALV_ADAS_AHB_DOW "Fh";
BA_ "GenSigTimeoutTime_ALL" SG_ 850 ADAS_AHB_sens_Feed 500;
BA_ "InvalidValue" SG_ 850 ADAS_AHB_sens_Feed "3h";
BA_ "GenSigTimeoutTime_ALL" SG_ 850 ADAS_AHB_Mode_Feed 500;
BA_ "GenSigTimeoutTime_ALL" SG_ 850 ADAS_AHB_check 500;
BA_ "InvalidValue" SG_ 850 ADAS_AHB_check "3h";
BA_ "GenSigTimeoutTime_ALL" SG_ 850 ADAS_AHB_state 500;
BA_ "InvalidValue" SG_ 850 ADAS_AHB_state "3h";
BA_ "GenSigTimeoutTime_ALL" SG_ 850 ADAS_DOW_WarnRight 500;
BA_ "InvalidValue" SG_ 850 ADAS_DOW_WarnRight "3h";
BA_ "GenSigTimeoutTime_ALL" SG_ 850 ADAS_DOW_SndWarn 500;
BA_ "InvalidValue" SG_ 850 ADAS_DOW_SndWarn "3h";
BA_ "GenSigTimeoutTime_ALL" SG_ 850 ADAS_DOW_state 500;
BA_ "InvalidValue" SG_ 850 ADAS_DOW_state "3h";
BA_ "GenSigTimeoutTime_ALL" SG_ 850 ADAS_DOW_check 500;
BA_ "InvalidValue" SG_ 850 ADAS_DOW_check "3h";
BA_ "GenSigTimeoutTime_ALL" SG_ 850 ADAS_DOW_WarnLeft 500;
BA_ "InvalidValue" SG_ 850 ADAS_DOW_WarnLeft "3h";
BA_ "GenSigStartValue" SG_ 850 ADAS_DOW_Mode_Feed 2;
BA_ "GenSigTimeoutTime_ALL" SG_ 850 ADAS_DOW_Mode_Feed 500;
BA_ "InvalidValue" SG_ 850 ADAS_DOW_Mode_Feed "3h";
BA_ "GenSigTimeoutTime_ALL" SG_ 850 ADAS_AHB_RBPos 500;
BA_ "InvalidValue" SG_ 850 ADAS_AHB_RBPos "7h";
BA_ "GenSigTimeoutTime_ALL" SG_ 850 ADAS_AHB_LBPos 500;
BA_ "InvalidValue" SG_ 850 ADAS_AHB_LBPos "7h";
BA_ "GenSigTimeoutTime_ALL" SG_ 851 CHKSM_ADAS_ACC 500;
BA_ "GenSigTimeoutTime_ALL" SG_ 851 ALV_ADAS_ACC 500;
BA_ "InvalidValue" SG_ 851 ALV_ADAS_ACC "Fh";
BA_ "GenSigTimeoutTime_ALL" SG_ 851 ADAS_ACC_ObjDetec 500;
BA_ "GenSigTimeoutTime_ALL" SG_ 851 ADAS_ISA_check 500;
BA_ "InvalidValue" SG_ 851 ADAS_ISA_check "3h";
BA_ "GenSigTimeoutTime_ALL" SG_ 851 ADAS_ISA_Mode_SW_Feed 500;
BA_ "GenSigTimeoutTime_ALL" SG_ 851 ADAS_TagSpeed_ICON_Feed 500;
BA_ "InvalidValue" SG_ 851 ADAS_TagSpeed_ICON_Feed "7h";
BA_ "GenSigTimeoutTime_ALL" SG_ 851 ADAS_ISA_PopUp_Feed 500;
BA_ "InvalidValue" SG_ 851 ADAS_ISA_PopUp_Feed "Fh";
BA_ "GenSigTimeoutTime_ALL" SG_ 851 ADAS_ISA_Btn_Feed 500;
BA_ "GenSigTimeoutTime_ALL" SG_ 851 ADAS_ACC_DistSet_upper_Feed 500;
BA_ "GenSigTimeoutTime_ALL" SG_ 851 ADAS_ACC_TimeGapSet 500;
BA_ "InvalidValue" SG_ 851 ADAS_ACC_TimeGapSet "7h";
BA_ "GenSigTimeoutTime_ALL" SG_ 851 ADAS_ACC_State 500;
BA_ "GenSigTimeoutTime_ALL" SG_ 851 ADAS_ACC_TagSpeed 500;
BA_ "InvalidValue" SG_ 851 ADAS_ACC_TagSpeed "FFh";
BA_ "GenSigTimeoutTime_ALL" SG_ 851 ADAS_ACC_PopUp_Feed 500;
BA_ "InvalidValue" SG_ 851 ADAS_ACC_PopUp_Feed "Fh";
BA_ "GenSigTimeoutTime_ALL" SG_ 851 ADAS_ACC_check 500;
BA_ "InvalidValue" SG_ 851 ADAS_ACC_check "3h";
BA_ "GenSigTimeoutTime_ALL" SG_ 851 ADAS_ISA_ICON_Feed 500;
BA_ "GenSigTimeoutTime_ALL" SG_ 851 ADAS_ACC_DistSet_lower_Feed 500;
BA_ "GenSigTimeoutTime_ALL" SG_ 851 ADAS_ACC_SpdSet_upper_Feed 500;
BA_ "GenSigTimeoutTime_ALL" SG_ 851 ADAS_ACC_SpdSet_lower_Feed 500;
BA_ "GenSigTimeoutTime_ALL" SG_ 851 ADAS_ACC_On_Feed 500;
BA_ "GenSigTimeoutTime_ALL" SG_ 851 ADAS_ACC_Set_Feed 500;
BA_ "GenSigTimeoutTime_ALL" SG_ 851 ADAS_ACC_CnlBtn_Feed 500;
BA_ "GenSigTimeoutTime_ALL" SG_ 851 ADAS_ACC_Res_Feed 500;
BA_ "GenSigTimeoutTime_ALL" SG_ 851 ADAS_ACC_ICON_Feed 500;
BA_ "InvalidValue" SG_ 851 ADAS_ACC_ICON_Feed "7h";
BA_ "GenSigTimeoutTime_ALL" SG_ 851 ADAS_ISA_Status 500;
BA_ "InvalidValue" SG_ 851 ADAS_ISA_Status "7h";
BA_ "GenSigTimeoutTime_ALL" SG_ 852 CHKSM_MHU_ADAS_req 500;
BA_ "InvalidValue" SG_ 852 ALV_MHU_ADAS_req "Fh";
BA_ "GenSigTimeoutTime_ALL" SG_ 852 ALV_MHU_ADAS_req 500;
BA_ "GenSigStartValue" SG_ 852 MHU_FCW_Mode 1;
BA_ "GenSigTimeoutTime_ALL" SG_ 852 MHU_FCW_Mode 500;
BA_ "InvalidValue" SG_ 852 MHU_FCW_Mode "3h";
BA_ "GenSigStartValue" SG_ 852 MHU_FCW_sens 1;
BA_ "GenSigTimeoutTime_ALL" SG_ 852 MHU_FCW_sens 500;
BA_ "InvalidValue" SG_ 852 MHU_FCW_sens "3h";
BA_ "GenSigStartValue" SG_ 852 MHU_AEB_Mode 1;
BA_ "GenSigTimeoutTime_ALL" SG_ 852 MHU_AEB_Mode 500;
BA_ "InvalidValue" SG_ 852 MHU_AEB_Mode "3h";
BA_ "GenSigStartValue" SG_ 852 MHU_RAEB_Mode 1;
BA_ "GenSigTimeoutTime_ALL" SG_ 852 MHU_RAEB_Mode 500;
BA_ "InvalidValue" SG_ 852 MHU_RAEB_Mode "3h";
BA_ "GenSigStartValue" SG_ 852 MHU_LA_sens 1;
BA_ "GenSigTimeoutTime_ALL" SG_ 852 MHU_LA_sens 500;
BA_ "InvalidValue" SG_ 852 MHU_LA_sens "3h";
BA_ "GenSigTimeoutTime_ALL" SG_ 852 MHU_LA_AudWarning 500;
BA_ "InvalidValue" SG_ 852 MHU_LA_AudWarning "3h";
BA_ "GenSigStartValue" SG_ 852 MHU_BSD_On 1;
BA_ "GenSigTimeoutTime_ALL" SG_ 852 MHU_BSD_On 500;
BA_ "InvalidValue" SG_ 852 MHU_BSD_On "3h";
BA_ "GenSigStartValue" SG_ 852 MHU_BSD_sens 1;
BA_ "GenSigTimeoutTime_ALL" SG_ 852 MHU_BSD_sens 500;
BA_ "InvalidValue" SG_ 852 MHU_BSD_sens "3h";
BA_ "GenSigTimeoutTime_ALL" SG_ 852 MHU_BSD_AudWarning 500;
BA_ "InvalidValue" SG_ 852 MHU_BSD_AudWarning "3h";
BA_ "GenSigStartValue" SG_ 852 MHU_RCTA_On 1;
BA_ "GenSigTimeoutTime_ALL" SG_ 852 MHU_RCTA_On 500;
BA_ "InvalidValue" SG_ 852 MHU_RCTA_On "3h";
BA_ "GenSigStartValue" SG_ 852 MHU_RCTA_sens 1;
BA_ "GenSigTimeoutTime_ALL" SG_ 852 MHU_RCTA_sens 500;
BA_ "InvalidValue" SG_ 852 MHU_RCTA_sens "3h";
BA_ "GenSigStartValue" SG_ 852 MHU_PA_On 1;
BA_ "GenSigTimeoutTime_ALL" SG_ 852 MHU_PA_On 500;
BA_ "InvalidValue" SG_ 852 MHU_PA_On "3h";
BA_ "GenSigTimeoutTime_ALL" SG_ 852 MHU_AHB_On 500;
BA_ "InvalidValue" SG_ 852 MHU_AHB_On "3h";
BA_ "GenSigTimeoutTime_ALL" SG_ 852 MHU_IA_Mode 500;
BA_ "InvalidValue" SG_ 852 MHU_IA_Mode "3h";
BA_ "GenSigStartValue" SG_ 852 MHU_TSR_Mode 1;
BA_ "GenSigTimeoutTime_ALL" SG_ 852 MHU_TSR_Mode 500;
BA_ "InvalidValue" SG_ 852 MHU_TSR_Mode "3h";
BA_ "GenSigStartValue" SG_ 852 MHU_DOW_Mode 2;
BA_ "GenSigTimeoutTime_ALL" SG_ 852 MHU_DOW_Mode 500;
BA_ "InvalidValue" SG_ 852 MHU_DOW_Mode "3h";
BA_ "GenSigStartValue" SG_ 852 MHU_AHB_sens 1;
BA_ "GenSigTimeoutTime_ALL" SG_ 852 MHU_AHB_sens 500;
BA_ "InvalidValue" SG_ 852 MHU_AHB_sens "3h";
BA_ "GenSigStartValue" SG_ 852 MHU_LA_Mode 3;
BA_ "GenSigTimeoutTime_ALL" SG_ 852 MHU_LA_Mode 500;
BA_ "InvalidValue" SG_ 852 MHU_LA_Mode "4h";
BA_ "GenSigStartValue" SG_ 852 MHU_SET_TSR_AudWarn 1;
BA_ "GenSigTimeoutTime_ALL" SG_ 852 MHU_SET_TSR_AudWarn 500;
BA_ "InvalidValue" SG_ 852 MHU_SET_TSR_AudWarn "3h";
BA_ "GenSigStartValue" SG_ 852 MHU_SET_TSR_SLAert 1;
BA_ "GenSigTimeoutTime_ALL" SG_ 852 MHU_SET_TSR_SLAert 500;
BA_ "InvalidValue" SG_ 852 MHU_SET_TSR_SLAert "3h";
BA_ "GenSigTimeoutTime_ALL" SG_ 852 MHU_ESA_ON 500;
BA_ "GenSigStartValue" SG_ 852 MHU_ELKA_ON 1;
BA_ "GenSigTimeoutTime_ALL" SG_ 852 MHU_ELKA_ON 500;
BA_ "InvalidValue" SG_ 852 MHU_ELKA_ON "-";
BA_ "GenSigStartValue" SG_ 852 MHU_ALC_ON 1;
BA_ "GenSigTimeoutTime_ALL" SG_ 852 MHU_ALC_ON 500;
BA_ "InvalidValue" SG_ 852 MHU_ALC_ON "3h";
BA_ "GenSigTimeoutTime_ALL" SG_ 853 CHKSM_ADAS_CMP_CHECK 500;
BA_ "GenSigTimeoutTime_ALL" SG_ 853 ALV_ADAS_CMP_CHECK 500;
BA_ "InvalidValue" SG_ 853 ALV_ADAS_CMP_CHECK "Fh";
BA_ "GenSigTimeoutTime_ALL" SG_ 853 ADAS_PAUSS_FaultFLO 500;
BA_ "GenSigTimeoutTime_ALL" SG_ 853 ADAS_PAUSS_FaultFLI 500;
BA_ "GenSigTimeoutTime_ALL" SG_ 853 ADAS_PAUSS_check 500;
BA_ "InvalidValue" SG_ 853 ADAS_PAUSS_check "3h";
BA_ "GenSigTimeoutTime_ALL" SG_ 853 ADAS_PAUSS_FaultRLO 500;
BA_ "GenSigTimeoutTime_ALL" SG_ 853 ADAS_PAUSS_FaultFRI 500;
BA_ "GenSigTimeoutTime_ALL" SG_ 853 ADAS_FPA_check 500;
BA_ "InvalidValue" SG_ 853 ADAS_FPA_check "3h";
BA_ "GenSigTimeoutTime_ALL" SG_ 853 ADAS_PAUSS_FaultRLI 500;
BA_ "GenSigTimeoutTime_ALL" SG_ 853 ADAS_PAUSS_FaultRRO 500;
BA_ "GenSigTimeoutTime_ALL" SG_ 853 ADAS_PAUSS_FaultRRI 500;
BA_ "GenSigTimeoutTime_ALL" SG_ 853 ADAS_RPA_check 500;
BA_ "InvalidValue" SG_ 853 ADAS_RPA_check "3h";
BA_ "GenSigTimeoutTime_ALL" SG_ 853 ADAS_PAUSS_FaultFRO 500;
BA_ "GenSigTimeoutTime_ALL" SG_ 880 CRC_MHU_SBR_Status 1500;
BA_ "GenSigTimeoutTime_ALL" SG_ 880 ALV_MHU_SBR_Status 1500;
BA_ "InvalidValue" SG_ 880 ALV_MHU_SBR_Status "Fh";
BA_ "GenSigStartValue" SG_ 880 SBR_STAT_Chime 3;
BA_ "GenSigTimeoutTime_ALL" SG_ 880 SBR_STAT_Chime 1500;
BA_ "InvalidValue" SG_ 880 SBR_STAT_Chime "3h";
BA_ "GenSigStartValue" SG_ 880 SBR_STAT_Telltale 3;
BA_ "GenSigTimeoutTime_ALL" SG_ 880 SBR_STAT_Telltale 1500;
BA_ "InvalidValue" SG_ 880 SBR_STAT_Telltale "3h";
BA_ "GenSigTimeoutTime_ALL" SG_ 880 SBR_STAT_Active 1500;
BA_ "InvalidValue" SG_ 883 CHKSM_PDCU_PA "";
BA_ "GenSigTimeoutTime_ALL" SG_ 883 CHKSM_PDCU_PA 1000;
BA_ "InvalidValue" SG_ 883 ALV_PDCU_PA "Fh";
BA_ "GenSigTimeoutTime_ALL" SG_ 883 ALV_PDCU_PA 1000;
BA_ "InvalidValue" SG_ 883 PDCU_PA_State "7h";
BA_ "GenSigTimeoutTime_ALL" SG_ 883 PDCU_PA_State 1000;
BA_ "GenSigStartValue" SG_ 883 PDCU_PA_State 7;
BA_ "InvalidValue" SG_ 883 PDCU_PA_AutoOn_Feed "";
BA_ "GenSigTimeoutTime_ALL" SG_ 883 PDCU_PA_AutoOn_Feed 1000;
BA_ "InvalidValue" SG_ 883 PDCU_PA_AlertFLI "7h";
BA_ "GenSigTimeoutTime_ALL" SG_ 883 PDCU_PA_AlertFLI 1000;
BA_ "InvalidValue" SG_ 883 PDCU_PA_AlertFLO "7h";
BA_ "GenSigTimeoutTime_ALL" SG_ 883 PDCU_PA_AlertFLO 1000;
BA_ "InvalidValue" SG_ 883 PDCU_PA_AlertFRI "7h";
BA_ "GenSigTimeoutTime_ALL" SG_ 883 PDCU_PA_AlertFRI 1000;
BA_ "InvalidValue" SG_ 883 PDCU_PA_AlertFRO "7h";
BA_ "GenSigTimeoutTime_ALL" SG_ 883 PDCU_PA_AlertFRO 1000;
BA_ "InvalidValue" SG_ 883 PDCU_PA_AlertRLI "7h";
BA_ "GenSigTimeoutTime_ALL" SG_ 883 PDCU_PA_AlertRLI 1000;
BA_ "InvalidValue" SG_ 883 PDCU_PA_AlertRLO "7h";
BA_ "GenSigTimeoutTime_ALL" SG_ 883 PDCU_PA_AlertRLO 1000;
BA_ "InvalidValue" SG_ 883 PDCU_PA_AlertRRI "7h";
BA_ "GenSigTimeoutTime_ALL" SG_ 883 PDCU_PA_AlertRRI 1000;
BA_ "InvalidValue" SG_ 883 PDCU_PA_AlertRRO "7h";
BA_ "GenSigTimeoutTime_ALL" SG_ 883 PDCU_PA_AlertRRO 1000;
BA_ "InvalidValue" SG_ 883 PDCU_PA_FPA_Check "3h";
BA_ "GenSigTimeoutTime_ALL" SG_ 883 PDCU_PA_FPA_Check 1000;
BA_ "InvalidValue" SG_ 883 PDCU_PA_RPA_Check "3h";
BA_ "GenSigTimeoutTime_ALL" SG_ 883 PDCU_PA_RPA_Check 1000;
BA_ "InvalidValue" SG_ 884 PDCU_FPA_DistFLI "FFh";
BA_ "GenSigTimeoutTime_ALL" SG_ 884 PDCU_FPA_DistFLI 1000;
BA_ "GenSigStartValue" SG_ 884 PDCU_FPA_DistFLI 255;
BA_ "InvalidValue" SG_ 884 PDCU_FPA_DistFLO "FFh";
BA_ "GenSigTimeoutTime_ALL" SG_ 884 PDCU_FPA_DistFLO 1000;
BA_ "GenSigStartValue" SG_ 884 PDCU_FPA_DistFLO 255;
BA_ "InvalidValue" SG_ 884 PDCU_FPA_DistFRI "FFh";
BA_ "GenSigTimeoutTime_ALL" SG_ 884 PDCU_FPA_DistFRI 1000;
BA_ "GenSigStartValue" SG_ 884 PDCU_FPA_DistFRI 255;
BA_ "InvalidValue" SG_ 884 PDCU_FPA_DistFRO "FFh";
BA_ "GenSigTimeoutTime_ALL" SG_ 884 PDCU_FPA_DistFRO 1000;
BA_ "GenSigStartValue" SG_ 884 PDCU_FPA_DistFRO 255;
BA_ "InvalidValue" SG_ 884 PDCU_RPA_DistRLI "FFh";
BA_ "GenSigTimeoutTime_ALL" SG_ 884 PDCU_RPA_DistRLI 1000;
BA_ "GenSigStartValue" SG_ 884 PDCU_RPA_DistRLI 255;
BA_ "InvalidValue" SG_ 884 PDCU_RPA_DistRLO "FFh";
BA_ "GenSigTimeoutTime_ALL" SG_ 884 PDCU_RPA_DistRLO 1000;
BA_ "GenSigStartValue" SG_ 884 PDCU_RPA_DistRLO 255;
BA_ "InvalidValue" SG_ 884 PDCU_RPA_DistRRI "FFh";
BA_ "GenSigTimeoutTime_ALL" SG_ 884 PDCU_RPA_DistRRI 1000;
BA_ "GenSigStartValue" SG_ 884 PDCU_RPA_DistRRI 255;
BA_ "InvalidValue" SG_ 884 PDCU_RPA_DistRRO "FFh";
BA_ "GenSigTimeoutTime_ALL" SG_ 884 PDCU_RPA_DistRRO 1000;
BA_ "GenSigStartValue" SG_ 884 PDCU_RPA_DistRRO 255;
BA_ "GenSigTimeoutTime_ALL" SG_ 885 Checksum_0x375 500;
BA_ "InvalidValue" SG_ 885 Checksum_0x375 "null";
BA_ "GenSigTimeoutTime_ALL" SG_ 885 Rolling_Counter_0x375 500;
BA_ "InvalidValue" SG_ 885 Rolling_Counter_0x375 "Fh";
BA_ "GenSigTimeoutTime_ALL" SG_ 885 BMS_PreChgRelay_ERR 500;
BA_ "InvalidValue" SG_ 885 BMS_PreChgRelay_ERR "null";
BA_ "GenSigTimeoutTime_ALL" SG_ 885 BMS_TotalNegRelay_ERR 500;
BA_ "InvalidValue" SG_ 885 BMS_TotalNegRelay_ERR "null";
BA_ "GenSigTimeoutTime_ALL" SG_ 885 BMS_MainPosRelay_ERR 500;
BA_ "InvalidValue" SG_ 885 BMS_MainPosRelay_ERR "null";
BA_ "GenSigTimeoutTime_ALL" SG_ 885 BMS_MainPosRelay_STS 500;
BA_ "InvalidValue" SG_ 885 BMS_MainPosRelay_STS "7h";
BA_ "GenSigTimeoutTime_ALL" SG_ 885 BMS_PreChgRelay_STS 500;
BA_ "InvalidValue" SG_ 885 BMS_PreChgRelay_STS "7h";
BA_ "GenSigTimeoutTime_ALL" SG_ 885 BMS_TotalNegRelay_STS 500;
BA_ "InvalidValue" SG_ 885 BMS_TotalNegRelay_STS "7h";
BA_ "GenSigTimeoutTime_ALL" SG_ 886 CHKSM_USS_RPA 1000;
BA_ "GenSigTimeoutTime_ALL" SG_ 886 ALV_USS_RPA 1000;
BA_ "GenSigStartValue" SG_ 886 USS_RPA_state 7;
BA_ "GenSigTimeoutTime_ALL" SG_ 886 USS_RPA_state 1000;
BA_ "InvalidValue" SG_ 886 USS_RPA_state "7h";
BA_ "GenSigTimeoutTime_ALL" SG_ 886 USS_RPA_AlertRLI 1000;
BA_ "InvalidValue" SG_ 886 USS_RPA_AlertRLI "7h";
BA_ "GenSigTimeoutTime_ALL" SG_ 886 USS_RPA_AlertRLO 1000;
BA_ "InvalidValue" SG_ 886 USS_RPA_AlertRLO "7h";
BA_ "GenSigTimeoutTime_ALL" SG_ 886 USS_RPA_AlertRRI 1000;
BA_ "InvalidValue" SG_ 886 USS_RPA_AlertRRI "7h";
BA_ "GenSigTimeoutTime_ALL" SG_ 886 USS_RPA_AlertRRO 1000;
BA_ "InvalidValue" SG_ 886 USS_RPA_AlertRRO "7h";
BA_ "GenSigStartValue" SG_ 886 USS_RPA_SensorRLI 3;
BA_ "GenSigTimeoutTime_ALL" SG_ 886 USS_RPA_SensorRLI 1000;
BA_ "InvalidValue" SG_ 886 USS_RPA_SensorRLI "3h";
BA_ "GenSigStartValue" SG_ 886 USS_RPA_SensorRLO 3;
BA_ "GenSigTimeoutTime_ALL" SG_ 886 USS_RPA_SensorRLO 1000;
BA_ "InvalidValue" SG_ 886 USS_RPA_SensorRLO "3h";
BA_ "GenSigStartValue" SG_ 886 USS_RPA_SensorRRI 3;
BA_ "GenSigTimeoutTime_ALL" SG_ 886 USS_RPA_SensorRRI 1000;
BA_ "InvalidValue" SG_ 886 USS_RPA_SensorRRI "3h";
BA_ "GenSigStartValue" SG_ 886 USS_RPA_SensorRRO 3;
BA_ "GenSigTimeoutTime_ALL" SG_ 886 USS_RPA_SensorRRO 1000;
BA_ "InvalidValue" SG_ 886 USS_RPA_SensorRRO "3h";
BA_ "GenSigTimeoutTime_ALL" SG_ 887 CHKSM_USS_FPA 1000;
BA_ "GenSigTimeoutTime_ALL" SG_ 887 ALV_USS_FPA 1000;
BA_ "GenSigStartValue" SG_ 887 USS_FPA_state 7;
BA_ "GenSigTimeoutTime_ALL" SG_ 887 USS_FPA_state 1000;
BA_ "InvalidValue" SG_ 887 USS_FPA_state "7h";
BA_ "GenSigTimeoutTime_ALL" SG_ 887 USS_FPA_AutoOn_Feed 1000;
BA_ "GenSigTimeoutTime_ALL" SG_ 887 USS_FPA_AlertFLI 1000;
BA_ "InvalidValue" SG_ 887 USS_FPA_AlertFLI "7h";
BA_ "GenSigTimeoutTime_ALL" SG_ 887 USS_FPA_AlertFLO 1000;
BA_ "InvalidValue" SG_ 887 USS_FPA_AlertFLO "7h";
BA_ "GenSigTimeoutTime_ALL" SG_ 887 USS_FPA_AlertFRI 1000;
BA_ "InvalidValue" SG_ 887 USS_FPA_AlertFRI "7h";
BA_ "GenSigTimeoutTime_ALL" SG_ 887 USS_FPA_AlertFRO 1000;
BA_ "InvalidValue" SG_ 887 USS_FPA_AlertFRO "7h";
BA_ "GenSigStartValue" SG_ 887 USS_FPA_SensorFLI 3;
BA_ "GenSigTimeoutTime_ALL" SG_ 887 USS_FPA_SensorFLI 1000;
BA_ "InvalidValue" SG_ 887 USS_FPA_SensorFLI "3h";
BA_ "GenSigStartValue" SG_ 887 USS_FPA_SensorFLO 3;
BA_ "GenSigTimeoutTime_ALL" SG_ 887 USS_FPA_SensorFLO 1000;
BA_ "InvalidValue" SG_ 887 USS_FPA_SensorFLO "3h";
BA_ "GenSigStartValue" SG_ 887 USS_FPA_SensorFRI 3;
BA_ "GenSigTimeoutTime_ALL" SG_ 887 USS_FPA_SensorFRI 1000;
BA_ "InvalidValue" SG_ 887 USS_FPA_SensorFRI "3h";
BA_ "GenSigStartValue" SG_ 887 USS_FPA_SensorFRO 3;
BA_ "GenSigTimeoutTime_ALL" SG_ 887 USS_FPA_SensorFRO 1000;
BA_ "InvalidValue" SG_ 887 USS_FPA_SensorFRO "3h";
BA_ "GenSigTimeoutTime_ALL" SG_ 888 CHKSM_RawDist_RPA 1000;
BA_ "GenSigTimeoutTime_ALL" SG_ 888 ALV_RawDist_RPA 1000;
BA_ "GenSigStartValue" SG_ 888 USS_RPA_DistRLI 255;
BA_ "GenSigTimeoutTime_ALL" SG_ 888 USS_RPA_DistRLI 1000;
BA_ "InvalidValue" SG_ 888 USS_RPA_DistRLI "FFh";
BA_ "GenSigStartValue" SG_ 888 USS_RPA_DistRLO 255;
BA_ "GenSigTimeoutTime_ALL" SG_ 888 USS_RPA_DistRLO 1000;
BA_ "InvalidValue" SG_ 888 USS_RPA_DistRLO "FFh";
BA_ "GenSigStartValue" SG_ 888 USS_RPA_DistRRI 255;
BA_ "GenSigTimeoutTime_ALL" SG_ 888 USS_RPA_DistRRI 1000;
BA_ "InvalidValue" SG_ 888 USS_RPA_DistRRI "FFh";
BA_ "GenSigStartValue" SG_ 888 USS_RPA_DistRRO 255;
BA_ "GenSigTimeoutTime_ALL" SG_ 888 USS_RPA_DistRRO 1000;
BA_ "InvalidValue" SG_ 888 USS_RPA_DistRRO "FFh";
BA_ "GenSigTimeoutTime_ALL" SG_ 889 CHKSM_RawDist_FPA 1000;
BA_ "GenSigTimeoutTime_ALL" SG_ 889 ALV_RawDist_FPA 1000;
BA_ "GenSigStartValue" SG_ 889 USS_FPA_DistFLI 255;
BA_ "GenSigTimeoutTime_ALL" SG_ 889 USS_FPA_DistFLI 1000;
BA_ "InvalidValue" SG_ 889 USS_FPA_DistFLI "FFh";
BA_ "GenSigStartValue" SG_ 889 USS_FPA_DistFLO 255;
BA_ "GenSigTimeoutTime_ALL" SG_ 889 USS_FPA_DistFLO 1000;
BA_ "InvalidValue" SG_ 889 USS_FPA_DistFLO "FFh";
BA_ "GenSigStartValue" SG_ 889 USS_FPA_DistFRI 255;
BA_ "GenSigTimeoutTime_ALL" SG_ 889 USS_FPA_DistFRI 1000;
BA_ "InvalidValue" SG_ 889 USS_FPA_DistFRI "FFh";
BA_ "GenSigStartValue" SG_ 889 USS_FPA_DistFRO 255;
BA_ "GenSigTimeoutTime_ALL" SG_ 889 USS_FPA_DistFRO 1000;
BA_ "InvalidValue" SG_ 889 USS_FPA_DistFRO "FFh";
BA_ "GenSigTimeoutTime_ALL" SG_ 896 VIN_Byte1 5000;
BA_ "InvalidValue" SG_ 896 VIN_Byte1 "null";
BA_ "GenSigTimeoutTime_ALL" SG_ 896 VIN_Byte2 5000;
BA_ "InvalidValue" SG_ 896 VIN_Byte2 "null";
BA_ "GenSigTimeoutTime_ALL" SG_ 896 VIN_Byte3 5000;
BA_ "InvalidValue" SG_ 896 VIN_Byte3 "null";
BA_ "GenSigTimeoutTime_ALL" SG_ 896 VIN_Byte4 5000;
BA_ "InvalidValue" SG_ 896 VIN_Byte4 "null";
BA_ "GenSigTimeoutTime_ALL" SG_ 896 VIN_Byte5 5000;
BA_ "InvalidValue" SG_ 896 VIN_Byte5 "null";
BA_ "GenSigTimeoutTime_ALL" SG_ 896 VIN_Byte6 5000;
BA_ "InvalidValue" SG_ 896 VIN_Byte6 "null";
BA_ "GenSigTimeoutTime_ALL" SG_ 896 VIN_Byte7 5000;
BA_ "InvalidValue" SG_ 896 VIN_Byte7 "null";
BA_ "GenSigTimeoutTime_ALL" SG_ 897 CHKSM_ACM_SEAT_OCCUPATION 1000;
BA_ "InvalidValue" SG_ 897 CHKSM_ACM_SEAT_OCCUPATION "null";
BA_ "GenSigTimeoutTime_ALL" SG_ 897 ALV_ACM_SEAT_OCCUPATION 1000;
BA_ "InvalidValue" SG_ 897 ALV_ACM_SEAT_OCCUPATION "Fh";
BA_ "GenSigTimeoutTime_ALL" SG_ 897 ACM_Seat_Occupancy_Passenger 1000;
BA_ "InvalidValue" SG_ 897 ACM_Seat_Occupancy_Passenger "null";
BA_ "GenSigTimeoutTime_ALL" SG_ 897 ACM_Seat_Occupancy_2nd_Row_Dri 1000;
BA_ "InvalidValue" SG_ 897 ACM_Seat_Occupancy_2nd_Row_Dri "null";
BA_ "GenSigTimeoutTime_ALL" SG_ 897 ACM_Seat_Occupancy_2nd_Row_Pas 1000;
BA_ "InvalidValue" SG_ 897 ACM_Seat_Occupancy_2nd_Row_Pas "null";
BA_ "GenSigTimeoutTime_ALL" SG_ 897 ACM_Seat_Occupancy_2nd_Row_Mid 1000;
BA_ "InvalidValue" SG_ 897 ACM_Seat_Occupancy_2nd_Row_Mid "null";
BA_ "GenSigTimeoutTime_ALL" SG_ 897 ACM_Seat_Belt_Status_Passenger 1000;
BA_ "InvalidValue" SG_ 897 ACM_Seat_Belt_Status_Passenger "null";
BA_ "GenSigTimeoutTime_ALL" SG_ 897 ACM_Seat_Belt_Status_Driver 1000;
BA_ "InvalidValue" SG_ 897 ACM_Seat_Belt_Status_Driver "null";
BA_ "GenSigTimeoutTime_ALL" SG_ 897 ACM_Seat_Belt_Status_2nd_Row_Dri 1000;
BA_ "InvalidValue" SG_ 897 ACM_Seat_Belt_Status_2nd_Row_Dri "null";
BA_ "GenSigTimeoutTime_ALL" SG_ 897 ACM_Seat_Belt_Status_2nd_Row_Mid 1000;
BA_ "InvalidValue" SG_ 897 ACM_Seat_Belt_Status_2nd_Row_Mid "null";
BA_ "GenSigTimeoutTime_ALL" SG_ 897 ACM_Seat_Belt_Status_2nd_Row_Pas 1000;
BA_ "InvalidValue" SG_ 897 ACM_Seat_Belt_Status_2nd_Row_Pas "null";
BA_ "InvalidValue" SG_ 882 CHKSM_PDC_RearDist "";
BA_ "GenSigTimeoutTime_ALL" SG_ 882 CHKSM_PDC_RearDist 1000;
BA_ "InvalidValue" SG_ 882 ALV_PDC_RearDist "Fh";
BA_ "GenSigTimeoutTime_ALL" SG_ 882 ALV_PDC_RearDist 1000;
BA_ "GenSigStartValue" SG_ 882 PDC_ObstacleDistance_RSL 255;
BA_ "InvalidValue" SG_ 882 PDC_ObstacleDistance_RSL "FFh";
BA_ "GenSigTimeoutTime_ALL" SG_ 882 PDC_ObstacleDistance_RSL 1000;
BA_ "GenSigStartValue" SG_ 882 PDC_ObstacleDistance_RL 255;
BA_ "InvalidValue" SG_ 882 PDC_ObstacleDistance_RL "FFh";
BA_ "GenSigTimeoutTime_ALL" SG_ 882 PDC_ObstacleDistance_RL 1000;
BA_ "GenSigStartValue" SG_ 882 PDC_ObstacleDistance_RML 255;
BA_ "InvalidValue" SG_ 882 PDC_ObstacleDistance_RML "FFh";
BA_ "GenSigTimeoutTime_ALL" SG_ 882 PDC_ObstacleDistance_RML 1000;
BA_ "GenSigStartValue" SG_ 882 PDC_ObstacleDistance_RMR 255;
BA_ "InvalidValue" SG_ 882 PDC_ObstacleDistance_RMR "FFh";
BA_ "GenSigTimeoutTime_ALL" SG_ 882 PDC_ObstacleDistance_RMR 1000;
BA_ "GenSigStartValue" SG_ 882 PDC_ObstacleDistance_RR 255;
BA_ "InvalidValue" SG_ 882 PDC_ObstacleDistance_RR "FFh";
BA_ "GenSigTimeoutTime_ALL" SG_ 882 PDC_ObstacleDistance_RR 1000;
BA_ "GenSigStartValue" SG_ 882 PDC_ObstacleDistance_RSR 255;
BA_ "InvalidValue" SG_ 882 PDC_ObstacleDistance_RSR "FFh";
BA_ "GenSigTimeoutTime_ALL" SG_ 882 PDC_ObstacleDistance_RSR 1000;
BA_ "InvalidValue" SG_ 881 CHKSM_PDC_FrontDist "";
BA_ "GenSigTimeoutTime_ALL" SG_ 881 CHKSM_PDC_FrontDist 1000;
BA_ "InvalidValue" SG_ 881 ALV_PDC_FrontDist "Fh";
BA_ "GenSigTimeoutTime_ALL" SG_ 881 ALV_PDC_FrontDist 1000;
BA_ "GenSigStartValue" SG_ 881 PDC_ObstacleDistance_FSL 255;
BA_ "InvalidValue" SG_ 881 PDC_ObstacleDistance_FSL "FFh";
BA_ "GenSigTimeoutTime_ALL" SG_ 881 PDC_ObstacleDistance_FSL 1000;
BA_ "GenSigStartValue" SG_ 881 PDC_ObstacleDistance_FL 255;
BA_ "InvalidValue" SG_ 881 PDC_ObstacleDistance_FL "FFh";
BA_ "GenSigTimeoutTime_ALL" SG_ 881 PDC_ObstacleDistance_FL 1000;
BA_ "GenSigStartValue" SG_ 881 PDC_ObstacleDistance_FML 255;
BA_ "InvalidValue" SG_ 881 PDC_ObstacleDistance_FML "FFh";
BA_ "GenSigTimeoutTime_ALL" SG_ 881 PDC_ObstacleDistance_FML 1000;
BA_ "GenSigStartValue" SG_ 881 PDC_ObstacleDistance_FMR 255;
BA_ "InvalidValue" SG_ 881 PDC_ObstacleDistance_FMR "FFh";
BA_ "GenSigTimeoutTime_ALL" SG_ 881 PDC_ObstacleDistance_FMR 1000;
BA_ "GenSigStartValue" SG_ 881 PDC_ObstacleDistance_FR 255;
BA_ "InvalidValue" SG_ 881 PDC_ObstacleDistance_FR "FFh";
BA_ "GenSigTimeoutTime_ALL" SG_ 881 PDC_ObstacleDistance_FR 1000;
BA_ "GenSigStartValue" SG_ 881 PDC_ObstacleDistance_FSR 255;
BA_ "InvalidValue" SG_ 881 PDC_ObstacleDistance_FSR "FFh";
BA_ "GenSigTimeoutTime_ALL" SG_ 881 PDC_ObstacleDistance_FSR 1000;
BA_ "GenSigSendType" SG_ 905 VCU_IMMO_Sts 1;
BA_ "InvalidValue" SG_ 905 VCU_IMMO_Sts "";
BA_ "GenSigSendType" SG_ 905 SECCAN_VCU_IMMO_Sts 1;
BA_ "InvalidValue" SG_ 905 SECCAN_VCU_IMMO_Sts "";
BA_ "GenSigSendType" SG_ 915 MHU_SET_HudRotateLvl 2;
BA_ "InvalidValue" SG_ 915 MHU_SET_HudRotateLvl "Fh";
BA_ "GenSigSendType" SG_ 915 MHU_SET_HudHeightLvl 2;
BA_ "InvalidValue" SG_ 915 MHU_SET_HudHeightLvl "0h";
BA_ "GenSigSendType" SG_ 922 MHU_Immo_Byte_0 2;
BA_ "InvalidValue" SG_ 922 MHU_Immo_Byte_0 "null";
BA_ "GenSigSendType" SG_ 922 MHU_Immo_Byte_1 2;
BA_ "InvalidValue" SG_ 922 MHU_Immo_Byte_1 "null";
BA_ "GenSigSendType" SG_ 922 MHU_Immo_Byte_2 2;
BA_ "InvalidValue" SG_ 922 MHU_Immo_Byte_2 "null";
BA_ "GenSigSendType" SG_ 922 MHU_Immo_Byte_3 2;
BA_ "InvalidValue" SG_ 922 MHU_Immo_Byte_3 "null";
BA_ "GenSigSendType" SG_ 922 MHU_Immo_Byte_4 2;
BA_ "InvalidValue" SG_ 922 MHU_Immo_Byte_4 "null";
BA_ "GenSigSendType" SG_ 922 MHU_Immo_Byte_5 2;
BA_ "InvalidValue" SG_ 922 MHU_Immo_Byte_5 "null";
BA_ "GenSigSendType" SG_ 922 MHU_Immo_Byte_6 2;
BA_ "InvalidValue" SG_ 922 MHU_Immo_Byte_6 "null";
BA_ "GenSigSendType" SG_ 922 MHU_Immo_Byte_7 2;
BA_ "InvalidValue" SG_ 922 MHU_Immo_Byte_7 "null";
BA_ "GenSigSendType" SG_ 923 BCM_Immo_MHU_Byte_0 2;
BA_ "InvalidValue" SG_ 923 BCM_Immo_MHU_Byte_0 "null";
BA_ "GenSigSendType" SG_ 923 BCM_Immo_MHU_Byte_1 2;
BA_ "InvalidValue" SG_ 923 BCM_Immo_MHU_Byte_1 "null";
BA_ "GenSigSendType" SG_ 923 BCM_Immo_MHU_Byte_2 2;
BA_ "InvalidValue" SG_ 923 BCM_Immo_MHU_Byte_2 "null";
BA_ "GenSigSendType" SG_ 923 BCM_Immo_MHU_Byte_3 2;
BA_ "InvalidValue" SG_ 923 BCM_Immo_MHU_Byte_3 "null";
BA_ "GenSigSendType" SG_ 923 BCM_Immo_MHU_Byte_4 2;
BA_ "InvalidValue" SG_ 923 BCM_Immo_MHU_Byte_4 "null";
BA_ "GenSigSendType" SG_ 923 BCM_Immo_MHU_Byte_5 2;
BA_ "InvalidValue" SG_ 923 BCM_Immo_MHU_Byte_5 "null";
BA_ "GenSigSendType" SG_ 923 BCM_Immo_MHU_Byte_6 2;
BA_ "InvalidValue" SG_ 923 BCM_Immo_MHU_Byte_6 "null";
BA_ "GenSigSendType" SG_ 923 BCM_Immo_MHU_Byte_7 2;
BA_ "InvalidValue" SG_ 923 BCM_Immo_MHU_Byte_7 "null";
BA_ "GenSigTimeoutTime_ALL" SG_ 925 CHKSM_BCM_HighBeam_PosReq 500;
BA_ "InvalidValue" SG_ 925 ALIVE_BCM_HighBeam_PosReq "Fh";
BA_ "GenSigTimeoutTime_ALL" SG_ 925 ALIVE_BCM_HighBeam_PosReq 500;
BA_ "InvalidValue" SG_ 925 BCM_ADAS_AHB_state "3h";
BA_ "GenSigTimeoutTime_ALL" SG_ 925 BCM_ADAS_AHB_state 500;
BA_ "GenSigTimeoutTime_ALL" SG_ 925 BCM_AHB_Override 500;
BA_ "InvalidValue" SG_ 925 BCM_AHB_Override "3h";
BA_ "InvalidValue" SG_ 925 BCM_ADAS_AHB_RBPos_feed "";
BA_ "GenSigTimeoutTime_ALL" SG_ 925 BCM_ADAS_AHB_RBPos_feed 500;
BA_ "InvalidValue" SG_ 925 BCM_ADAS_AHB_LBPos_feed "";
BA_ "GenSigTimeoutTime_ALL" SG_ 925 BCM_ADAS_AHB_LBPos_feed 500;
BA_ "InvalidValue" SG_ 925 BCM_AHB_ICON_Feed "7h";
BA_ "GenSigTimeoutTime_ALL" SG_ 925 BCM_AHB_ICON_Feed 500;
BA_ "GenSigSendType" SG_ 943 MHU_UTF8Character_Byte1 1;
BA_ "InvalidValue" SG_ 943 MHU_UTF8Character_Byte1 "FFh";
BA_ "GenSigSendType" SG_ 943 MHU_UTF8Character_Byte2 1;
BA_ "InvalidValue" SG_ 943 MHU_UTF8Character_Byte2 "FFh";
BA_ "GenSigSendType" SG_ 943 MHU_UTF8Character_Byte3 1;
BA_ "InvalidValue" SG_ 943 MHU_UTF8Character_Byte3 "FFh";
BA_ "GenSigSendType" SG_ 943 MHU_UTF8Character_Byte4 1;
BA_ "InvalidValue" SG_ 943 MHU_UTF8Character_Byte4 "FFh";
BA_ "GenSigSendType" SG_ 943 MHU_UTF8Character_Byte5 1;
BA_ "InvalidValue" SG_ 943 MHU_UTF8Character_Byte5 "FFh";
BA_ "GenSigSendType" SG_ 943 MHU_UTF8Character_Byte6 1;
BA_ "InvalidValue" SG_ 943 MHU_UTF8Character_Byte6 "FFh";
BA_ "GenSigSendType" SG_ 943 MHU_IPC_ID 1;
BA_ "InvalidValue" SG_ 943 MHU_IPC_ID "Fh";
BA_ "GenSigSendType" SG_ 943 MHU_TotalMessages 1;
BA_ "GenSigStartValue" SG_ 943 MHU_TotalMessages 1;
BA_ "InvalidValue" SG_ 943 MHU_TotalMessages "Fh";
BA_ "GenSigSendType" SG_ 943 MHU_MessageNumber 1;
BA_ "GenSigStartValue" SG_ 943 MHU_MessageNumber 1;
BA_ "InvalidValue" SG_ 943 MHU_MessageNumber "Fh";
BA_ "GenSigSendType" SG_ 964 MHU_Nav_State 1;
BA_ "InvalidValue" SG_ 964 MHU_Nav_State "7h";
BA_ "GenSigSendType" SG_ 964 MHU_NavSource 1;
BA_ "InvalidValue" SG_ 964 MHU_NavSource "7h";
BA_ "GenSigSendType" SG_ 964 MHU_Nav_DistanceToNextTurn 1;
BA_ "GenSigSendType" SG_ 964 MHU_Nav_DistanceToNextTurnUnits 1;
BA_ "GenSigSendType" SG_ 964 MHU_Nav_TBT_Icon 1;
BA_ "GenSigSendType" SG_ 964 MHU_Nav_ImageChannel_Ready 1;
BA_ "GenSigSendType" SG_ 964 MHU_Nav_Language 1;
BA_ "InvalidValue" SG_ 964 MHU_Nav_Language "FFh";
BA_ "GenSigSendType" SG_ 964 SECCAN_NAV_DISP 1;
BA_ "GenSigSendType" SG_ 965 MHU_NavGuidance_TotalMsg 1;
BA_ "GenSigSendType" SG_ 965 MHU_NavGuidance_MsgNum 1;
BA_ "GenSigSendType" SG_ 965 MHU_NavGuidance_UTF8_Byte1 1;
BA_ "GenSigSendType" SG_ 965 MHU_NavGuidance_UTF8_Byte2 1;
BA_ "GenSigSendType" SG_ 965 MHU_NavGuidance_UTF8_Byte3 1;
BA_ "GenSigSendType" SG_ 965 MHU_NavGuidance_UTF8_Byte4 1;
BA_ "GenSigSendType" SG_ 965 MHU_NavGuidance_UTF8_Byte5 1;
BA_ "GenSigSendType" SG_ 965 MHU_NavGuidance_UTF8_Byte6 1;
BA_ "GenSigSendType" SG_ 966 MHU_NavDist_MsgNum 1;
BA_ "GenSigSendType" SG_ 966 MHU_NavDist_TotalMsg 1;
BA_ "GenSigSendType" SG_ 966 MHU_NavDist_UTF8_Byte1 1;
BA_ "GenSigSendType" SG_ 966 MHU_NavDist_UTF8_Byte2 1;
BA_ "GenSigSendType" SG_ 966 MHU_NavDist_UTF8_Byte3 1;
BA_ "GenSigSendType" SG_ 966 MHU_NavDist_UTF8_Byte4 1;
BA_ "GenSigSendType" SG_ 966 MHU_NavDist_UTF8_Byte5 1;
BA_ "GenSigSendType" SG_ 966 MHU_NavDist_UTF8_Byte6 1;
BA_ "GenSigTimeoutTime_ALL" SG_ 992 CRC_VCU_HVsystem_status 200;
BA_ "GenSigTimeoutTime_ALL" SG_ 992 ALIV_VCU_HVsystem_status 200;
BA_ "InvalidValue" SG_ 992 ALIV_VCU_HVsystem_status "Fh";
BA_ "GenSigTimeoutTime_ALL" SG_ 992 VCU_RunningRange 200;
BA_ "InvalidValue" SG_ 992 VCU_RunningRange "null";
BA_ "GenSigTimeoutTime_ALL" SG_ 992 VCU_RunningRange_chrg_estSts 200;
BA_ "InvalidValue" SG_ 992 VCU_RunningRange_chrg_estSts "null";
BA_ "GenSigTimeoutTime_ALL" SG_ 992 VCU_RunningRange_charged 200;
BA_ "InvalidValue" SG_ 992 VCU_RunningRange_charged "null";
BA_ "GenSigTimeoutTime_ALL" SG_ 992 VCU_HVbatSoc_charged 200;
BA_ "InvalidValue" SG_ 992 VCU_HVbatSoc_charged "null";
BA_ "GenSigTimeoutTime_ALL" SG_ 992 VCU_HVbatSoc_charged_estStatus 200;
BA_ "InvalidValue" SG_ 992 VCU_HVbatSoc_charged_estStatus "null";
BA_ "GenSigTimeoutTime_ALL" SG_ 993 CRC_VCU_HMI_Info 500;
BA_ "InvalidValue" SG_ 993 CRC_VCU_HMI_Info "null";
BA_ "GenSigTimeoutTime_ALL" SG_ 993 ALIV_VCU_HMI_Info 500;
BA_ "InvalidValue" SG_ 993 ALIV_VCU_HMI_Info "Fh";
BA_ "GenSigTimeoutTime_ALL" SG_ 993 VCU_SetCruiseSpd 500;
BA_ "InvalidValue" SG_ 993 VCU_SetCruiseSpd "FFh";
BA_ "GenSigTimeoutTime_ALL" SG_ 993 VCU_CruiseCtrlSts 500;
BA_ "InvalidValue" SG_ 993 VCU_CruiseCtrlSts "";
BA_ "GenSigStartValue" SG_ 993 VCU_MHU_Ack_ChgSche_stt 3;
BA_ "GenSigTimeoutTime_ALL" SG_ 993 VCU_MHU_Ack_ChgSche_stt 500;
BA_ "InvalidValue" SG_ 993 VCU_MHU_Ack_ChgSche_stt "3h";
BA_ "GenSigStartValue" SG_ 993 VCU_MHU_Ack_TargetSOC 100;
BA_ "GenSigTimeoutTime_ALL" SG_ 993 VCU_MHU_Ack_TargetSOC 500;
BA_ "InvalidValue" SG_ 993 VCU_MHU_Ack_TargetSOC "7Fh";
BA_ "GenSigTimeoutTime_ALL" SG_ 993 VCU_ValetMode_sts 500;
BA_ "InvalidValue" SG_ 993 VCU_ValetMode_sts "FFh";
BA_ "GenSigTimeoutTime_ALL" SG_ 993 VCU_ValetMode_MaxSpeedSts 500;
BA_ "InvalidValue" SG_ 993 VCU_ValetMode_MaxSpeedSts "FFh";
BA_ "GenSigTimeoutTime_ALL" SG_ 993 SECCAN_VCU_HMI_Info 500;
BA_ "InvalidValue" SG_ 993 SECCAN_VCU_HMI_Info "null";
BA_ "GenSigSendType" SG_ 1015 CHSKM_MFS_Control_Button 4;
BA_ "GenSigTimeoutTime_ALL" SG_ 1015 CHSKM_MFS_Control_Button 5000;
BA_ "InvalidValue" SG_ 1015 CHSKM_MFS_Control_Button "null";
BA_ "GenSigSendType" SG_ 1015 ALV_MFS_Control_Button 4;
BA_ "GenSigTimeoutTime_ALL" SG_ 1015 ALV_MFS_Control_Button 5000;
BA_ "InvalidValue" SG_ 1015 ALV_MFS_Control_Button "Fh";
BA_ "GenSigSendType" SG_ 1015 MFS_VoiceRecognitionOn_Off 4;
BA_ "GenSigTimeoutTime_ALL" SG_ 1015 MFS_VoiceRecognitionOn_Off 5000;
BA_ "InvalidValue" SG_ 1015 MFS_VoiceRecognitionOn_Off "4h";
BA_ "GenSigSendType" SG_ 1015 MFS_ISAControl 4;
BA_ "GenSigTimeoutTime_ALL" SG_ 1015 MFS_ISAControl 5000;
BA_ "InvalidValue" SG_ 1015 MFS_ISAControl "3h";
BA_ "GenSigSendType" SG_ 1015 MFS_CruiseSpeedIncrease 4;
BA_ "GenSigTimeoutTime_ALL" SG_ 1015 MFS_CruiseSpeedIncrease 5000;
BA_ "InvalidValue" SG_ 1015 MFS_CruiseSpeedIncrease "4h";
BA_ "GenSigSendType" SG_ 1015 MFS_TelephoneCall_EndCall 4;
BA_ "GenSigTimeoutTime_ALL" SG_ 1015 MFS_TelephoneCall_EndCall 5000;
BA_ "InvalidValue" SG_ 1015 MFS_TelephoneCall_EndCall "4h";
BA_ "GenSigSendType" SG_ 1015 MFS_LKAControl 4;
BA_ "GenSigTimeoutTime_ALL" SG_ 1015 MFS_LKAControl 5000;
BA_ "InvalidValue" SG_ 1015 MFS_LKAControl "3h";
BA_ "GenSigSendType" SG_ 1015 MFS_CruiseGapIncrease 4;
BA_ "GenSigTimeoutTime_ALL" SG_ 1015 MFS_CruiseGapIncrease 5000;
BA_ "InvalidValue" SG_ 1015 MFS_CruiseGapIncrease "4h";
BA_ "GenSigSendType" SG_ 1015 MFS_CruiseOn_Off 4;
BA_ "GenSigTimeoutTime_ALL" SG_ 1015 MFS_CruiseOn_Off 5000;
BA_ "InvalidValue" SG_ 1015 MFS_CruiseOn_Off "4h";
BA_ "GenSigSendType" SG_ 1015 MFS_CruiseGapDecrease 4;
BA_ "GenSigTimeoutTime_ALL" SG_ 1015 MFS_CruiseGapDecrease 5000;
BA_ "InvalidValue" SG_ 1015 MFS_CruiseGapDecrease "4h";
BA_ "GenSigSendType" SG_ 1015 MFS_CAN_RESControl 4;
BA_ "GenSigTimeoutTime_ALL" SG_ 1015 MFS_CAN_RESControl 5000;
BA_ "InvalidValue" SG_ 1015 MFS_CAN_RESControl "3h";
BA_ "GenSigSendType" SG_ 1015 MFS_CruiseSpeedDecrease 4;
BA_ "GenSigTimeoutTime_ALL" SG_ 1015 MFS_CruiseSpeedDecrease 5000;
BA_ "InvalidValue" SG_ 1015 MFS_CruiseSpeedDecrease "4h";
BA_ "GenSigSendType" SG_ 1015 MFS_M2Control 4;
BA_ "GenSigTimeoutTime_ALL" SG_ 1015 MFS_M2Control 5000;
BA_ "InvalidValue" SG_ 1015 MFS_M2Control "3h";
BA_ "GenSigSendType" SG_ 1015 MFS_SourseControl 4;
BA_ "GenSigTimeoutTime_ALL" SG_ 1015 MFS_SourseControl 5000;
BA_ "InvalidValue" SG_ 1015 MFS_SourseControl "4h";
BA_ "GenSigSendType" SG_ 1015 MFS_UpControl 4;
BA_ "GenSigTimeoutTime_ALL" SG_ 1015 MFS_UpControl 5000;
BA_ "InvalidValue" SG_ 1015 MFS_UpControl "4h";
BA_ "GenSigSendType" SG_ 1015 MFS_DownControl 4;
BA_ "GenSigTimeoutTime_ALL" SG_ 1015 MFS_DownControl 5000;
BA_ "InvalidValue" SG_ 1015 MFS_DownControl "4h";
BA_ "GenSigSendType" SG_ 1015 MFS_LeftControl 4;
BA_ "GenSigTimeoutTime_ALL" SG_ 1015 MFS_LeftControl 5000;
BA_ "InvalidValue" SG_ 1015 MFS_LeftControl "4h";
BA_ "GenSigSendType" SG_ 1015 MFS_Failure 4;
BA_ "GenSigTimeoutTime_ALL" SG_ 1015 MFS_Failure 5000;
BA_ "InvalidValue" SG_ 1015 MFS_Failure "null";
BA_ "GenSigSendType" SG_ 1015 MFS_RightControl 4;
BA_ "GenSigTimeoutTime_ALL" SG_ 1015 MFS_RightControl 5000;
BA_ "InvalidValue" SG_ 1015 MFS_RightControl "4h";
BA_ "GenSigSendType" SG_ 1015 MFS_OK_Control 4;
BA_ "GenSigTimeoutTime_ALL" SG_ 1015 MFS_OK_Control 5000;
BA_ "InvalidValue" SG_ 1015 MFS_OK_Control "4h";
BA_ "GenSigTimeoutTime_ALL" SG_ 1020 CRC_XGW_FOTA_StsConfirm 2500;
BA_ "GenSigTimeoutTime_ALL" SG_ 1020 ALIV_XGW_FOTA_StsConfirm 2500;
BA_ "InvalidValue" SG_ 1020 ALIV_XGW_FOTA_StsConfirm "Fh";
BA_ "GenSigTimeoutTime_ALL" SG_ 1020 XGW_FOTA_StateConfirm 2500;
BA_ "GenSigTimeoutTime_ALL" SG_ 1020 XGW_FOTA_Error_Code 2500;
BA_ "GenSigSendType" SG_ 1025 MHU_SET_SunroofGlassLevel 2;
BA_ "GenSigStartValue" SG_ 1025 MHU_SET_SunroofGlassLevel 255;
BA_ "InvalidValue" SG_ 1025 MHU_SET_SunroofGlassLevel "7Fh";
BA_ "GenSigSendType" SG_ 1025 MHU_SET_BonnetState 2;
BA_ "InvalidValue" SG_ 1025 MHU_SET_BonnetState "3h";
BA_ "GenSigSendType" SG_ 1025 MHU_SET_TrunkState 2;
BA_ "InvalidValue" SG_ 1025 MHU_SET_TrunkState "3h";
BA_ "GenSigSendType" SG_ 1025 MHU_SET_SunroofShaderLevel 2;
BA_ "GenSigStartValue" SG_ 1025 MHU_SET_SunroofShaderLevel 255;
BA_ "InvalidValue" SG_ 1025 MHU_SET_SunroofShaderLevel "7Fh";
BA_ "GenSigSendType" SG_ 1025 MHU_SET_DoorSpeedLock 2;
BA_ "GenSigStartValue" SG_ 1025 MHU_SET_DoorSpeedLock 6;
BA_ "InvalidValue" SG_ 1025 MHU_SET_DoorSpeedLock "6h";
BA_ "GenSigSendType" SG_ 1025 MHU_SET_WelcomeTriggerCondition 2;
BA_ "GenSigStartValue" SG_ 1025 MHU_SET_WelcomeTriggerCondition 3;
BA_ "InvalidValue" SG_ 1025 MHU_SET_WelcomeTriggerCondition "3h";
BA_ "GenSigSendType" SG_ 1025 MHU_SET_AutoSunroof 2;
BA_ "GenSigStartValue" SG_ 1025 MHU_SET_AutoSunroof 3;
BA_ "InvalidValue" SG_ 1025 MHU_SET_AutoSunroof "3h";
BA_ "GenSigSendType" SG_ 1025 MHU_SET_RemoteDoorUnlock 2;
BA_ "GenSigStartValue" SG_ 1025 MHU_SET_RemoteDoorUnlock 3;
BA_ "InvalidValue" SG_ 1025 MHU_SET_RemoteDoorUnlock "3h";
BA_ "GenSigSendType" SG_ 1025 MHU_SET_RemoteLockFeedback 2;
BA_ "GenSigStartValue" SG_ 1025 MHU_SET_RemoteLockFeedback 4;
BA_ "InvalidValue" SG_ 1025 MHU_SET_RemoteLockFeedback "4h";
BA_ "GenSigSendType" SG_ 1025 MHU_SET_FootkickSensor 2;
BA_ "GenSigStartValue" SG_ 1025 MHU_SET_FootkickSensor 3;
BA_ "InvalidValue" SG_ 1025 MHU_SET_FootkickSensor "3h";
BA_ "GenSigSendType" SG_ 1025 MHU_SET_AutoUnlockDoor 2;
BA_ "GenSigStartValue" SG_ 1025 MHU_SET_AutoUnlockDoor 3;
BA_ "InvalidValue" SG_ 1025 MHU_SET_AutoUnlockDoor "3h";
BA_ "GenSigSendType" SG_ 1025 MHU_SET_RemoteUnlockFeedback 2;
BA_ "GenSigStartValue" SG_ 1025 MHU_SET_RemoteUnlockFeedback 4;
BA_ "InvalidValue" SG_ 1025 MHU_SET_RemoteUnlockFeedback "4h";
BA_ "GenSigSendType" SG_ 1025 MHU_SET_Childlock 2;
BA_ "InvalidValue" SG_ 1025 MHU_SET_Childlock "null";
BA_ "GenSigSendType" SG_ 1025 MHU_SET_SunroofInitialize 2;
BA_ "InvalidValue" SG_ 1025 MHU_SET_SunroofInitialize "7h";
BA_ "GenSigSendType" SG_ 1025 WalkawayDoorLock 2;
BA_ "GenSigSendType" SG_ 1026 MHU_SET_DayTimeRunningLight 2;
BA_ "GenSigStartValue" SG_ 1026 MHU_SET_DayTimeRunningLight 1;
BA_ "InvalidValue" SG_ 1026 MHU_SET_DayTimeRunningLight "3h";
BA_ "GenSigSendType" SG_ 1026 MHU_SET_RearFogLight 2;
BA_ "GenSigStartValue" SG_ 1026 MHU_SET_RearFogLight 3;
BA_ "InvalidValue" SG_ 1026 MHU_SET_RearFogLight "3h";
BA_ "GenSigSendType" SG_ 1026 MHU_SET_FrontFogLight 2;
BA_ "GenSigStartValue" SG_ 1026 MHU_SET_FrontFogLight 3;
BA_ "InvalidValue" SG_ 1026 MHU_SET_FrontFogLight "3h";
BA_ "GenSigSendType" SG_ 1026 MHU_SET_WelcomeDimmingHeadlight 2;
BA_ "GenSigStartValue" SG_ 1026 MHU_SET_WelcomeDimmingHeadlight 3;
BA_ "InvalidValue" SG_ 1026 MHU_SET_WelcomeDimmingHeadlight "3h";
BA_ "GenSigSendType" SG_ 1026 MHU_SET_AmbientLightBrighness 2;
BA_ "InvalidValue" SG_ 1026 MHU_SET_AmbientLightBrighness "7Fh";
BA_ "GenSigSendType" SG_ 1026 MHU_SET_FootwellLightMode 2;
BA_ "GenSigStartValue" SG_ 1026 MHU_SET_FootwellLightMode 2;
BA_ "InvalidValue" SG_ 1026 MHU_SET_FootwellLightMode "3h";
BA_ "GenSigSendType" SG_ 1026 MHU_SET_ExteriorLight 2;
BA_ "GenSigStartValue" SG_ 1026 MHU_SET_ExteriorLight 4;
BA_ "InvalidValue" SG_ 1026 MHU_SET_ExteriorLight "4h";
BA_ "GenSigSendType" SG_ 1026 MHU_SET_TRWarningSignals 2;
BA_ "GenSigStartValue" SG_ 1026 MHU_SET_TRWarningSignals 3;
BA_ "InvalidValue" SG_ 1026 MHU_SET_TRWarningSignals "3h";
BA_ "GenSigSendType" SG_ 1026 MHU_SET_FrontDomeLamp 2;
BA_ "GenSigStartValue" SG_ 1026 MHU_SET_FrontDomeLamp 3;
BA_ "InvalidValue" SG_ 1026 MHU_SET_FrontDomeLamp "3h";
BA_ "GenSigSendType" SG_ 1026 MHU_SET_SwitchLightBrightness 2;
BA_ "GenSigStartValue" SG_ 1026 MHU_SET_SwitchLightBrightness 80;
BA_ "InvalidValue" SG_ 1026 MHU_SET_SwitchLightBrightness "4h";
BA_ "GenSigSendType" SG_ 1026 MHU_SET_HazardLight 2;
BA_ "InvalidValue" SG_ 1026 MHU_SET_HazardLight "3h";
BA_ "GenSigTimeoutTime_ALL" SG_ 1026 MHU_SET_HazardLight 500;
BA_ "GenSigSendType" SG_ 1026 MHU_SET_FollowMeHome 2;
BA_ "InvalidValue" SG_ 1026 MHU_SET_FollowMeHome "5h";
BA_ "GenSigSendType" SG_ 1026 MHU_SET_ADB_AHB 2;
BA_ "InvalidValue" SG_ 1026 MHU_SET_ADB_AHB "3h";
BA_ "GenSigSendType" SG_ 1026 MHU_SET_WelcomeAnimation 2;
BA_ "InvalidValue" SG_ 1026 MHU_SET_WelcomeAnimation "null";
BA_ "GenSigSendType" SG_ 1026 MHU_SET_ChargingAnimation 2;
BA_ "GenSigStartValue" SG_ 1026 MHU_SET_ChargingAnimation 1;
BA_ "InvalidValue" SG_ 1026 MHU_SET_ChargingAnimation "3h";
BA_ "GenSigSendType" SG_ 1026 MHU_SET_Auto_Leveling 2;
BA_ "GenSigStartValue" SG_ 1026 MHU_SET_Auto_Leveling 1;
BA_ "InvalidValue" SG_ 1026 MHU_SET_Auto_Leveling "3h";
BA_ "GenSigTimeoutTime_ALL" SG_ 1027 CHKSM_MHU_EVSetting 500;
BA_ "InvalidValue" SG_ 1027 CHKSM_MHU_EVSetting "null";
BA_ "InvalidValue" SG_ 1027 MHU_AutoP_Setting "3h";
BA_ "GenSigStartValue" SG_ 1027 MHU_AutoP_Setting 2;
BA_ "GenSigTimeoutTime_ALL" SG_ 1027 MHU_AutoP_Setting 500;
BA_ "GenSigTimeoutTime_ALL" SG_ 1027 ALV_MHU_EVSetting 500;
BA_ "InvalidValue" SG_ 1027 ALV_MHU_EVSetting "Fh";
BA_ "GenSigTimeoutTime_ALL" SG_ 1027 MHU_VCU_CreepDisable_stt 500;
BA_ "InvalidValue" SG_ 1027 MHU_VCU_CreepDisable_stt "null";
BA_ "GenSigTimeoutTime_ALL" SG_ 1027 MHU_BrakeRegenMode 500;
BA_ "InvalidValue" SG_ 1027 MHU_BrakeRegenMode "";
BA_ "GenSigStartValue" SG_ 1027 MHU_ChargeSetTargetSOC 80;
BA_ "GenSigTimeoutTime_ALL" SG_ 1027 MHU_ChargeSetTargetSOC 500;
BA_ "InvalidValue" SG_ 1027 MHU_ChargeSetTargetSOC "7Fh";
BA_ "GenSigStartValue" SG_ 1027 MHU_ChargeScheduleSet 2;
BA_ "GenSigTimeoutTime_ALL" SG_ 1027 MHU_ChargeScheduleSet 500;
BA_ "InvalidValue" SG_ 1027 MHU_ChargeScheduleSet "3h";
BA_ "GenSigStartValue" SG_ 1027 MHU_ChargingRequest 3;
BA_ "GenSigTimeoutTime_ALL" SG_ 1027 MHU_ChargingRequest 500;
BA_ "InvalidValue" SG_ 1027 MHU_ChargingRequest "null";
BA_ "GenSigTimeoutTime_ALL" SG_ 1027 MHU_ChgPort_Open_req 500;
BA_ "InvalidValue" SG_ 1027 MHU_ChgPort_Open_req "3h";
BA_ "GenSigStartValue" SG_ 1027 MHU_SET_DrivingModeSwitch 3;
BA_ "GenSigTimeoutTime_ALL" SG_ 1027 MHU_SET_DrivingModeSwitch 500;
BA_ "InvalidValue" SG_ 1027 MHU_SET_DrivingModeSwitch "3h";
BA_ "GenSigStartValue" SG_ 1027 MHU_ValetMode_Activation 2;
BA_ "GenSigTimeoutTime_ALL" SG_ 1027 MHU_ValetMode_Activation 500;
BA_ "InvalidValue" SG_ 1027 MHU_ValetMode_Activation "FFh";
BA_ "GenSigStartValue" SG_ 1027 MHU_ValetMode_MaxSpeed 255;
BA_ "GenSigTimeoutTime_ALL" SG_ 1027 MHU_ValetMode_MaxSpeed 500;
BA_ "InvalidValue" SG_ 1027 MHU_ValetMode_MaxSpeed "FFh";
BA_ "GenSigStartValue" SG_ 1027 MHU_ChargingCurrentLimit 6;
BA_ "GenSigTimeoutTime_ALL" SG_ 1027 MHU_ChargingCurrentLimit 500;
BA_ "InvalidValue" SG_ 1027 MHU_ChargingCurrentLimit "3Fh";
BA_ "GenSigTimeoutTime_ALL" SG_ 1027 MHU_SET_ActivePreCondition 500;
BA_ "InvalidValue" SG_ 1027 MHU_SET_ActivePreCondition "3h";
BA_ "GenSigTimeoutTime_ALL" SG_ 1027 MHU_SpdLim_Override 500;
BA_ "GenSigSendType" SG_ 1028 MHU_SET_LeftMirrorPosX 2;
BA_ "GenSigStartValue" SG_ 1028 MHU_SET_LeftMirrorPosX 15;
BA_ "InvalidValue" SG_ 1028 MHU_SET_LeftMirrorPosX "FFh";
BA_ "GenSigSendType" SG_ 1028 MHU_SET_LeftMirrorPosY 2;
BA_ "GenSigStartValue" SG_ 1028 MHU_SET_LeftMirrorPosY 15;
BA_ "InvalidValue" SG_ 1028 MHU_SET_LeftMirrorPosY "FFh";
BA_ "GenSigSendType" SG_ 1028 MHU_SET_RightMirrorPosX 2;
BA_ "GenSigStartValue" SG_ 1028 MHU_SET_RightMirrorPosX 15;
BA_ "InvalidValue" SG_ 1028 MHU_SET_RightMirrorPosX "FFh";
BA_ "GenSigSendType" SG_ 1028 MHU_SET_RightMirrorPosY 2;
BA_ "GenSigStartValue" SG_ 1028 MHU_SET_RightMirrorPosY 15;
BA_ "InvalidValue" SG_ 1028 MHU_SET_RightMirrorPosY "FFh";
BA_ "GenSigSendType" SG_ 1028 MHU_SET_MirrorAdjustLeft 2;
BA_ "InvalidValue" SG_ 1028 MHU_SET_MirrorAdjustLeft "3h";
BA_ "GenSigSendType" SG_ 1028 MHU_SET_MirrorAdjustRight 2;
BA_ "InvalidValue" SG_ 1028 MHU_SET_MirrorAdjustRight "3h";
BA_ "GenSigSendType" SG_ 1028 MHU_SET_MirrorManual 2;
BA_ "GenSigStartValue" SG_ 1028 MHU_SET_MirrorManual 3;
BA_ "InvalidValue" SG_ 1028 MHU_SET_MirrorManual "3h";
BA_ "GenSigSendType" SG_ 1028 SECCAN_MirrorAdj 2;
BA_ "InvalidValue" SG_ 1028 SECCAN_MirrorAdj "null";
BA_ "GenSigSendType" SG_ 1029 MHU_SET_CCUF_AirCondition 2;
BA_ "InvalidValue" SG_ 1029 MHU_SET_CCUF_AirCondition "3h";
BA_ "GenSigSendType" SG_ 1029 MHU_SET_CCUF_AutoAC 2;
BA_ "InvalidValue" SG_ 1029 MHU_SET_CCUF_AutoAC "3h";
BA_ "GenSigSendType" SG_ 1029 MHU_SET_CCUF_MaxAc 2;
BA_ "InvalidValue" SG_ 1029 MHU_SET_CCUF_MaxAc "3h";
BA_ "GenSigSendType" SG_ 1029 MHU_SET_CCUF_FanSpeed 2;
BA_ "GenSigStartValue" SG_ 1029 MHU_SET_CCUF_FanSpeed 3;
BA_ "InvalidValue" SG_ 1029 MHU_SET_CCUF_FanSpeed "7h";
BA_ "GenSigSendType" SG_ 1029 MHU_SET_CCUF_Recirculation 2;
BA_ "GenSigStartValue" SG_ 1029 MHU_SET_CCUF_Recirculation 1;
BA_ "InvalidValue" SG_ 1029 MHU_SET_CCUF_Recirculation "3h";
BA_ "GenSigSendType" SG_ 1029 MHU_SET_CCUF_Ion 2;
BA_ "InvalidValue" SG_ 1029 MHU_SET_CCUF_Ion "3h";
BA_ "GenSigSendType" SG_ 1029 MHU_SET_CCUF_FlapPosition 2;
BA_ "InvalidValue" SG_ 1029 MHU_SET_CCUF_FlapPosition "4h";
BA_ "GenSigSendType" SG_ 1029 MHU_SET_CCUF_SyncClimateZone 2;
BA_ "InvalidValue" SG_ 1029 MHU_SET_CCUF_SyncClimateZone "3h";
BA_ "GenSigSendType" SG_ 1029 MHU_SET_CCUF_TempDriver 2;
BA_ "GenSigStartValue" SG_ 1029 MHU_SET_CCUF_TempDriver 40;
BA_ "InvalidValue" SG_ 1029 MHU_SET_CCUF_TempDriver "FFh";
BA_ "GenSigSendType" SG_ 1029 MHU_SET_CCUF_TempPassenger 2;
BA_ "GenSigStartValue" SG_ 1029 MHU_SET_CCUF_TempPassenger 40;
BA_ "InvalidValue" SG_ 1029 MHU_SET_CCUF_TempPassenger "FFh";
BA_ "GenSigSendType" SG_ 1029 MHU_SET_CCUF_FrontDefrost 2;
BA_ "InvalidValue" SG_ 1029 MHU_SET_CCUF_FrontDefrost "3h";
VAL_ 676 ECU_ID_WUPREG 255 "Signal invalid";
VAL_ 676 ID_FN_INQY 161 "Operation button Entertainment" 246 "Control exterior mirror" 426 "Effect ErgoCommander" 482 "Safe VIN" 525 "Position steering column" 550 "Rain sensor wiper speed" 570 "Status key" 594 "Wiper status" 615 "Operation pushbutton operating menu" 638 "Status soft top convertible" 742 "Status Climate Air distribution drivere" 746 "Status Climate Air distribution passenger" 748 "Status Climate " 750 "Status climate additional programs" 752 "Status Climate Stand functions" 759 "Unit" 760 "Time date" 768 "Status RSE" 783 "Status Service Call TeleX" 787 "Status Service Call Teleservice" 806 "Wirkungsgrad Information Data" 818 "Consumption information" 822 "Display checkcontrol message" 826 "Status Monitor Front" 828 "Status Monitor Rear 1" 830 "Status Monitor Rear 2" 833 "Status card data" 841 "Raw value fuel tank" 860 "Status Bordcomputer" 864 "Daten Bordcomputer 1" 896 "VIN" 897 "Electronic engine oil stick" 904 "vehicle type" 917 "Coding Powermanagement" 921 "Status M-Drive" 937 "Status ECM CKM" 939 "Status Shiftlights CKM" 950 "Position window regulator driver" 951 "Position window regulator driver rear" 952 "Position window regulator passenger" 953 "Position window regulator passenger rear" 954 "Position sliding roof" 956 "Position window lift sec" 959 "Position window lift tailgate" 960 "Configuration FAS" 961 "Configuration BFS" 962 "Configuration FASH" 963 "Configuration BFSH" 964 "Status EDCK CKM" 976 "Status lane departure warning system" 981 "Status cental lock" 983 "Status DWA CKM" 985 "Status RLS CKM" 987 "Status Memoryposition CKM" 989 "Status Light CKM" 991 "Status Climate CKM" 993 "Status ALC CKM" 995 "Status tailgateCKM" 1003 "Limits swing left" 1004 "Limits swing right" 1009 "Status light Extended  CKM" 1013 "Status of cargo compartment cover CKM" 1050 "Status Configuration IC 4" 1060 "Status Configuration IC" 1063 "Configuration DSC" 1070 "Status M-Drive 2" 1076 "Configuration EPS" 1077 "Measure engine oil" 1087 "Identification number Sensorcluster" 65535 "Signal invalid";
VAL_ 676 ID_FN_RQ_BUS 1 "Entertainment function" 2 "Remote Services" 3 "Residual heat function / burnout" 4 "Auxiliary heating/parking ventilation" 5 "Extension N-Holding Phase" 6 "Operation parking brake" 7 "Follow-up / connection RSE" 8 "Remote horn" 25 "Switch on / extension clamp" 43 "Alarm" 44 "EMF-button" 45 "roll monitoring" 46 "Requirement outside lighting" 47 "transhipment function" 51 "KL15Wup-Signal" 53 "Coolant temperature" 54 "IC display" 257 "switch on preventer" 258 "Wacke up " 259 "Switch OFF KL30F Stand time" 260 "Switch OFF KL30F CarSharing" 272 "OBD-Diagnostic" 273 "Exstension time water pump" 275 "Exstension time E-fan" 276 "Exstension time water pump additional Waterpumpe" 277 "Exstension time water pump hyb" 278 "Standl ventilation" 280 "Third-party charge detection hybrid / charging" 281 "Battery monitor  TSR" 288 "Leveling" 289 "Exstension time ventilation cooling" 304 "Trailer connection AAG" 305 "Req IK" 306 "Req IK OSFG" 513 "Domainmaster  ICE" 514 "Domainmaster elec motor" 515 "Domainmaster entertainment" 516 "Domainmaster body" 517 "Domainmaster Chasis" 769 "BDC Internal 30B Request inlight" 770 "BDC Internal 30B Request outlight" 771 "BDC Internal 30B Request FA-CAN " 772 "BDC Internal 30B Request Telesta" 773 "BDC Internal 30B Request Battery" 774 "CO2 Sensor" 65535 "Signal invalid";
VAL_ 676 NO_CC_MESS_STD 0 "No Error" 1 "Error(CurveBehavrestricted)" 2 "Error (Limited driving comfort)";
VAL_ 676 WACA 0 "ECU reset" 1 "Car alarm" 2 "Residual heat" 3 "CO2-recognition" 4 "CD/DVD Eject/CD/DVD insert" 5 "OFF switch light" 6 "Mirror" 7 "Remote Services" 8 "Emergency Call" 9 "CAS-Bus, button tailgate" 10 "CID-flap button" 11 "Smart Opener" 12 "Start charging" 14 "Switch for hitch" 16 "Door contact front driver" 17 "Door contact front passenger" 18 "Door contact front driver rear" 19 "Door contact front driver rear" 20 "Button driver door CA" 21 "Button passenger door CA" 22 "Button opener tailgate inner" 23 "Button opener tailgate" 24 "Button opener tailgate window" 25 "Tailgate contact" 26 "Input tailgate window" 27 "Bonnet" 28 "Unlock door lock / comfort opening" 29 "Lock door lock / comfort lock" 30 "Short circuit terminal 30 B" 32 "Start Stop button A" 33 "Start Stop button B" 34 "Hallsensor Eject" 35 "Center lock unlock" 36 "Park Automatic" 37 "Light swich ON" 38 "Hazard switch" 39 "Steering column switch to flash" 40 "Lenkstocktaster towards" 41 "Lenkstocktaster towards light" 42 "interior switch" 43 "Gear switch" 44 "EMF- Button" 45 "Entertainmen" 46 "Steering colunm adjustment switch" 47 "Regulation air spring" 48 "RKE" 49 "Wakeup-Signal TCU" 50 "Hotel switch" 51 "IBS" 52 "Parking heater / ventilate / climate" 53 "Coolant query by IC" 54 "Klemme 15 Wakeu line" 55 "Button Driver's door rear release" 56 "Button passenger door rear release" 57 "Button Driver's door" 58 "Button passenger door release" 59 "Button Driver's door rear release" 60 "Button passenger door rear release" 61 "Brake light switch" 62 "Clutch switch" 63 "Invalid wake-up reason, wake-up reason" 64 "Fog light" 65 "Rear fog light" 66 "Sarah- button" 67 "FES-button" 68 "PDC-button" 69 "Side-View-button" 70 "Rear spoiler-Taster" 71 "VDP-" 72 "MSA-button" 73 "Button audio volume steering wheel" 74 "Button special function" 75 "Button knurled steering wheel" 76 "Push-button telephone steering wheel" 77 "Push-button PTT steering wheel" 78 "Push-button seat heating driver" 79 "Push-button seat heating passenger" 80 "Push-button seat heating driver rear" 81 "Push-button seat heating passenger rear" 82 "Seat memory driver" 83 "Switch block door China long" 84 "Steering switch light" 85 "Door control unit" 88 "Car Sharing Modul" 89 "seat switch" 90 "AC control" 91 "PWF state change" 93 "Park light switch" 96 "Seat memory driver rear" 97 "Seat memory passenger" 98 "Seat memory pasenger rear" 99 "Nox-Diagnosis" 102 "Closing aid" 112 "Wake up" 255 "Signal invalid";
VAL_ 676 ST_CC_MESS_STD 0 "No Error" 1 "Error";
VAL_ 676 TRANF_CC_MESS_STD 0 "No Error" 1 "Error";
VAL_ 676 ST_IDC_CCLK_CC_MESS_STD 0 "No Error" 1 "Error";
VAL_ 714 MHU_STAT_CoolantLevelStatus 0 "Normal condition" 1 "Low level condition" 2 "Reserved" 3 "Signal Invalid";
VAL_ 720 FCAM_AESA_DoorUnlock_Req 0 "No request" 1 "Requested" ;
VAL_ 720 FCAM_AESA_ECALL_Req 0 "No request" 1 "Requested" ;
VAL_ 720 FCAM_AESA_Status 0 "Not active" 1 "Decelerating" 2 "Target following" 3 "Reserved" ;
VAL_ 753 MHU_STAT_AirbagWarnLamp 0 "Lamp off" 1 "Lamp on" 2 "Lamp failure" 3 "Signal invalid";
VAL_ 760 DISP_DATE_WDAY 1 "Monday" 2 "Tuesday" 3 "Wednesday" 4 "Thursday" 5 "Friday" 6 "Saturday" 7 "Sunday" 15 "Signal invalid";
VAL_ 760 ST_DISP_CTI_DATE 0 "data not valid" 1 "data valid" 3 "UTC" 5 "winter time" 6 "Manually set time" 7 "summer time" 15 "signal invalid";
VAL_ 768 CCU_STAT_SyncClimateZone 0 "OFF" 1 "ON" 2 "Reserved" 3 "Signal invalid";
VAL_ 768 CCU_STAT_Auto 0 "OFF" 1 "ON" 2 "Reserved" 3 "Signal invalid";
VAL_ 768 CCU_STAT_Aircondition 0 "OFF" 1 "ON" 2 "Reserved" 3 "Signal invalid";
VAL_ 768 CCU_STAT_IonButton 0 "OFF" 1 "ON" 2 "Reserved" 3 "Signal invalid";
VAL_ 768 CCU_STAT_MaxAc 0 "OFF" 1 "ON" 2 "Reserved" 3 "Signal invalid";
VAL_ 768 CCU_STAT_OnOff 0 "OFF" 1 "ON" 2 "Reserved" 3 "Signal invalid";
VAL_ 768 CCU_STAT_FanSpeed 0 "OFF" 1 "Level 1" 2 "Level 2" 3 "Level 3" 4 "Level 4" 5 "Level 5" 6 "Level 6" 7 "Reserved" 8 "Reserved" 9 "Reserved" 10 "Reserved" 11 "Reserved" 12 "Reserved" 13 "Reserved" 14 "Reserved" 15 "Signal invalid";
VAL_ 768 CCU_STAT_RecircFlap 0 "Inside" 1 "Outside" 2 "Auto" 3 "Signal invalid";
VAL_ 768 CCU_STAT_FlapPos 0 "OFF" 1 "Vent" 2 "Vent/Foot" 3 "Foot" 4 "Foot/Defrost" 5 "Defrost" 6 "Default" 7 "Signal invalid";
VAL_ 768 CCU_STAT_Defrost 0 "OFF" 1 "ON" 2 "Reserved" 3 "Signal invalid";
VAL_ 768 CCU_STAT_PTC_Heater 0 "OFF" 1 "Stage 1" 2 "Stage 2" 3 "Stage 3" 4 "Reserved" 5 "Reserved" 6 "Reserved" 7 "Signal invalid";
VAL_ 769 RP_ReqInfoDispTxt2 0 "No request" 1 "The door is open, please close the door" 2 "The front hatch door is open, please close the door" 3 "The tailgate is open, please close the door" 4 "RP parking assist system failure, parking exit" 5 "RP related actuator failure, parking exit" 6 "Control distance exceeds the limit, parking exit" 7 "The gear is not in the P gear, the RP cannot be opened, and the system exits" 8 "The gear is not in the P gear, please put the gear into P" 9 "The slope is too large to activate the parking function" 10 "The tire pressure is low and does not meet the parking requirements" 11 "SM related actuator failure, parking exit" 12 "SM parking assist system failure, parking exit";
VAL_ 769 RP_Status 0 "Off" 1 "Standby" 2 "Enable" 3 "Active" 4 "Finished" 5 "Suspend" 6 "Abort" 7 "Failed";
VAL_ 769 ADAS_TboxAuthStatus 0 "Have not learn. Not allow action" 1 "PASSED" 2 "FALIED: Authentication fail" 3 "Invalid";
VAL_ 769 RP_ReqInfoDispTxt1 0 "No request" 1 "Timeout" 2 "gear intervention" 3 "throttle intervention" 4 "steering wheel intervention" 5 "Electronic handbrake invnt" 6 "Door is opened" 7 "parking times exceeds the limit" 8 "The road slope is too big" 9 "resumable interrupt exceeds li" 10 "Associated ECU failure" 11 "Parking speed exceeds limit" 12 "Parking system failure" 13 "gear can't be switched normal" 14 "driver takes initiative to ex" 15 "vehicle cannot move" 16 "When an obstacle is detected" 17 "driver's seat belt is loosened" 18 "Contrl dist about to excd limit" 19 "parking space is limited" 20 "tailgate is opened" 21 "Reserved" 22 "Reserved" 23 "front hatch door is opened" 24 "Parking is completed" 25 "Parking failed" 26 "Remote connection is interrupted" 27 "pull up the EPB get off" 28 "Remote parking has started" 29 "slope large to contin park func" 30 "SM has started" 31 "collision happens";
VAL_ 773 BMS_VCU_Insulation_Mon_Sts 0 "ON" 1 "OFF";
VAL_ 775 OUT_Alert_TO_BCM 0 "Init" 1 "Warning level 1" 2 "Warning level 2" 3 "Warning level 3" 4 "Deactivate Warning" 5 "Invalid Value";
VAL_ 775 CPD_State_information 0 "Enable" 1 "Disable" 2 "Child Mode" 3 "Pet Mode" 4 "Reserved" 5 "Reserved" 6 "Reserved" 7 "Reserved";
VAL_ 775 OUT_Alert_TO_MHU 0 "Init" 1 "Default Warning" 2 "Warning on MHU" 3 "Warning Outside (Send SMS)" 4 "Deactivate Warning";
VAL_ 776 MHU_CPD_Setting 0 "Enable" 1 "Disable" 2 "Child Mode" 3 "Delay CPD" 4 " Reserved" 5 " Reserved" 6 " Reserved" 7 " Reserved";
VAL_ 776 MHU_CPD_Confirmation_On_HMI 0 "No confirmation" 1 "User confirmation" 2 "Reserved" 3 "Reserved" 4 " Reserved" 5 " Reserved" 6 " Reserved" 7 " Reserved";
VAL_ 784 CCUR_STAT_IonButton 0 "OFF" 1 "ON" 2 "Reserved" 3 "Signal invalid";
VAL_ 784 CCUR_STAT_Defrost 0 "OFF" 1 "ON" 2 "Reserved" 3 "Signal invalid";
VAL_ 784 CCUR_STAT_Auto 0 "OFF" 1 "ON" 2 "Reserved" 3 "Signal invalid";
VAL_ 784 CCUR_STAT_Aircondition 0 "OFF" 1 "ON" 2 "Reserved" 3 "Signal invalid";
VAL_ 784 CCUR_STAT_FlapPos 0 "OFF" 1 "Vent" 2 "Vent/Foot" 3 "Foot" 4 "Foot/Defrost" 5 "Defrost" 6 "Default" 7 "Signal invalid";
VAL_ 784 CCUR_STAT_FanSpeed 0 "OFF" 1 "Level 1" 2 "Level 2" 3 "Level 3" 4 "Level 4" 5 "Level 5" 6 "Level 6" 7 "Reserved" 8 "Reserved" 9 "Reserved" 10 "Reserved" 11 "Reserved" 12 "Reserved" 13 "Reserved" 14 "Reserved" 15 "Signal invalid";
VAL_ 784 CCUR_STAT_PTC_Heater 0 "OFF" 1 "Stage 1" 2 "Stage 2" 3 "Stage 3" 4 "Reserved" 5 "Reserved" 6 "Reserved" 7 "Signal invalid";
VAL_ 784 CCUR_STAT_OnOff 0 "OFF" 1 "ON" 2 "Reserved" 3 "Signal invalid";
VAL_ 784 CCUR_STAT_MaxAc 0 "OFF" 1 "ON" 2 "Reserved" 3 "Signal invalid";
VAL_ 784 CCUR_STAT_SyncClimateZone 0 "OFF" 1 "ON" 2 "Reserved" 3 "Signal invalid";
VAL_ 784 CCUR_STAT_RecircFlap 0 "Inside" 1 "Outside" 2 "Auto" 3 "Signal invalid";
VAL_ 771 MHU_AVM_CurbViewReq 0 "No Request" 1 "On" 2 "Off" 3 "SNA" ;
VAL_ 771 HU_SVS_TransparentModel_Req 0 "No Command" 1 "ON" 2 "OFF" 3 "SNA" ;
VAL_ 771 HU_SVSObjOverlay 0 "No Request" 1 "On" 2 "Off" 3 "SNA" ;
VAL_ 771 MHU_AVM_DynamiclineReq 0 "No Request" 1 "On" 2 "Off" 3 "SNA" ;
VAL_ 771 HU_3D_SVS_ReqFromHU 0 "No Command" 1 "3D View" 2 "2D View" 3 "SNA" ;
VAL_ 771 MHU_AVM_ShowAPAReq 0 "No Request" 1 "Request APA on" 2 "Request APA off" 3 "Request APA Pause" ;
VAL_ 771 MHU_AVM_BmprViewReq 0 "No Request" 1 "On" 2 "Off" 3 "SNA" ;
VAL_ 771 HU_SVSManVidSetupReqFromHU 0 "No request" 1 "Front View" 2 "Rear View" 3 "Front Junction View" 4 "Rear Junction View" 5 "Left curb view" 6 "Right Curb view" 7 "Front Clear View" 8 "Trailer Mode View" 9 "Rear Clear view" 10 "Rear right view" 11 "Front Bumper View" 12 "Rear Bumper View" 13 "360 Rotation View" 14 "Front Wheel View" 15 "Rear Wheel View" ;
VAL_ 771 HU_3D_SVS_ViewChgReqFromHU 0 "No command" 1 "Front view" 2 "Front left view" 3 "Left view" 4 "Rear left view" 5 "Rear view" 6 "Rear right view" 7 "Right view" 8 "Front right view" 9 "Reserved" 10 "Reserved" 11 "Reserved" 12 "Reserved" 13 "Reserved" 14 "Reserved" 15 "Invalid" ;
VAL_ 787 POD_statusOBC 0 "OBC_OFF" 1 "OBC_STANDBY" 2 "OBC_ON_NORMAL" 3 "OBC_ON_VOLTAGE" 4 "OBC_DEGRADED" 5 "OBC_FAULT_SHUTDOWN" 6 "OBC_EMERGENCY_SHUTDOWN" 7 "OBC_STS_SNA";
VAL_ 803 POD_phaseACInput 0 "Not Used" 1 "AC 1 phase input" 2 "Not used" 3 "AC 3 phase input";
VAL_ 804 Steering_HeatingControl 0 "Disable" 1 "Enable";
VAL_ 805 Steering_HeatingControlFdbk 0 "Disable" 1 "Enable" 2 "Error";
VAL_ 806 POD_statusDCDC 0 "DCDC_OFF" 1 "DCDC_STANDBY" 2 "DCDC_ON" 3 "DCDC_RESERVED" 4 "DCDC_DEGRADED" 5 "DCDC_FAULT_SHUTDOWN" 6 "DCDC_EMERGENCY_SHUTDOWN" 7 "DCDC_STS_SNA";
VAL_ 807 POD_statusFCContactors 0 "FC_CONTACTORS_OPEN" 1 "FC_CONTACTORS_CLOSING" 2 "FC_CONTACTRORS_CLOSED" 3 "FC_CONTACTORS_OPENING" 4 "FC_CONTACTORS_WELDED" 5 "FC_CONTACTORS_FAULT" 7 "FC_CONTACTORS_SNA";
VAL_ 816 ST_FLLV_FUTA_SPAR 0 "No active" 1 "Active" 2 "Reserved" 3 "Signal invalid";
VAL_ 819 Rolling_Counter_0x333 15 "Invalid";
VAL_ 819 ADAS_RadarRight_Cal_Status 0 "No Calib" 1 "Calib OK";
VAL_ 819 ADAS_RadarLeft_Cal_Status 0 "No Calib" 1 "Calib OK";
VAL_ 819 ADAS_RadarRight_DynaCal_Status 0 "Calibration is in progress" 1 "The absolute value of calibration angle is greater than 6 degrees";
VAL_ 819 ADAS_MasterSRR_check 0 "Available" 1 "Temporarily not available" 2 "Permanently not available";
VAL_ 819 ADAS_SlaveSRR_check 0 "Available" 1 "Temporarily not available" 2 "Permanently not available";
VAL_ 819 ADAS_RadarLeft_DynaCal_Status 0 "Calibration is in progress" 1 "The absolute value of calibration angle is greater than 6 degrees";
VAL_ 819 ADAS_CalSensorMasterProgress 255 "Invaild";
VAL_ 819 ADAS_CalSensorSlaverProgress 255 "Invalid";
VAL_ 827 Camera_R1_Line_Type 0 "No display" 1 "solid line" 2 "dashed line" 3 "Roadside";
VAL_ 827 Camera_L1_Line_Type 0 "No display" 1 "Solid line" 2 "Dashed line" 3 "Roadside";
VAL_ 833 ADAS_OBJ01_Class 0 "Unknown" 1 "Car" 2 "Truck" 3 "Motorbike" 4 "bicycle" 5 "Pedestrian" 6 "truck or car" 7 "reserved";
VAL_ 833 ADAS_OBJ01_Lane 0 "Undefined" 1 "Left lane" 2 "Host lane" 3 "Right lane";
VAL_ 835 ADAS_OBJ02_Class 0 "Unknown" 1 "Car" 2 "Truck" 3 "Motorbike" 4 "bicycle" 5 "Pedestrian" 6 "truck or car" 7 "reserved";
VAL_ 835 ADAS_OBJ02_Lane 0 "Undefined" 1 "Left lane" 2 "Host lane" 3 "Right lane";
VAL_ 840 EDS_HVIL_STS_FWD 0 "Closed" 1 "Open" 2 "short to battery" 3 "short to ground";
VAL_ 841 EDS_HVIL_STS_RWD 0 "Closed" 1 "Open" 2 "short to battery" 3 "short to ground";
VAL_ 842 ADAS_OBJ03_Class 0 "Unknown" 1 "Car" 2 "Truck" 3 "Motorbike" 4 "bicycle" 5 "Pedestrian" 6 "truck or car" 7 "reserved";
VAL_ 842 ADAS_OBJ03_Lane 0 "Undefined" 1 "Left lane" 2 "Host lane" 3 "Right lane";
VAL_ 844 ADAS_OBJ04_Class 0 "Unknown" 1 "Car" 2 "Truck" 3 "Motorbike" 4 "bicycle" 5 "Pedestrian" 6 "truck or car" 7 "reserved";
VAL_ 844 ADAS_OBJ04_Lane 0 "Undefined" 1 "Left lane" 2 "Host lane" 3 "Right lane";
VAL_ 845 ADAS_OBJ05_Class 0 "Unknown" 1 "Car" 2 "Truck" 3 "Motorbike" 4 "bicycle" 5 "Pedestrian" 6 "truck or car" 7 "reserved";
VAL_ 845 ADAS_OBJ05_Lane 0 "Undefined" 1 "Left lane" 2 "Host lane" 3 "Right lane";
VAL_ 846 ADAS_OBJ06_Class 0 "Unknown" 1 "Car" 2 "Truck" 3 "Motorbike" 4 "bicycle" 5 "Pedestrian" 6 "truck or car" 7 "reserved";
VAL_ 846 ADAS_OBJ06_Lane 0 "Undefined" 1 "Left lane" 2 "Host lane" 3 "Right lane";
VAL_ 849 ADAS_PA_AutoOn_Feed 0 "Off" 1 "On";
VAL_ 849 ADAS_PA_AlertFRI 0 "Off" 1 "1st warning" 2 "2nd warning" 3 "3rd warning" 4 "4th warning" 5 "5th warning" 6 "Reserved" 7 "Error";
VAL_ 849 ADAS_PA_AlertFLI 0 "Off" 1 "1st warning" 2 "2nd warning" 3 "3rd warning" 4 "4th warning" 5 "5th warning" 6 "Reserved" 7 "Error";
VAL_ 849 ADAS_PA_AlertFLO 0 "Off" 1 "1st warning" 2 "2nd warning" 3 "3rd warning" 4 "4th warning" 5 "5th warning" 6 "Reserved" 7 "Error";
VAL_ 849 ADAS_PA_AlertRLO 0 "Off" 1 "1st warning" 2 "2nd warning" 3 "3rd warning" 4 "4th warning" 5 "5th warning" 6 "Reserved" 7 "Error";
VAL_ 849 ADAS_PA_AlertRLI 0 "Off" 1 "1st warning" 2 "2nd warning" 3 "3rd warning" 4 "4th warning" 5 "5th warning" 6 "Reserved" 7 "Error";
VAL_ 849 ADAS_PA_AlertFRO 0 "Off" 1 "1st warning" 2 "2nd warning" 3 "3rd warning" 4 "4th warning" 5 "5th warning" 6 "Reserved" 7 "Error";
VAL_ 849 ADAS_PA_AlertRRO 0 "Off" 1 "1st warning" 2 "2nd warning" 3 "3rd warning" 4 "4th warning" 5 "5th warning" 6 "Reserved" 7 "Error";
VAL_ 849 ADAS_PA_AlertRRI 0 "Off" 1 "1st warning" 2 "2nd warning" 3 "3rd warning" 4 "4th warning" 5 "5th warning" 6 "Reserved" 7 "Error";
VAL_ 849 ADAS_PA_AlertFLS 0 "Off" 1 "1st warning" 2 "2nd warning" 3 "3rd warning" 4 "4th warning" 5 "5th warning" 6 "Reserved" 7 "Error" ;
VAL_ 849 ADAS_PA_state 0 "OFF State" 1 "Stand by state" 2 "Active state" 3 "Failed state" ;
VAL_ 849 ADAS_PA_AlertFRS 0 "Off" 1 "1st warning" 2 "2nd warning" 3 "3rd warning" 4 "4th warning" 5 "5th warning" 6 "Reserved" 7 "Error" ;
VAL_ 849 ADAS_PA_AlertRLS 0 "Off" 1 "1st warning" 2 "2nd warning" 3 "3rd warning" 4 "4th warning" 5 "5th warning" 6 "Reserved" 7 "Error" ;
VAL_ 849 ADAS_PA_AlertRRS 0 "Off" 1 "1st warning" 2 "2nd warning" 3 "3rd warning" 4 "4th warning" 5 "5th warning" 6 "Reserved" 7 "Error" ;
VAL_ 850 ADAS_AHB_sens_Feed 0 "Early" 1 "Normal" 2 "Late" 3 "reserved";
VAL_ 850 ADAS_AHB_Mode_Feed 0 "Off" 1 "On";
VAL_ 850 ADAS_AHB_check 0 "Available" 1 "Temporarily not available" 2 "Permanently not available";
VAL_ 850 ADAS_AHB_state 0 "OFF State" 1 "HighBeam Passive or Inactive" 2 "HighBeam Active" 3 "Fault";
VAL_ 850 ADAS_DOW_WarnRight 0 "No warning" 1 "Warning Level 1" 2 "Warning Level 2" 3 "Reserved";
VAL_ 850 ADAS_DOW_SndWarn 0 "Sound Warning disable" 1 "Left Sound Warning enable" 2 "Right Sound Warning enable" 3 "Left and Right Sound Warning enable";
VAL_ 850 ADAS_DOW_state 0 "OFF State" 1 "Stand by state" 2 "Armed state" 3 "Warning stage" 4 "Malfunction stage";
VAL_ 850 ADAS_DOW_check 0 "Available" 1 "Temporarily not available" 2 "Permanently not available";
VAL_ 850 ADAS_DOW_WarnLeft 0 "No warning" 1 "Warning Level 1" 2 "Warning Level 2" 3 "Reserved";
VAL_ 850 ADAS_DOW_Mode_Feed 0 "Off" 1 "Warning Only" 2 "Warning/Door Lock both" 3 "Reserved";
VAL_ 850 ADAS_AHB_RBPos 0 "Off or low beam" 1 "high beam" 2 "Reserved" 3 "Reserved" 4 "Reserved" 5 "Reserved" 6 "Reserved" 7 "SNA";
VAL_ 850 ADAS_AHB_LBPos 0 "Off or low beam" 1 "high beam" 2 "Reserved" 3 "Reserved" 4 "Reserved" 5 "Reserved" 6 "Reserved" 7 "SNA";
VAL_ 851 ADAS_ACC_ObjDetec 0 "Lead Object Not detected" 1 "Lead Object detected";
VAL_ 851 ADAS_ISA_check 0 "Available" 1 "Temporarily not available" 2 "Permanently not available";
VAL_ 851 ADAS_ISA_Mode_SW_Feed 0 "Off" 1 "On";
VAL_ 851 ADAS_TagSpeed_ICON_Feed 0 "Off" 1 "Gray ICON" 2 "Green ICON" 3 "White ICON" 4 "Yellow ICON" 5 "Red ICON";
VAL_ 851 ADAS_ISA_PopUp_Feed 0 "-" 1 "Accelerating to match speed limit" 2 "Decelerating to match speed limit" 3 "Press steering wheel button to match speed limit" 4 "Intelligent Speed Assist Unavailable" 5 "Reserved" 6 "Reserved" 7 "Reserved" 8 "Reserved" 9 "Reserved" 10 "Reserved" 11 "Reserved" 12 "Reserved" 13 "Reserved" 14 "Reserved" 15 "Invalid";
VAL_ 851 ADAS_ISA_Btn_Feed 0 "Off" 1 "On";
VAL_ 851 ADAS_ACC_DistSet_upper_Feed 0 "-" 1 "Up_Feed";
VAL_ 851 ADAS_ACC_TimeGapSet 0 "No time gap" 1 "1st level distance" 2 "2nd level distance" 3 "3rd level distance" 4 "4th level distance" 5 "Reserved" 6 "Reserved";
VAL_ 851 ADAS_ACC_State 0 "OFF State or Passive" 1 "Stand by state" 2 "Active" 3 "Override" 4 "Brake Only" 5 "Standstill Active" 6 "Standstill Wait" 7 "Fault";
VAL_ 851 ADAS_ACC_PopUp_Feed 0 "-" 1 "None (Feature On)" 2 "None (Feature Off)" 3 "Press gas pedal to re-engage the function" 4 "Speed Assist is unavailable Conditions not met" 5 "Resume not available Please activate Speed Assist button" 6 "Speed Assist is unavailable See Fault Details for more ingo" 7 "Speed Assist will off below 20kph. Issue with vehicle sensors" 8 "Take over driving now!" 9 "Take over driving now!Speed Assist Off" 10 "Take Over Driving , ACC Overspeed Occur!" ;
VAL_ 851 ADAS_ACC_check 0 "Available" 1 "Temporarily not available" 2 "Permanently not available";
VAL_ 851 ADAS_ISA_ICON_Feed 0 "Off" 1 "Gray ICON" 2 "Green ICON" 3 "White ICON" 4 "Yellow ICON" 5 "Red ICON";
VAL_ 851 ADAS_ACC_DistSet_lower_Feed 0 "-" 1 "Down_Feed";
VAL_ 851 ADAS_ACC_SpdSet_upper_Feed 0 "-" 1 "Up_Feed";
VAL_ 851 ADAS_ACC_SpdSet_lower_Feed 0 "-" 1 "Down_Feed";
VAL_ 851 ADAS_ACC_On_Feed 0 "Off" 1 "On";
VAL_ 851 ADAS_ACC_Set_Feed 0 "-" 1 "Set_Feed";
VAL_ 851 ADAS_ACC_CnlBtn_Feed 0 "-" 1 "Cancel_Feed";
VAL_ 851 ADAS_ACC_Res_Feed 0 "-" 1 "Res_Feed";
VAL_ 851 ADAS_ACC_ICON_Feed 0 "Off" 1 "Gray ICON" 2 "Green ICON" 3 "White ICON" 4 "Yellow ICON" 5 "Red ICON";
VAL_ 851 ADAS_ISA_Status 0 "OFF State" 1 "Stand by state" 2 "Active(Auto) state" 3 "Reserved" 4 "Reserved";
VAL_ 852 MHU_FCW_Mode 0 "OFF" 1 "ON" 2 "Reserve" 3 "Signal invalid";
VAL_ 852 MHU_FCW_sens 0 "Early" 1 "Normal" 2 "Late" 3 "Signal invalid";
VAL_ 852 MHU_AEB_Mode 0 "OFF" 1 "ON" 2 "Reserved" 3 "Signal invalid";
VAL_ 852 MHU_RAEB_Mode 0 "OFF" 1 "ON" 2 "Reserved" 3 "Signal invalid";
VAL_ 852 MHU_LA_sens 0 "Early" 1 "Normal" 2 "Late" 3 "Signal invalid";
VAL_ 852 MHU_LA_AudWarning 0 "OFF" 1 "ON" 2 "Reserved" 3 "Signal invalid";
VAL_ 852 MHU_BSD_On 0 "OFF" 1 "ON" 2 "Reserved" 3 "Signal invalid";
VAL_ 852 MHU_BSD_sens 0 "Early" 1 "Normal" 2 "Late" 3 "Signal invalid" ;
VAL_ 852 MHU_BSD_AudWarning 0 "OFF" 1 "ON" 2 "Reserved" 3 "Signal invalid";
VAL_ 852 MHU_RCTA_On 0 "OFF" 1 "ON" 2 "Reserved" 3 "Signal invalid";
VAL_ 852 MHU_RCTA_sens 0 "Early" 1 "Normal" 2 "Late" 3 "Signal invalid";
VAL_ 852 MHU_PA_On 0 "OFF" 1 "ON" 2 "Reserved" 3 "Signal invalid";
VAL_ 852 MHU_AHB_On 0 "OFF" 1 "ON" 2 "Reserved" 3 "Signal invalid";
VAL_ 852 MHU_IA_Mode 0 "OFF" 1 "ON" 2 "Reserved" 3 "Signal invalid";
VAL_ 852 MHU_TSR_Mode 0 "OFF" 1 "ON" 2 "Reserve" 3 "Signal invalid";
VAL_ 852 MHU_DOW_Mode 0 "OFF" 1 "Warning Only" 2 "Warning/Door Lock both" 3 "Signal invalid";
VAL_ 852 MHU_AHB_sens 0 "Early" 1 "Normal" 2 "Late" 3 "Signal invalid";
VAL_ 852 MHU_LA_Mode 0 "OFF" 1 "Warning only" 2 "Warning & Steer" 3 "Reserved" 4 "Signal Invalid";
VAL_ 852 MHU_SET_TSR_AudWarn 0 "OFF" 1 "ON" 2 "Reserved" 3 "Signal invalid";
VAL_ 852 MHU_SET_TSR_SLAert 0 "OFF" 1 "Speed Limit" 2 "Speed Limit + 5" 3 "Speed Limit + 10";
VAL_ 852 MHU_ESA_ON 0 "Off" 1 "On" ;
VAL_ 852 MHU_ELKA_ON 0 "OFF" 1 "ON" ;
VAL_ 852 MHU_ALC_ON 0 "OFF" 1 "ON" 2 "Reserved" 3 "Reserved" ;
VAL_ 853 ADAS_PAUSS_FaultFLO 0 "No fault" 1 "Fault";
VAL_ 853 ADAS_PAUSS_FaultFLI 0 "No fault" 1 "Fault";
VAL_ 853 ADAS_PAUSS_check 0 "Available" 1 "Temporarily not available" 2 "Permanently not available";
VAL_ 853 ADAS_PAUSS_FaultRLO 0 "No fault" 1 "Fault";
VAL_ 853 ADAS_PAUSS_FaultFRI 0 "No fault" 1 "Fault";
VAL_ 853 ADAS_FPA_check 0 "Available" 1 "Temporarily not available" 2 "Permanently not available";
VAL_ 853 ADAS_PAUSS_FaultRLI 0 "No fault" 1 "Fault";
VAL_ 853 ADAS_PAUSS_FaultRRO 0 "No fault" 1 "Fault";
VAL_ 853 ADAS_PAUSS_FaultRRI 0 "No fault" 1 "Fault";
VAL_ 853 ADAS_RPA_check 0 "Available" 1 "Temporarily not available" 2 "Permanently not available";
VAL_ 853 ADAS_PAUSS_FaultFRO 0 "No fault" 1 "Fault";
VAL_ 880 SBR_STAT_Chime 0 "Off" 1 "Durable" 2 "Blinking 3Hz" 3 "SNA";
VAL_ 880 SBR_STAT_Telltale 0 "No chime" 1 "1 Hz" 2 "3 Hz" 3 "SNA";
VAL_ 880 SBR_STAT_Active 0 "Not active" 1 "Active";
VAL_ 883 PDCU_PA_State 0 "OFF State" 1 "Standby State" 2 "Active State" 3 "Failed State" 4 "Reserved" 5 "Reserved" 6 "Reserved" 7 "Invalid" ;
VAL_ 883 PDCU_PA_AutoOn_Feed 0 "OFF" 1 "ON" ;
VAL_ 883 PDCU_PA_AlertFLI 0 "No warning" 1 "Warning level 1" 2 "Warning level 2" 3 "Warning level 3" 4 "Warning level 4" 5 "Warning level 5" 6 "Reserved" 7 "Error" ;
VAL_ 883 PDCU_PA_AlertFLO 0 "No warning" 1 "Warning level 1" 2 "Warning level 2" 3 "Warning level 3" 4 "Warning level 4" 5 "Warning level 5" 6 "Reserved" 7 "Error" ;
VAL_ 883 PDCU_PA_AlertFRI 0 "No warning" 1 "Warning level 1" 2 "Warning level 2" 3 "Warning level 3" 4 "Warning level 4" 5 "Warning level 5" 6 "Reserved" 7 "Error" ;
VAL_ 883 PDCU_PA_AlertFRO 0 "No warning" 1 "Warning level 1" 2 "Warning level 2" 3 "Warning level 3" 4 "Warning level 4" 5 "Warning level 5" 6 "Reserved" 7 "Error" ;
VAL_ 883 PDCU_PA_AlertRLI 0 "No warning" 1 "Warning level 1" 2 "Warning level 2" 3 "Warning level 3" 4 "Warning level 4" 5 "Warning level 5" 6 "Reserved" 7 "Error" ;
VAL_ 883 PDCU_PA_AlertRLO 0 "No warning" 1 "Warning level 1" 2 "Warning level 2" 3 "Warning level 3" 4 "Warning level 4" 5 "Warning level 5" 6 "Reserved" 7 "Error" ;
VAL_ 883 PDCU_PA_AlertRRI 0 "No warning" 1 "Warning level 1" 2 "Warning level 2" 3 "Warning level 3" 4 "Warning level 4" 5 "Warning level 5" 6 "Reserved" 7 "Error" ;
VAL_ 883 PDCU_PA_AlertRRO 0 "No warning" 1 "Warning level 1" 2 "Warning level 2" 3 "Warning level 3" 4 "Warning level 4" 5 "Warning level 5" 6 "Reserved" 7 "Error" ;
VAL_ 883 PDCU_PA_FPA_Check 0 "Available" 1 "Temporarily not available" 2 "Permanently not available" 3 "Invalid" ;
VAL_ 883 PDCU_PA_RPA_Check 0 "Available" 1 "Temporarily not available" 2 "Permanently not available" 3 "Invalid" ;
VAL_ 885 BMS_PreChgRelay_ERR 0 "error" 1 "normal";
VAL_ 885 BMS_TotalNegRelay_ERR 0 "Error" 1 "normal";
VAL_ 885 BMS_MainPosRelay_ERR 0 "Error" 1 "normal";
VAL_ 885 BMS_MainPosRelay_STS 0 "reserved" 1 "open" 2 "closed" 3 "stuck closed" 4 "stuck open";
VAL_ 885 BMS_PreChgRelay_STS 0 "reserved" 1 "open" 2 "closed" 3 "stuck closed" 4 "stuck open";
VAL_ 885 BMS_TotalNegRelay_STS 0 "reserved" 1 "open" 2 "closed" 3 "stuck closed" 4 "stuck open";
VAL_ 886 USS_RPA_state 0 "OFF State" 1 "Standby state" 2 "Active State" 3 "Temporary Failed State" 4 "permanent Failed State" 5 "Reserved" 6 "Reserved" 7 "Invalid";
VAL_ 886 USS_RPA_AlertRLI 0 "No warning" 1 "Warning level 1" 2 "Warning level 2" 3 "Warning level 3" 4 "Warning level 4" 5 "Warning level 5" 6 "Reserved" 7 "Invalid";
VAL_ 886 USS_RPA_AlertRLO 0 "No warning" 1 "Warning level 1" 2 "Warning level 2" 3 "Warning level 3" 4 "Warning level 4" 5 "Warning level 5" 6 "Reserved" 7 "Invalid";
VAL_ 886 USS_RPA_AlertRRI 0 "No warning" 1 "Warning level 1" 2 "Warning level 2" 3 "Warning level 3" 4 "Warning level 4" 5 "Warning level 5" 6 "Reserved" 7 "Invalid";
VAL_ 886 USS_RPA_AlertRRO 0 "No warning" 1 "Warning level 1" 2 "Warning level 2" 3 "Warning level 3" 4 "Warning level 4" 5 "Warning level 5" 6 "Reserved" 7 "Invalid";
VAL_ 886 USS_RPA_SensorRLI 0 "Sensor Normal" 1 "Sensor Unavailable temporarily" 2 "Sensor Fault" 3 "Invalid" ;
VAL_ 886 USS_RPA_SensorRLO 0 "Sensor Normal" 1 "Sensor Unavailable temporarily" 2 "Sensor Fault" 3 "Invalid" ;
VAL_ 886 USS_RPA_SensorRRI 0 "Sensor Normal" 1 "Sensor Unavailable temporarily" 2 "Sensor Fault" 3 "Invalid" ;
VAL_ 886 USS_RPA_SensorRRO 0 "Sensor Normal" 1 "Sensor Unavailable temporarily" 2 "Sensor Fault" 3 "Invalid" ;
VAL_ 887 USS_FPA_state 0 "OFF State" 1 "Standby state" 2 "Active State" 3 "Temporary Failed State" 4 "permanent Failed State" 5 "Reserved" 6 "Reserved" 7 "Invalid";
VAL_ 887 USS_FPA_AutoOn_Feed 0 "OFF" 1 "ON" ;
VAL_ 887 USS_FPA_AlertFLI 0 "No warning" 1 "Warning level 1" 2 "Warning level 2" 3 "Warning level 3" 4 "Warning level 4" 5 "Warning level 5" 6 "Reserved" 7 "Invalid";
VAL_ 887 USS_FPA_AlertFLO 0 "No warning" 1 "Warning level 1" 2 "Warning level 2" 3 "Warning level 3" 4 "Warning level 4" 5 "Warning level 5" 6 "Reserved" 7 "Invalid";
VAL_ 887 USS_FPA_AlertFRI 0 "No warning" 1 "Warning level 1" 2 "Warning level 2" 3 "Warning level 3" 4 "Warning level 4" 5 "Warning level 5" 6 "Reserved" 7 "Invalid";
VAL_ 887 USS_FPA_AlertFRO 0 "No warning" 1 "Warning level 1" 2 "Warning level 2" 3 "Warning level 3" 4 "Warning level 4" 5 "Warning level 5" 6 "Reserved" 7 "Invalid";
VAL_ 887 USS_FPA_SensorFLI 0 "Sensor Normal" 1 "Sensor Unavailable temporarily" 2 "Sensor Fault" 3 "Invalid" ;
VAL_ 887 USS_FPA_SensorFLO 0 "Sensor Normal" 1 "Sensor Unavailable temporarily" 2 "Sensor Fault" 3 "Invalid" ;
VAL_ 887 USS_FPA_SensorFRI 0 "Sensor Normal" 1 "Sensor Unavailable temporarily" 2 "Sensor Fault" 3 "Invalid" ;
VAL_ 887 USS_FPA_SensorFRO 0 "Sensor Normal" 1 "Sensor Unavailable temporarily" 2 "Sensor Fault" 3 "Invalid" ;
VAL_ 897 ACM_Seat_Occupancy_Passenger 0 "Seat_Not_Occupied" 1 "Seat Occupied" 2 "Not_Available" 3 "Failure";
VAL_ 897 ACM_Seat_Occupancy_2nd_Row_Dri 0 "Seat_Not_Occupied" 1 "Seat Occupied" 2 "Not_Available" 3 "Failure";
VAL_ 897 ACM_Seat_Occupancy_2nd_Row_Pas 0 "Seat_Not_Occupied" 1 "Seat Occupied" 2 "Not_Available" 3 "Failure";
VAL_ 897 ACM_Seat_Occupancy_2nd_Row_Mid 0 "Seat_Not_Occupied" 1 "Seat Occupied" 2 "Not_Available" 3 "Failure";
VAL_ 897 ACM_Seat_Belt_Status_Passenger 0 "Not_buckled" 1 "Buckled" 2 "Not_Available" 3 "Failure";
VAL_ 897 ACM_Seat_Belt_Status_Driver 0 "Not_buckled" 1 "Buckled" 2 "Not_Available" 3 "Failure";
VAL_ 897 ACM_Seat_Belt_Status_2nd_Row_Dri 0 "Not_buckled" 1 "Buckled" 2 "Not_Available" 3 "Failure";
VAL_ 897 ACM_Seat_Belt_Status_2nd_Row_Mid 0 "Not_buckled" 1 "Buckled" 2 "Not_Available" 3 "Failure";
VAL_ 897 ACM_Seat_Belt_Status_2nd_Row_Pas 0 "Not_buckled" 1 "Buckled" 2 "Not_Available" 3 "Failure";
VAL_ 905 VCU_IMMO_Sts 0 "init" 1 "pass" 2 "failed";
VAL_ 915 MHU_SET_HudRotateLvl 0 "Invalid" 1 "Level 1" 2 "Level 2" 3 "Level 3" 4 "Level 4" 5 "Level 5" 6 "Level 6" 7 "Level 7" 8 "Level 8" 9 "Level 9" 10 "Level 10" 11 "Level 11" 12 "Level 12" 13 "Level 13" 14 "Level 14" 15 "Level 15";
VAL_ 915 MHU_SET_HudHeightLvl 0 "Invalid" 1 "Level 1" 2 "Level 2" 3 "Level 3" 4 "Level 4" 5 "Level 5" 6 "Level 6" 7 "Level 7" 8 "Level 8" 9 "Level 9" 10 "Level 10" 11 "Level 11" 12 "Level 12" 13 "Level 13" 14 "Level 14" 15 "Level 15" 16 "Level 16" 17 "Level 17" 18 "Level 18" 19 "Level 19" 20 "Level 20" 21 "Level 21" 22 "Reserved";
VAL_ 925 BCM_ADAS_AHB_state 0 "OFF State" 1 "HighBeam Passive or Inactive" 2 "HighBeam Active" 3 "Fault" ;
VAL_ 925 BCM_AHB_Override 0 "not used" 1 "Automatic High Beam request" 2 "AHB  Inhibit by Driver" 3 "invalid";
VAL_ 925 BCM_ADAS_AHB_RBPos_feed 0 "Off or low beam" 1 "high beam" 2 "Reserved" 3 "Reserved" 4 "Reserved" 5 "Reserved" 6 "Reserved" 7 "Reserved" ;
VAL_ 925 BCM_ADAS_AHB_LBPos_feed 0 "Off or low beam" 1 "high beam" 2 "Reserved" 3 "Reserved" 4 "Reserved" 5 "Reserved" 6 "Reserved" 7 "Reserved" ;
VAL_ 925 BCM_AHB_ICON_Feed 0 "Off" 1 "Gray ICON" 2 "Green ICON" 3 "White ICON" 4 "Yellow ICON" 5 "Red ICON" ;
VAL_ 943 MHU_IPC_ID 0 "Media OFF" 1 "Telephone Name / Number" 2 "Reserved" 3 "USB - Songname, Album, Artist" 4 "BT - Songname, Album, Artist" 5 "IPOD - Songname, Album, Artist" 6 "Radio frequency AM" 7 "Radio frequency FM" 8 "Radio station" 9 "USB Video" 10 "USB Picture" 11 "Android Auto" 12 "Apple Carplay" 13 "Device not connected" 14 "Loading" 15 "Invalid";
VAL_ 964 MHU_Nav_State 0 "Disable" 1 "ON" 2 "Ready to drive" 3 "Arrived at the destination - Finish" 4 "Locating  Location position not avaliable" 5 "Rerouting" 6 "On the way" 7 "Signal Invalid";
VAL_ 964 MHU_NavSource 0 "Here Map (Default embedded map)" 1 "Vietmap" 2 "Apple Map" 3 "Google map " 4 "Reserved" 5 "Reserved" 6 "Reserved" 7 "Signal Invalid";
VAL_ 964 MHU_Nav_DistanceToNextTurnUnits 0 "km" 1 "miles" 2 "m" 3 "yards" 4 "ft" 5 "Reserved" 6 "Reserved" 7 "Reserved";
VAL_ 964 MHU_Nav_ImageChannel_Ready 0 "Disable" 1 "Enable" 2 "Power Off" 3 "Signal Invalid";
VAL_ 964 MHU_Nav_Language 0 "Vietnamese" 1 "English" 2 "Chinese (Simplified)" 3 "Traditional Chinese" 4 "French" 5 "German" 6 "Italian" 7 "Japanese" 8 "Korean" 9 "Spanish (Spain)" 10 "Spanish (Latin)" 11 "Portuguese (Portugal)" 12 "Portuguese (Brazil)" 13 "Arabic" 14 "Catalan" 15 "Croatian" 16 "Czech" 17 "Danish" 18 "Dutch" 19 "Finnish" 20 "Greek" 21 "Hebrew" 22 "Hindi" 23 "Hungarian" 24 "Indonesian" 25 "Malay" 26 "Norwegian" 27 "Polish" 28 "Romanian" 29 "Russian" 30 "Slovak" 31 "Swedish" 32 "Turkish" 33 "Thai" 254 "Raw language" 255 "Signal invalid";
VAL_ 992 VCU_RunningRange_chrg_estSts 0 "Not ready" 1 "Processing" 2 "Estimated" 3 "Failed";
VAL_ 992 VCU_HVbatSoc_charged_estStatus 0 "Not ready" 1 "Processing" 2 "Estimated" 3 "Failed";
VAL_ 993 VCU_SetCruiseSpd 255 "Signal Invalid";
VAL_ 993 VCU_CruiseCtrlSts 0 "OFF" 1 "Standby" 2 "Active" 3 "Override" 4 "Fault" 5 "Reserved" 6 "Reserved" ;
VAL_ 993 VCU_MHU_Ack_ChgSche_stt 0 "Charging Schedule Enable" 1 "Charging Schedule Disable" 2 "Reserved" 3 "Signal Invalid";
VAL_ 993 VCU_ValetMode_sts 0 "Inactive" 1 "Active" 255 "Invalid";
VAL_ 1015 MFS_VoiceRecognitionOn_Off 0 "Button not Pressed" 1 "Short Press" 2 "Long Press" 3 "Reserved" 4 "Signal invalid";
VAL_ 1015 MFS_ISAControl 0 "Button not Pressed" 1 "Short Press" 2 "Long Press" 3 "Signal invalid";
VAL_ 1015 MFS_CruiseSpeedIncrease 0 "Button not Pressed" 1 "Short Press" 2 "Long Press" 3 "Reserved" 4 "Signal invalid";
VAL_ 1015 MFS_TelephoneCall_EndCall 0 "Button not Pressed" 1 "Short Press" 2 "Long Press" 3 "Reserved" 4 "Signal invalid";
VAL_ 1015 MFS_LKAControl 0 "Button not Pressed" 1 "Short Press" 2 "Long Press" 3 "Signal invalid";
VAL_ 1015 MFS_CruiseGapIncrease 0 "Button not Pressed" 1 "Short Press" 2 "Long Press" 3 "Reserved" 4 "Signal invalid";
VAL_ 1015 MFS_CruiseOn_Off 0 "Button not Pressed" 1 "Short Press" 2 "Long Press" 3 "Reserved" 4 "Signal invalid";
VAL_ 1015 MFS_CruiseGapDecrease 0 "Button not Pressed" 1 "Short Press" 2 "Long Press" 3 "Reserved" 4 "Signal invalid";
VAL_ 1015 MFS_CAN_RESControl 0 "Button not Pressed" 1 "Short Press" 2 "Long Press" 3 "Reserved";
VAL_ 1015 MFS_CruiseSpeedDecrease 0 "Button not Pressed" 1 "Short Press" 2 "Long Press" 3 "Reserved" 4 "Signal invalid";
VAL_ 1015 MFS_M2Control 0 "Button not Pressed" 1 "Short Press" 2 "Long Press" 3 "Signal invalid";
VAL_ 1015 MFS_SourseControl 0 "Button not Pressed" 1 "Short Press" 2 "Long Press" 3 "Reserved" 4 "Signal invalid";
VAL_ 1015 MFS_UpControl 0 "Button not Pressed" 1 "Short Press" 2 "Long Press" 3 "Reserved" 4 "Signal invalid";
VAL_ 1015 MFS_DownControl 0 "Button not Pressed" 1 "Short Press" 2 "Long Press" 3 "Reserved" 4 "Signal invalid";
VAL_ 1015 MFS_LeftControl 0 "Button not Pressed" 1 "Short Press" 2 "Long Press" 3 "Reserved" 4 "Signal invalid";
VAL_ 1015 MFS_Failure 0 "No Error" 1 "Error";
VAL_ 1015 MFS_RightControl 0 "Button not Pressed" 1 "Short Press" 2 "Long Press" 3 "Reserved" 4 "Signal invalid";
VAL_ 1015 MFS_OK_Control 0 "Button not Pressed" 1 "Short Press" 2 "Long Press" 3 "Reserved" 4 "Signal invalid";
VAL_ 1020 XGW_FOTA_StateConfirm 0 "INIT" 1 "NORMAL" 2 "FOTA FLASHING" 3 "FOTA-SUSPENDED" 4 "FAIL-SAFE-ERROR" 5 "SHUTDOWN" 6 "REMOTE DIAGNOSTICS" 7 "Invalid";
VAL_ 1025 MHU_SET_SunroofGlassLevel 0 "Closed" 127 "Vent" 150 "Stop" 255 "No Request";
VAL_ 1025 MHU_SET_BonnetState 0 "Not pressed" 1 "Pressed" 2 "Reserved" 3 "Signal invalid";
VAL_ 1025 MHU_SET_TrunkState 0 "Not pressed" 1 "Pressed" 2 "Reserved" 3 "Signal invalid";
VAL_ 1025 MHU_SET_SunroofShaderLevel 0 "Closed" 150 "Stop" 255 "No Request";
VAL_ 1025 MHU_SET_DoorSpeedLock 0 "OFF" 1 "5KMH" 2 "10KMH" 3 "15KMH" 4 "20KMH" 5 "25KMH" 6 "Signal invalid";
VAL_ 1025 MHU_SET_WelcomeTriggerCondition 0 "Vehicle unLock" 1 "Driver walk toward" 2 "OFF" 3 "Signal invalid";
VAL_ 1025 MHU_SET_AutoSunroof 0 "OFF" 1 "Glass Only" 2 "Glass & Shade" 3 "Signal invalid";
VAL_ 1025 MHU_SET_RemoteDoorUnlock 0 "Driver door" 1 "All doors" 2 "Reserved" 3 "Signal invalid";
VAL_ 1025 MHU_SET_RemoteLockFeedback 0 "Light" 1 "Horn" 2 "Light/Horn" 3 "OFF" 4 "Signal Invalid";
VAL_ 1025 MHU_SET_FootkickSensor 0 "OFF" 1 "ON" 2 "Reserved" 3 "Signal invalid";
VAL_ 1025 MHU_SET_AutoUnlockDoor 0 "OFF" 1 "On" 2 "Reserved" 3 "Signal Invalid";
VAL_ 1025 MHU_SET_RemoteUnlockFeedback 0 "Blinking" 1 "Dimming" 2 "Low Beam ON" 3 "OFF" 4 "Signal Invalid";
VAL_ 1025 WalkawayDoorLock 0 "OFF" 1 "ON";
VAL_ 1025 MHU_SET_Childlock 0 "OFF" 1 "ON" 2 "Reserved" 3 "Signal invalid";
VAL_ 1025 MHU_SET_SunroofInitialize 0 "Inactive - Default" 1 "Initialisation" 2 "Manual Open Sunroof" 3 "Manual Close Sunroof" 4 "Manual Open Sunshade" 5 "Manuel Close Sunshade" 6 "Reserved" 7 "Signal invalid";
VAL_ 1026 MHU_SET_DayTimeRunningLight 0 "OFF" 1 "ON" 2 "Reserved" 3 "Signal invalid";
VAL_ 1026 MHU_SET_RearFogLight 0 "OFF" 1 "ON" 2 "Reserved" 3 "Signal invalid";
VAL_ 1026 MHU_SET_FrontFogLight 0 "OFF" 1 "ON" 2 "Reserved" 3 "Signal invalid";
VAL_ 1026 MHU_SET_WelcomeDimmingHeadlight 0 "OFF" 1 "ON" 2 "Reserved" 3 "Signal invalid";
VAL_ 1026 MHU_SET_FootwellLightMode 0 "OFF" 1 "ON" 2 "AUTO" 3 "Signal invalid";
VAL_ 1026 MHU_SET_ExteriorLight 0 "OFF" 1 "Parking" 2 "ON" 3 "AUTO" 4 "Signal invalid";
VAL_ 1026 MHU_SET_TRWarningSignals 0 "Off BCM warning signals" 1 "On BCM warning signals" 2 "Reserved" 3 "Signal Invalid";
VAL_ 1026 MHU_SET_FrontDomeLamp 0 "OFF" 1 "ON" 2 "AUTO" 3 "Signal invalid";
VAL_ 1026 MHU_SET_HazardLight 3 "Signal Invalid" 2 "Reserved" 1 "ON" 0 "OFF" ;
VAL_ 1026 MHU_SET_FollowMeHome 0 "OFF" 1 "30 secs" 2 "60 secs" 3 "90 secs" 4 "120 secs" 5 "Signal invalid";
VAL_ 1026 MHU_SET_ADB_AHB 0 "OFF" 1 "ON" 2 "Reserved" 3 "Signal Invalid";
VAL_ 1026 MHU_SET_WelcomeAnimation 0 "OFF" 1 "Light dance" 2 "Vegas blink" 3 "Pulse and blink" 4 "Reserved" 5 "Signal invalid";
VAL_ 1026 MHU_SET_ChargingAnimation 0 "OFF" 1 "ON" 2 "Reserved" 3 "Signal invalid";
VAL_ 1026 MHU_SET_Auto_Leveling 0 "OFF" 1 "ON" 2 "Reserved" 3 "Signal Invalid";
VAL_ 1027 MHU_VCU_CreepDisable_stt 0 "No request" 1 "Creep Disable request";
VAL_ 1027 MHU_AutoP_Setting 3 "Signal Invalid" 2 "Reserved" 1 "OFF" 0 "ON" ;
VAL_ 1027 MHU_BrakeRegenMode 0 "HIGH" 1 "MID" 2 "LOW" 3 "OFF";
VAL_ 1027 MHU_ChargeScheduleSet 0 "disable" 1 "Enable" 2 "No effect" 3 "Invalid";
VAL_ 1027 MHU_ChargingRequest 0 "Stop charging" 1 "Start charging" 2 "Pause charging" 3 "No effect";
VAL_ 1027 MHU_ChgPort_Open_req 0 "No request" 1 "Requesting" 2 "Reserved" 3 "Signal invalid";
VAL_ 1027 MHU_SET_DrivingModeSwitch 0 "NORMAL" 1 "ECO" 2 "SPORT" 3 "Signal invalid";
VAL_ 1027 MHU_ValetMode_Activation 0 "Inactive" 1 "Active" 2 "No effect" 255 "Invalid";
VAL_ 1027 MHU_SET_ActivePreCondition 0 "OFF" 1 "ON" 2 "Reserved" 3 "Reserved";
VAL_ 1027 MHU_SpdLim_Override 0 "OFF" 1 "10km/h" 2 "20km/h" 3 "30km/h" 4 "Reserved" 5 "Invalid";
VAL_ 1028 MHU_SET_MirrorAdjustLeft 0 "OFF" 1 "ON" 2 "Reserved" 3 "Signal invalid";
VAL_ 1028 MHU_SET_MirrorAdjustRight 0 "OFF" 1 "ON" 2 "Reserved" 3 "Signal invalid";
VAL_ 1028 MHU_SET_MirrorManual 0 "Fold" 1 "Unfold" 2 "Reserved" 3 "Signal invalid";
VAL_ 1029 MHU_SET_CCUF_AirCondition 0 "Not pressed" 1 "Pressed" 2 "Reserved" 3 "Signal invalid";
VAL_ 1029 MHU_SET_CCUF_AutoAC 0 "Not pressed" 1 "Pressed" 2 "Reserved" 3 "Signal invalid";
VAL_ 1029 MHU_SET_CCUF_MaxAc 0 "Not pressed" 1 "Pressed" 2 "Reserved" 3 "Signal invalid";
VAL_ 1029 MHU_SET_CCUF_FanSpeed 0 "OFF" 1 "Level1" 2 "Level2" 3 "Level3" 4 "Level4" 5 "Level5" 6 "Level6" 7 "Signal invalid" ;
VAL_ 1029 MHU_SET_CCUF_Recirculation 0 "Inside" 1 "Outside" 2 "Auto" 3 "Signal invalid" ;
VAL_ 1029 MHU_SET_CCUF_Ion 0 "Not pressed" 1 "Pressed" 2 "Reserved" 3 "Signal invalid";
VAL_ 1029 MHU_SET_CCUF_FlapPosition 0 "OFF" 1 "Face" 2 "Face and Feet" 3 "Feet" 4 "Feet and Defrost" 5 "Defrost" 6 "Default" 7 "Signal Invalid" ;
VAL_ 1029 MHU_SET_CCUF_SyncClimateZone 0 "Not pressed" 1 "Pressed" 2 "Reserved" 3 "Signal invalid";
VAL_ 1029 MHU_SET_CCUF_TempDriver 32 "16" 33 "16.5" 34 "17" 35 "17.5" 36 "18" 37 "18.5" 38 "19" 39 "19.5" 40 "20" 41 "20.5" 42 "21" 43 "21.5" 44 "22" 45 "22.5" 46 "23" 47 "23.5" 48 "24" 49 "24.5" 50 "25" 51 "25.5" 52 "26" 53 "26.5" 54 "27" 55 "27.5" 56 "28" 57 "28.5" 58 "29" 59 "29.5" 60 "30" 61 "30.5" 62 "31" 63 "31.5" 64 "32" 255 "Invalid Value";
VAL_ 1029 MHU_SET_CCUF_TempPassenger 32 "16" 33 "16.5" 34 "17" 35 "17.5" 36 "18" 37 "18.5" 38 "19" 39 "19.5" 40 "20" 41 "20.5" 42 "21" 43 "21.5" 44 "22" 45 "22.5" 46 "23" 47 "23.5" 48 "24" 49 "24.5" 50 "25" 51 "25.5" 52 "26" 53 "26.5" 54 "27" 55 "27.5" 56 "28" 57 "28.5" 58 "29" 59 "29.5" 60 "30" 61 "30.5" 62 "31" 63 "31.5" 64 "32" 255 "Invalid Value";
VAL_ 1029 MHU_SET_CCUF_FrontDefrost 0 "Not pressed" 1 "Pressed" 2 "Reserved" 3 "Signal invalid";
